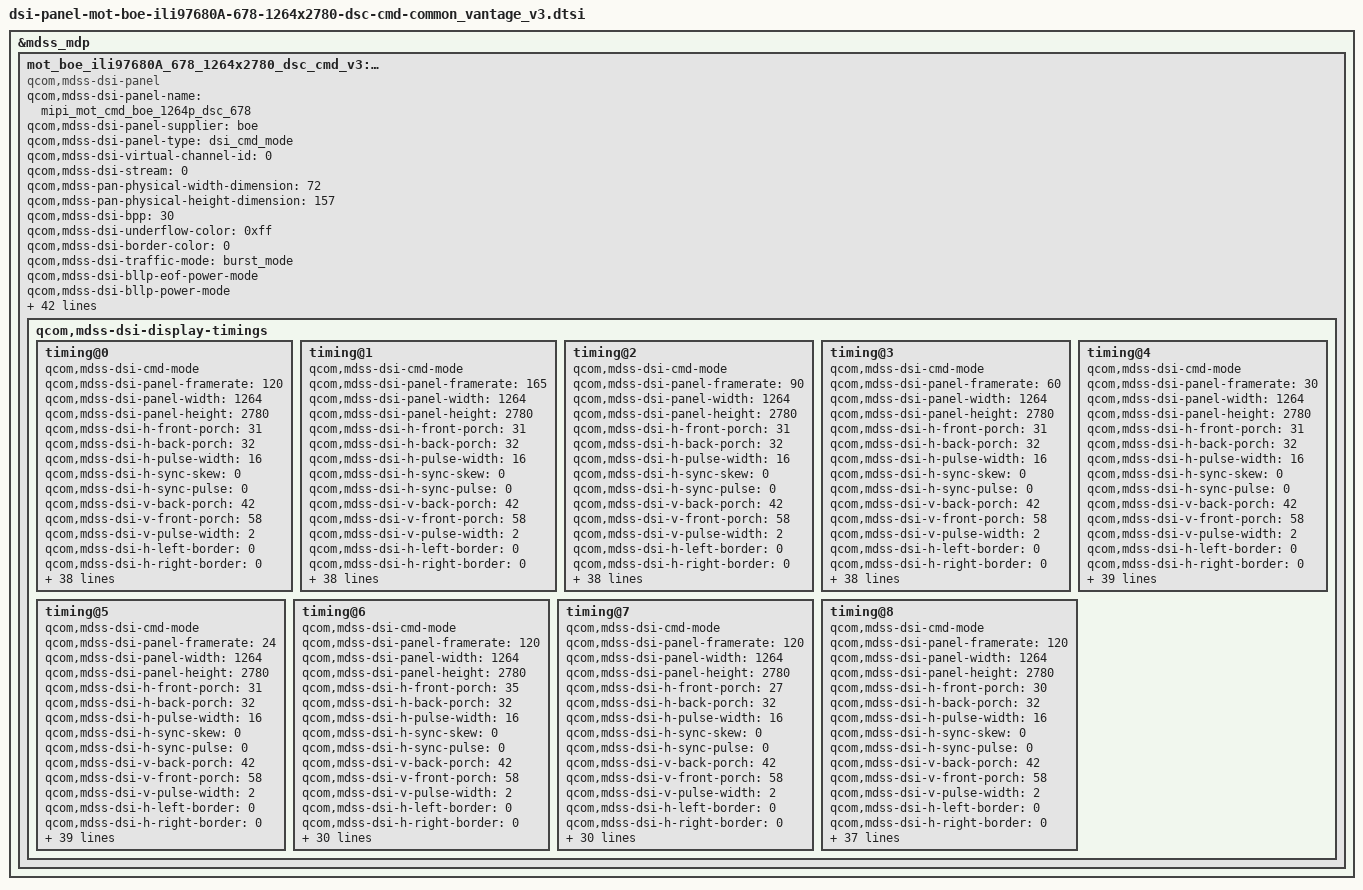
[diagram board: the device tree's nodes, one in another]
/* Copyright (c) 2025-2026, The Linux Foundation. All rights reserved.
 *
 * This program is free software; you can redistribute it and/or modify
 * it under the terms of the GNU General Public License version 2 and
 * only version 2 as published by the Free Software Foundation.
 *
 * This program is distributed in the hope that it will be useful,
 * but WITHOUT ANY WARRANTY; without even the implied warranty of
 * MERCHANTABILITY or FITNESS FOR A PARTICULAR PURPOSE.  See the
 * GNU General Public License for more details.
 */
&mdss_mdp {
mot_boe_ili97680A_678_1264x2780_dsc_cmd_v3: qcom,mdss_dsi_mot_boe_ili97680A_678_1264x2780_dsc_cmd_v3 {
compatible = "qcom,mdss-dsi-panel";
qcom,mdss-dsi-panel-name = "mipi_mot_cmd_boe_1264p_dsc_678";
qcom,mdss-dsi-panel-supplier = "boe";
qcom,mdss-dsi-panel-type = "dsi_cmd_mode";
qcom,mdss-dsi-virtual-channel-id = <0>;
qcom,mdss-dsi-stream = <0>;
qcom,mdss-pan-physical-width-dimension = <72>;
qcom,mdss-pan-physical-height-dimension = <157>;
qcom,mdss-dsi-bpp = <30>;
qcom,mdss-dsi-underflow-color = <0xff>;
qcom,mdss-dsi-border-color = <0>;

qcom,mdss-dsi-traffic-mode = "burst_mode";
qcom,mdss-dsi-bllp-eof-power-mode;
qcom,mdss-dsi-bllp-power-mode;
qcom,mdss-dsi-lane-0-state;
qcom,mdss-dsi-lane-1-state;
qcom,mdss-dsi-lane-2-state;
qcom,mdss-dsi-lane-3-state;

qcom,mdss-dsi-dma-trigger = "trigger_sw";
qcom,mdss-dsi-mdp-trigger = "none";
qcom,mdss-dsi-reset-sequence = <0 3>, <1 1>, <0 1>, <1 20>;
qcom,mdss-dsi-lp11-init;
qcom,mdss-dsi-tx-eot-append;
qcom,mdss-dsi-te-pin-select = <1>;
qcom,mdss-dsi-te-dcs-command = <1>;
qcom,mdss-dsi-te-using-te-pin;

//qcom,bklt-dcs-2bytes-enabled;
qcom,mdss-dsi-bl-min-level = <4>;
qcom,mdss-dsi-bl-max-level = <14056>;
qcom,mdss-dsi-bl-pmic-control-type = "bl_ctrl_dcs";

qcom,mdss-dsi-panel-hdr-enabled;
qcom,mdss-dsi-panel-hdr-color-primaries = <14500 15500 32000
	        17000 15500 30000 8000 3000>;
qcom,mdss-dsi-panel-peak-brightness = <4200000>;

qcom,mdss-dsi-panel-blackness-level = <3230>;

qcom,check_pcd;
qcom,pcd-reg-read-enabled;
qcom,pcd-reg-check-before-read;
qcom,mdss-dsi-panel-pcd-reg-read-length = <1>;
qcom,mdss-dsi-panel-pcd-reg-mask = <0xFF>;
qcom,mdss-dsi-panel-pcd-reg-command = [
		06 01 00 01 00 00 01 C5];
qcom,mdss-dsi-panel-pcd-reg-pass-min = <0x0>;
qcom,mdss-dsi-panel-pcd-reg-pass-max = <0x29>;
qcom,mdss-dsi-panel-pcd-reg-read-delay-ms = <0>; //150ms delay before read pcd reg per IC req
qcom,mdss-dsi-panel-pcd-reg-seq-interval = <30>; //30 seq interval per screen on times
qcom,mdss-dsi-panel-pcd-check-time-interval-in-minutes = <480>; //480 minutes check time interval for pcd reg read

qcom,mdss-dsi-dc-off-command = [
			39 00 00 40 00 00 04 FF 5A A5 4F
			39 00 00 40 00 00 02 81 0C
			39 00 00 40 00 00 02 82 7F
			39 00 00 40 00 00 04 FF 5A A5 08
			39 00 00 40 00 00 02 98 02
			39 00 00 40 00 00 04 FF 5A A5 4F
			39 00 00 40 00 00 02 88 78
			39 00 00 40 00 00 04 FF 5A A5 24
			39 00 00 40 00 00 05 91 01 27 34 56
			39 00 00 40 00 00 04 FF 5A A5 24
			39 00 00 40 00 00 02 9D 0E
			39 00 00 40 00 00 02 9E 11
			39 00 00 40 00 00 04 FF 5A A5 23
			39 00 00 40 00 00 02 80 50
			39 00 00 40 00 00 04 FF 5A A5 53
			39 00 00 40 00 00 03 85 CC E1
			39 00 00 40 00 00 02 86 3D
			39 00 00 40 00 00 03 95 60 66
			39 00 00 40 00 00 04 FF 5A A5 51
			39 00 00 40 00 00 06 A1 AC AC AC AC 22
			39 00 00 40 00 00 02 FE 22
			39 00 00 40 00 00 06 A2 AC A5 A5 A5 22
			39 00 00 40 00 00 02 FE 22
			39 00 00 40 00 00 06 A3 A5 98 98 98 22
			39 00 00 40 00 00 02 FE 22
			39 00 00 40 00 00 04 FF 5A A5 52
			39 00 00 40 00 00 06 81 E2 94 77 77 00
			39 00 00 40 00 00 02 FE 00
			39 00 00 40 00 00 06 82 77 76 76 76 00
			39 00 00 40 00 00 02 FE 00
			39 00 00 40 00 00 06 83 76 6E 6E 6E 00
			39 00 00 40 00 00 02 FE 00
			39 00 00 40 00 00 04 FF 5A A5 4F
			39 00 00 40 00 00 02 81 04
			39 00 00 40 00 00 04 FF 5A A5 08
			39 00 00 40 00 00 02 98 A6
			39 00 00 40 00 00 04 FF 5A A5 00
			39 00 00 40 00 00 02 00 00
			39 00 00 40 00 00 04 FF 5A A5 4F
			39 00 00 40 00 00 02 8B 78
			39 00 00 00 00 00 04 FF 5A A5 00
		];

qcom,mdss-dsi-dc-off-command-state = "dsi_hs_mode";
qcom,mdss-dsi-dc-on-command = [
			39 00 00 40 00 00 04 FF 5A A5 4F
			39 00 00 40 00 00 02 81 0C
			39 00 00 40 00 00 02 82 7F
			39 00 00 40 00 00 04 FF 5A A5 08
			39 00 00 40 00 00 02 98 02
			39 00 00 40 00 00 04 FF 5A A5 4F
			39 00 00 40 00 00 02 88 78
			39 00 00 40 00 00 04 FF 5A A5 24
			39 00 00 40 00 00 05 91 11 77 44 66
			39 00 00 40 00 00 04 FF 5A A5 24
			39 00 00 40 00 00 02 9D 8E
			39 00 00 40 00 00 02 9E 11
			39 00 00 40 00 00 04 FF 5A A5 23
			39 00 00 40 00 00 02 80 90
			39 00 00 40 00 00 04 FF 5A A5 53
			39 00 00 40 00 00 03 85 CC E3
			39 00 00 40 00 00 02 86 3D
			39 00 00 40 00 00 03 95 88 88
			39 00 00 40 00 00 04 FF 5A A5 51
			39 00 00 40 00 00 06 A1 B2 B2 B5 AE 22
			39 00 00 40 00 00 02 FE 22
			39 00 00 40 00 00 06 A2 AE AC AC AB 22
			39 00 00 40 00 00 02 FE 22
			39 00 00 40 00 00 06 A3 AA 98 98 98 22
			39 00 00 40 00 00 02 FE 22
			39 00 00 40 00 00 04 FF 5A A5 52
			39 00 00 40 00 00 06 81 E3 94 77 77 00
			39 00 00 40 00 00 02 FE 00
			39 00 00 40 00 00 06 82 77 77 77 77 00
			39 00 00 40 00 00 02 FE 00
			39 00 00 40 00 00 06 83 77 6E 6E 6E 00
			39 00 00 40 00 00 02 FE 00
			39 00 00 40 00 00 04 FF 5A A5 4F
			39 00 00 40 00 00 02 81 04
			39 00 00 40 00 00 04 FF 5A A5 08
			39 00 00 40 00 00 02 98 A6
			39 00 00 40 00 00 04 FF 5A A5 00
			39 00 00 40 00 00 02 00 00
			39 00 00 40 00 00 04 FF 5A A5 4F
			39 00 00 40 00 00 02 8B 78
			39 00 00 00 00 00 04 FF 5A A5 00
		];
qcom,mdss-dsi-dc-on-command-state = "dsi_hs_mode";
//qcom,mdss-dsi-nt37705-dc-detect-fps;
//qcom,check_pcd;

qcom,mdss-dsi-display-timings {
	timing@0{
		qcom,mdss-dsi-cmd-mode;
		qcom,mdss-dsi-panel-framerate = <120>;
		qcom,mdss-dsi-panel-width = <1264>;
		qcom,mdss-dsi-panel-height = <2780>;
		qcom,mdss-dsi-h-front-porch = <31>;
		qcom,mdss-dsi-h-back-porch = <32>;
		qcom,mdss-dsi-h-pulse-width = <16>;
		qcom,mdss-dsi-h-sync-skew = <0>;
		qcom,mdss-dsi-h-sync-pulse = <0>;
		qcom,mdss-dsi-v-back-porch = <42>;
		qcom,mdss-dsi-v-front-porch = <58>;
		qcom,mdss-dsi-v-pulse-width = <2>;
		qcom,mdss-dsi-h-left-border = <0>;
		qcom,mdss-dsi-h-right-border = <0>;
		qcom,mdss-dsi-v-top-border = <0>;
		qcom,mdss-dsi-v-bottom-border = <0>;
	        qcom,mdss-dsi-panel-jitter = <0x20 0xa>;
	        qcom,mdss-dsi-timing-switch-command = [
			39 00 00 40 00 00 04 FF 5A A5 00
			39 00 00 40 00 00 02 53 20
			39 00 00 40 00 00 02 60 00
			39 00 00 40 00 00 04 FF 5A A5 24
			39 00 00 40 00 00 02 86 00
			39 00 00 40 00 00 02 8A 00
			39 00 00 40 00 00 04 FF 5A A5 2D
			39 00 00 40 00 00 03 98 00 00
			39 00 00 40 00 00 02 CD 01
			39 00 00 40 00 00 03 83 00 00
			39 00 00 40 00 00 02 F2 00 // 120Hz Frame Skip mode Exit
			39 00 00 40 00 00 04 FF 5A A5 53
			39 00 00 40 00 00 02 86 3D //Exit 165 DC code
			39 00 00 00 00 00 04 FF 5A A5 00
	        ];
		qcom,mdss-dsi-on-command = [
			39 00 00 40 00 00 04 FF 5A A5 00 //ODC dbv420 and 10nit
			39 00 00 40 00 00 02 4D 01
			39 00 00 40 00 00 04 FF 5A A5 4F
			39 00 00 40 00 00 02 A1 00
			39 00 00 40 00 00 02 A2 01
			39 00 00 40 00 00 02 A3 A4
			39 00 00 40 00 00 02 A4 0A
			39 00 00 40 00 00 02 A5 48
			39 00 00 40 00 00 04 FF 5A A5 71
			39 00 00 40 00 00 07 85 00 80 0A F3 00 00
			39 00 00 40 00 00 07 86 00 66 09 8F 04 00
			39 00 00 40 00 00 07 87 00 60 09 36 14 00
			39 00 00 40 00 00 07 88 00 53 08 84 24 00
			39 00 00 40 00 00 07 89 00 46 07 D2 04 00
			39 00 00 40 00 00 07 8A 00 80 18 B3 00 00
			39 00 00 40 00 00 07 8B 00 66 17 C2 04 00
			39 00 00 40 00 00 07 8C 00 60 17 86 14 00
			39 00 00 40 00 00 07 8D 00 53 17 0E 24 00
			39 00 00 40 00 00 07 8E 00 46 16 95 04 00
			39 00 00 40 00 00 07 8F 00 80 26 00 00 00
			39 00 00 40 00 00 07 90 00 66 25 99 04 00
			39 00 00 40 00 00 07 91 00 60 25 80 14 00
			39 00 00 40 00 00 07 92 00 53 25 4C 24 00
			39 00 00 40 00 00 07 93 00 46 25 19 04 00
			39 00 00 40 00 00 07 94 00 80 04 00 00 00
			39 00 00 40 00 00 07 95 00 66 04 00 04 00
			39 00 00 40 00 00 07 96 00 60 04 00 14 00
			39 00 00 40 00 00 07 97 00 53 04 00 24 00
			39 00 00 40 00 00 07 98 00 46 04 00 04 00
			39 00 00 40 00 00 07 99 0C 19 00 80 00 00
			39 00 00 40 00 00 07 9A 0A 7B 00 66 04 00
			39 00 00 40 00 00 07 9B 0A 13 00 60 14 00
			39 00 00 40 00 00 07 9C 09 43 00 53 24 00
			39 00 00 40 00 00 07 9D 08 74 00 46 04 00
			39 00 00 40 00 00 07 9E 04 00 0A 00 00 00
			39 00 00 40 00 00 07 A3 04 00 16 80 00 00
			39 00 00 40 00 00 07 A4 04 00 16 00 04 00
			39 00 00 40 00 00 07 B2 19 EC 00 80 00 00
			39 00 00 40 00 00 07 B3 18 BD 00 66 04 00
			39 00 00 40 00 00 07 B4 18 71 00 60 14 00
			39 00 00 40 00 00 07 B5 17 DA 00 53 24 00
			39 00 00 40 00 00 07 B6 17 42 00 46 04 00
			39 00 00 40 00 00 07 CB 25 B9 00 80 00 00
			39 00 00 40 00 00 07 CC 25 61 00 66 04 00
			39 00 00 40 00 00 07 CD 25 4B 00 60 14 00
			39 00 00 40 00 00 07 CE 25 1F 00 53 24 00
			39 00 00 40 00 00 07 CF 24 F2 00 46 04 00
			39 00 00 40 00 00 07 E4 04 00 00 80 00 00
			39 00 00 40 00 00 07 E5 04 00 00 66 04 00
			39 00 00 40 00 00 07 E6 04 00 00 60 14 00
			39 00 00 40 00 00 07 E7 04 00 00 53 24 00
			39 00 00 40 00 00 07 E8 04 00 00 46 04 00
			39 00 00 40 00 00 04 FF 5A A5 49
			39 00 00 40 00 00 02 E0 01
			39 00 00 40 00 00 04 FF 5A A5 5B
			39 00 00 40 00 00 04 C8 03 06 01
			39 00 00 40 00 00 04 C9 04 07 01
			39 00 00 40 00 00 04 CA 00 00 00
			39 00 00 40 00 00 04 CB 06 07 03
			39 00 00 40 00 00 04 CC 01 00 00
			39 00 00 40 00 00 04 CD 00 00 00
			39 00 00 40 00 00 04 CE 09 09 07
			39 00 00 40 00 00 04 CF 03 02 02
			39 00 00 40 00 00 04 D0 02 01 01
			39 00 00 40 00 00 04 D1 00 00 00
			39 00 00 40 00 00 04 D2 16 12 13
			39 00 00 40 00 00 04 D3 09 07 07
			39 00 00 40 00 00 04 D4 07 06 06
			39 00 00 40 00 00 04 D5 03 03 02
			39 00 00 40 00 00 04 D6 00 00 00
			39 00 00 40 00 00 04 D7 19 15 16
			39 00 00 40 00 00 04 D8 0B 08 08
			39 00 00 40 00 00 04 D9 09 07 07
			39 00 00 40 00 00 04 DA 04 04 03
			39 00 00 40 00 00 04 DB 00 00 00
			39 00 00 40 00 00 04 DC 00 00 00
			39 00 00 40 00 00 04 DD 24 21 1F
			39 00 00 40 00 00 04 DE 13 10 0D
			39 00 00 40 00 00 04 DF 10 0E 0C
			39 00 00 40 00 00 04 E0 09 09 06
			39 00 00 40 00 00 04 E1 01 02 01
			39 00 00 40 00 00 04 E2 00 00 00
			39 00 00 40 00 00 04 E3 00 00 00
			39 00 00 40 00 00 04 E4 2E 2B 26
			39 00 00 40 00 00 04 E5 1B 17 12
			39 00 00 40 00 00 04 E6 18 15 10
			39 00 00 40 00 00 04 E7 0E 0F 09
			39 00 00 40 00 00 04 E8 04 04 01
			39 00 00 40 00 00 04 E9 00 00 00
			39 00 00 40 00 00 04 EA 00 00 00
			39 00 00 40 00 00 04 EB 00 00 00
			39 00 00 40 00 00 04 FF 5A A5 5C
			39 00 00 40 00 00 04 80 02 02 01
			39 00 00 40 00 00 04 81 02 02 01
			39 00 00 40 00 00 04 82 00 00 00
			39 00 00 40 00 00 04 83 04 04 02
			39 00 00 40 00 00 04 84 00 00 00
			39 00 00 40 00 00 04 85 00 00 00
			39 00 00 40 00 00 04 86 08 07 07
			39 00 00 40 00 00 04 87 02 02 01
			39 00 00 40 00 00 04 88 01 01 01
			39 00 00 40 00 00 04 89 00 00 00
			39 00 00 40 00 00 04 8A 13 11 10
			39 00 00 40 00 00 04 8B 07 07 05
			39 00 00 40 00 00 04 8C 06 06 04
			39 00 00 40 00 00 04 8D 01 02 01
			39 00 00 40 00 00 04 8E 00 00 00
			39 00 00 40 00 00 04 8F 16 14 12
			39 00 00 40 00 00 04 90 09 08 06
			39 00 00 40 00 00 04 91 07 07 04
			39 00 00 40 00 00 04 92 02 02 01
			39 00 00 40 00 00 04 93 00 00 00
			39 00 00 40 00 00 04 94 00 00 00
			39 00 00 40 00 00 04 95 30 2C 18
			39 00 00 40 00 00 04 96 0E 0D 08
			39 00 00 40 00 00 04 97 0B 0B 06
			39 00 00 40 00 00 04 98 05 05 01
			39 00 00 40 00 00 04 99 01 01 00
			39 00 00 40 00 00 04 9A 00 00 00
			39 00 00 40 00 00 04 9B 00 00 00
			39 00 00 40 00 00 04 9C 45 33 1D
			39 00 00 40 00 00 04 9D 12 11 09
			39 00 00 40 00 00 04 9E 0F 0F 07
			39 00 00 40 00 00 04 9F 07 08 01
			39 00 00 40 00 00 04 A0 01 01 00
			39 00 00 40 00 00 04 A1 00 00 00
			39 00 00 40 00 00 04 A2 00 00 00
			39 00 00 40 00 00 04 A3 00 00 00
			39 00 00 40 00 00 04 CE 10 18 10
			39 00 00 40 00 00 04 CF 10 18 10

			39 00 00 40 00 00 04 FF 5A A5 06 //esd check
			39 00 00 40 00 00 02 C6 01
			39 00 00 40 00 00 04 FF 5A A5 08
			39 00 00 40 00 00 02 D2 05
			39 00 00 40 00 00 09 ED FF FF FF FF FF FF 45 FF
			39 00 00 40 00 00 09 EE FF FD FF FD F9 FA BE 76
			39 00 00 40 00 00 04 FF 5A A5 00

			39 00 00 40 00 00 04 FF 5A A5 03 //Power on code
			39 00 00 40 00 00 04 90 01 80 23
			39 00 00 40 00 00 04 FF 5A A5 08
			39 00 00 40 00 00 02 E0 22
			39 00 00 40 00 00 04 FF 5A A5 09
			39 00 00 40 00 00 02 A1 03
			39 00 00 40 00 00 04 FF 5A A5 1E
			39 00 00 40 00 00 02 C1 70
			39 00 00 40 00 00 04 FF 5A A5 05
			39 00 00 40 00 00 02 83 01
			39 00 00 40 00 00 02 84 01
			39 00 00 40 00 00 04 FF 5A A5 1C
			39 00 00 40 00 00 15 E1 10 80 9A 65 59 54 69 95 56 6A 55 99 9A 55 55 25 58 55 66 A2
			39 00 00 40 00 00 04 FF 5A A5 20
			39 00 00 40 00 00 02 D5 10
			39 00 00 40 00 00 02 BC 06
			39 00 00 40 00 00 04 FF 5A A5 02
			39 00 00 40 00 00 03 AB AF 86

			39 00 00 40 00 00 04 FF 5A A5 4B //pcd check code
			39 00 00 40 00 00 02 EE 10
			39 00 00 40 00 00 04 FF 5A A5 03
			39 00 00 40 00 00 02 BD D1
			39 00 00 40 00 00 02 BB 29
			39 00 00 40 00 00 04 FF 5A A5 1C
			39 00 00 40 00 00 02 D3 43

			39 00 00 40 00 00 04 FF 5A A5 08
			39 00 00 40 00 00 02 C8 62
			39 00 00 40 00 00 04 FF 5A A5 21
			39 00 00 40 00 00 02 A4 38
			39 00 00 40 00 00 04 FF 5A A5 23
			39 00 00 40 00 00 02 85 15
			39 00 00 40 00 00 04 FF 5A A5 01
			39 00 00 40 00 00 02 FB 08
			39 00 00 40 00 00 04 FF 5A A5 00
			39 00 00 40 00 00 02 5E 01
			39 00 00 40 00 00 02 60 00
			39 00 00 40 00 00 02 61 08
			39 00 00 40 00 00 01 35
			39 00 00 40 00 00 02 53 20
			39 00 00 40 00 00 03 51 00 00

			39 00 00 40 00 00 04 FF 5A A5 24 //DBV Diming
			39 00 00 40 00 00 02 85 31
			39 00 00 40 00 00 02 89 31
			39 00 00 40 00 00 04 FF 5A A5 2D
			39 00 00 40 00 00 02 CE 55
			39 00 00 40 00 00 04 FF 5A A5 5A //OD LUT
			39 00 00 40 00 00 04 80 00 01 00
			39 00 00 40 00 00 04 81 00 02 01
			39 00 00 40 00 00 04 82 00 00 00
			39 00 00 40 00 00 04 83 03 0B 04
			39 00 00 40 00 00 04 84 02 05 00
			39 00 00 40 00 00 04 85 02 05 00
			39 00 00 40 00 00 04 86 11 24 11
			39 00 00 40 00 00 04 87 0B 0A 03
			39 00 00 40 00 00 04 88 09 08 03
			39 00 00 40 00 00 04 89 05 04 03
			39 00 00 40 00 00 04 8A 1A 1E 21
			39 00 00 40 00 00 04 8B 11 0D 0F
			39 00 00 40 00 00 04 8C 11 0B 0D
			39 00 00 40 00 00 04 8D 0B 07 0B
			39 00 00 40 00 00 04 8E 05 04 08
			39 00 00 40 00 00 04 8F 26 26 26
			39 00 00 40 00 00 04 90 15 0E 13
			39 00 00 40 00 00 04 91 14 0C 12
			39 00 00 40 00 00 04 92 0F 08 0F
			39 00 00 40 00 00 04 93 08 05 0B
			39 00 00 40 00 00 04 94 00 00 00
			39 00 00 40 00 00 04 95 3E 32 32
			39 00 00 40 00 00 04 96 24 14 26
			39 00 00 40 00 00 04 97 21 12 21
			39 00 00 40 00 00 04 98 1D 10 20
			39 00 00 40 00 00 04 99 12 0B 16
			39 00 00 40 00 00 04 9A 09 05 0B
			39 00 00 40 00 00 04 9B 06 03 08
			39 00 00 40 00 00 04 9C 32 35 2D
			39 00 00 40 00 00 04 9D 36 19 2C
			39 00 00 40 00 00 04 9E 32 18 30
			39 00 00 40 00 00 04 9F 2A 16 29
			39 00 00 40 00 00 04 A0 1D 12 21
			39 00 00 40 00 00 04 A1 12 09 15
			39 00 00 40 00 00 04 A2 0F 07 11
			39 00 00 40 00 00 04 FF 5A A5 5C
			39 00 00 40 00 00 04 C8 0C 0A 05

			39 00 00 40 00 00 04 FF 5A A5 00 //switch 120hz
			39 00 00 40 00 00 02 53 20
			39 00 00 40 00 00 02 60 00
			39 00 00 40 00 00 04 FF 5A A5 24
			39 00 00 40 00 00 02 86 00
			39 00 00 40 00 00 02 8A 00
			39 00 00 40 00 00 04 FF 5A A5 2D
			39 00 00 40 00 00 03 98 00 00
			39 00 00 40 00 00 02 CD 01
			39 00 00 40 00 00 03 83 00 00
			39 00 00 40 00 00 02 F2 00 // 120Hz Frame Skip mode Exit
			39 00 00 40 00 00 04 FF 5A A5 53
			39 00 00 40 00 00 02 86 3D //Exit 165 DC code
			39 00 00 40 00 00 04 FF 5A A5 00

			39 00 00 40 00 00 04 FF 5A A5 07 //10bit 3.75
			39 00 00 40 00 00 02 8A 01
			39 00 00 40 00 00 03 8B 21 E0
			39 00 00 40 00 00 64 81 00 00 00 00 00 12 00 00 ab 30 80 0a dc 04 f0 00 14 02 78 02 78 02 00 02 57 00 20 01 f8 00 08 00 0d 05 7a 04 4f 18 00 10 e0 07 10 20 00 06 0f 0f 33 0e 1c 2a 38 46 54 62 69 70 77 79 7b 7d 7e 02 02 22 00 2a 40 2a be 3a fc 3a fa 3a f8 3b 38 3b 78 3b b6 4b b6 4b f4 4b f4 6c 34 84 74 00 00 00 00 00 00
			39 00 00 00 00 00 04 FF 5A A5 00

			05 00 00 00 78 00 01 11 //Delay 120ms
			39 00 00 40 00 00 04 FF 5A A5 49 //OD Code
			39 00 00 40 00 00 11 81 D2 00 BC 02 C0 03 24 05 08 07 D4 0C D2 14 74 1B
			39 00 00 40 00 00 13 82 D2 00 BC 02 C0 03 24 05 08 07 D4 0C D2 14 74 1B 00 00
			39 00 00 40 00 00 02 83 0B
			39 00 00 40 00 00 04 FF 5A A5 53
			39 00 00 40 00 00 02 86 3D //Exit 165 DC code
			39 00 00 40 00 00 04 FF 5A A5 51
			39 00 00 40 00 00 07 A1 AC AC AC AC 22 22
			39 00 00 40 00 00 07 A2 AC A5 A5 A5 22 22
			39 00 00 40 00 00 07 A3 A5 98 98 98 22 22
			39 00 00 40 00 00 04 FF 5A A5 52
			39 00 00 40 00 00 07 81 E2 94 77 77 00 00
			39 00 00 40 00 00 07 82 77 76 76 76 00 00
			39 00 00 40 00 00 07 83 76 6E 6E 6E 00 00
			39 00 00 00 00 00 04 FF 5A A5 00
			05 00 00 00 14 00 01 29];	/* display on */
		qcom,mdss-dsi-off-command = [
			39 00 00 40 00 00 04 FF 5A A5 00
			05 00 00 00 14 00 01 28		/* display_off */
			05 00 00 00 BE 00 01 10];	/* enter sleep mode */

		qcom,mdss-dsi-on-command-state = "dsi_lp_mode";
		qcom,mdss-dsi-off-command-state = "dsi_lp_mode";
		qcom,mdss-dsi-timing-switch-command-state = "dsi_lp_mode";
		qcom,compression-mode = "dsc";
		/* Why QCOM doesn't use this, even it used 2 encoder
		 * as for that dsi_sw43404_amoled_cmd, for ex */
		/* qcom,mdss-dsc-encoders = <2>; */
		qcom,mdss-dsc-version = <0x12>;
		qcom,mdss-dsc-slice-height = <20>;
		qcom,mdss-dsc-slice-width = <632>;
		qcom,mdss-dsc-slice-per-pkt = <2>;
		qcom,mdss-dsc-bit-per-component = <10>;
		qcom,mdss-dsc-bit-per-pixel = <8>;
		qcom,mdss-dsc-block-prediction-enable;
		qcom,mdss-dsi-pcd-check-enable-command = [
			39 00 00 00 00 00 04 FF 5A A5 03
			];
		qcom,mdss-dsi-pcd-check-enable-command-state = "dsi_hs_mode";
		qcom,mdss-dsi-pcd-check-disable-command = [
			39 00 00 00 00 00 04 FF 5A A5 00
			];
		qcom,mdss-dsi-pcd-check-disable-command-state = "dsi_hs_mode";
		qcom,mdss-dsi-lp1-command = [
			39 00 00 40 00 00 04 FF 5A A5 00
			39 00 00 40 00 00 02 53 20
			39 00 00 40 00 00 02 60 00
			39 00 00 40 00 00 04 FF 5A A5 24
			39 00 00 40 00 00 02 86 00
			39 00 00 40 00 00 02 8A 00
			39 00 00 40 00 00 04 FF 5A A5 2D
			39 00 00 40 00 00 03 98 00 00
			39 00 00 40 00 00 02 CD 01
			39 00 00 40 00 00 03 83 00 00
			39 00 00 40 00 00 02 F2 00 // 120Hz Frame Skip mode Exit
			39 00 00 40 00 00 04 FF 5A A5 53
			39 00 00 40 00 00 02 86 3D //Exit 165 DC code
			39 00 00 00 00 00 04 FF 5A A5 00
		];
		qcom,mdss-dsi-lp1-command-state =
			"dsi_lp_mode";
		qcom,mdss-dsi-lp2-command = [
			39 00 00 40 00 00 04 FF 5A A5 4F
			39 00 00 40 00 00 02 81 04
			39 00 00 40 00 00 04 FF 5A A5 08
			39 00 00 40 00 00 02 98 02
			39 00 00 40 00 00 04 FF 5A A5 4F
			39 00 00 40 00 00 02 88 78
			39 00 00 40 00 00 04 FF 5A A5 24
			39 00 00 40 00 00 02 86 00
			39 00 00 40 00 00 02 8A 00
			39 00 00 40 00 00 04 FF 5A A5 00
			39 00 00 40 00 00 02 53 20
			39 00 00 40 00 00 02 60 00
			39 00 00 40 00 00 04 FF 5A A5 2D
			39 00 00 40 00 00 03 98 00 00
			39 00 00 40 00 00 02 CD 01
			39 00 00 40 00 00 03 83 77 00
			39 00 00 40 00 00 02 F2 00
			39 00 00 40 00 00 04 FF 5A A5 53
			39 00 00 40 00 00 02 86 3D //Exit 165 DC code
			39 00 00 40 00 00 04 FF 5A A5 08
			39 00 00 40 00 00 02 98 A6
			39 00 00 40 00 00 04 FF 5A A5 00
			39 00 00 40 00 00 02 00 00
			39 00 00 40 00 00 04 FF 5A A5 4F
			39 00 00 40 00 00 02 8B 78
			39 00 00 00 00 00 04 FF 5A A5 00
		];
		qcom,mdss-dsi-lp2-command-state =
			"dsi_lp_mode";
		qcom,mdss-dsi-nolp-command = [
			39 00 00 40 00 00 04 FF 5A A5 00
			39 00 00 40 00 00 02 53 20
			39 00 00 40 00 00 02 60 00
			39 00 00 40 00 00 04 FF 5A A5 24
			39 00 00 40 00 00 02 86 00
			39 00 00 40 00 00 02 8A 00
			39 00 00 40 00 00 04 FF 5A A5 2D
			39 00 00 40 00 00 03 98 00 00
			39 00 00 40 00 00 02 CD 01
			39 00 00 40 00 00 03 83 00 00
			39 00 00 40 00 00 02 F2 00 // 120Hz Frame Skip mode Exit
			39 00 00 40 00 00 04 FF 5A A5 53
			39 00 00 40 00 00 02 86 3D //Exit 165 DC code
			39 00 00 00 00 00 04 FF 5A A5 00
		];
		qcom,mdss-dsi-nolp-command-state =
			"dsi_lp_mode";
	};

	timing@1{
		qcom,mdss-dsi-cmd-mode;
		qcom,mdss-dsi-panel-framerate = <165>;
		qcom,mdss-dsi-panel-width = <1264>;
		qcom,mdss-dsi-panel-height = <2780>;
		qcom,mdss-dsi-h-front-porch = <31>;
		qcom,mdss-dsi-h-back-porch = <32>;
		qcom,mdss-dsi-h-pulse-width = <16>;
		qcom,mdss-dsi-h-sync-skew = <0>;
		qcom,mdss-dsi-h-sync-pulse = <0>;
		qcom,mdss-dsi-v-back-porch = <42>;
		qcom,mdss-dsi-v-front-porch = <58>;
		qcom,mdss-dsi-v-pulse-width = <2>;
		qcom,mdss-dsi-h-left-border = <0>;
		qcom,mdss-dsi-h-right-border = <0>;
		qcom,mdss-dsi-v-top-border = <0>;
		qcom,mdss-dsi-v-bottom-border = <0>;
	        qcom,mdss-dsi-panel-jitter = <0x20 0xa>;
	        qcom,mdss-dsi-timing-switch-command = [
			39 00 00 40 00 00 04 FF 5A A5 2D
			39 00 00 40 00 00 03 98 00 00
			39 00 00 40 00 00 02 CD 01
			39 00 00 40 00 00 03 83 00 00
			39 00 00 40 00 00 02 F2 00 // 120Hz Frame Skip mode Exit
			39 00 00 40 00 00 04 FF 5A A5 24
			39 00 00 40 00 00 02 86 00
			39 00 00 40 00 00 02 8A 00
			39 00 00 40 00 00 04 FF 5A A5 00
			39 00 00 40 00 00 02 53 20
			39 00 00 40 00 00 02 60 06
			39 00 00 40 00 00 04 FF 5A A5 53
			39 00 00 40 00 00 02 86 3D //Exit 165 DC code
			39 00 00 00 07 00 04 FF 5A A5 00
	        ];
		qcom,mdss-dsi-on-command = [
			39 00 00 40 00 00 04 FF 5A A5 00 //ODC dbv420 and 10nit
			39 00 00 40 00 00 02 4D 01
			39 00 00 40 00 00 04 FF 5A A5 4F
			39 00 00 40 00 00 02 A1 00
			39 00 00 40 00 00 02 A2 01
			39 00 00 40 00 00 02 A3 A4
			39 00 00 40 00 00 02 A4 0A
			39 00 00 40 00 00 02 A5 48
			39 00 00 40 00 00 04 FF 5A A5 71
			39 00 00 40 00 00 07 85 00 80 0A F3 00 00
			39 00 00 40 00 00 07 86 00 66 09 8F 04 00
			39 00 00 40 00 00 07 87 00 60 09 36 14 00
			39 00 00 40 00 00 07 88 00 53 08 84 24 00
			39 00 00 40 00 00 07 89 00 46 07 D2 04 00
			39 00 00 40 00 00 07 8A 00 80 18 B3 00 00
			39 00 00 40 00 00 07 8B 00 66 17 C2 04 00
			39 00 00 40 00 00 07 8C 00 60 17 86 14 00
			39 00 00 40 00 00 07 8D 00 53 17 0E 24 00
			39 00 00 40 00 00 07 8E 00 46 16 95 04 00
			39 00 00 40 00 00 07 8F 00 80 26 00 00 00
			39 00 00 40 00 00 07 90 00 66 25 99 04 00
			39 00 00 40 00 00 07 91 00 60 25 80 14 00
			39 00 00 40 00 00 07 92 00 53 25 4C 24 00
			39 00 00 40 00 00 07 93 00 46 25 19 04 00
			39 00 00 40 00 00 07 94 00 80 04 00 00 00
			39 00 00 40 00 00 07 95 00 66 04 00 04 00
			39 00 00 40 00 00 07 96 00 60 04 00 14 00
			39 00 00 40 00 00 07 97 00 53 04 00 24 00
			39 00 00 40 00 00 07 98 00 46 04 00 04 00
			39 00 00 40 00 00 07 99 0C 19 00 80 00 00
			39 00 00 40 00 00 07 9A 0A 7B 00 66 04 00
			39 00 00 40 00 00 07 9B 0A 13 00 60 14 00
			39 00 00 40 00 00 07 9C 09 43 00 53 24 00
			39 00 00 40 00 00 07 9D 08 74 00 46 04 00
			39 00 00 40 00 00 07 9E 04 00 0A 00 00 00
			39 00 00 40 00 00 07 A3 04 00 16 80 00 00
			39 00 00 40 00 00 07 A4 04 00 16 00 04 00
			39 00 00 40 00 00 07 B2 19 EC 00 80 00 00
			39 00 00 40 00 00 07 B3 18 BD 00 66 04 00
			39 00 00 40 00 00 07 B4 18 71 00 60 14 00
			39 00 00 40 00 00 07 B5 17 DA 00 53 24 00
			39 00 00 40 00 00 07 B6 17 42 00 46 04 00
			39 00 00 40 00 00 07 CB 25 B9 00 80 00 00
			39 00 00 40 00 00 07 CC 25 61 00 66 04 00
			39 00 00 40 00 00 07 CD 25 4B 00 60 14 00
			39 00 00 40 00 00 07 CE 25 1F 00 53 24 00
			39 00 00 40 00 00 07 CF 24 F2 00 46 04 00
			39 00 00 40 00 00 07 E4 04 00 00 80 00 00
			39 00 00 40 00 00 07 E5 04 00 00 66 04 00
			39 00 00 40 00 00 07 E6 04 00 00 60 14 00
			39 00 00 40 00 00 07 E7 04 00 00 53 24 00
			39 00 00 40 00 00 07 E8 04 00 00 46 04 00
			39 00 00 40 00 00 04 FF 5A A5 49
			39 00 00 40 00 00 02 E0 01
			39 00 00 40 00 00 04 FF 5A A5 5B
			39 00 00 40 00 00 04 C8 03 06 01
			39 00 00 40 00 00 04 C9 04 07 01
			39 00 00 40 00 00 04 CA 00 00 00
			39 00 00 40 00 00 04 CB 06 07 03
			39 00 00 40 00 00 04 CC 01 00 00
			39 00 00 40 00 00 04 CD 00 00 00
			39 00 00 40 00 00 04 CE 09 09 07
			39 00 00 40 00 00 04 CF 03 02 02
			39 00 00 40 00 00 04 D0 02 01 01
			39 00 00 40 00 00 04 D1 00 00 00
			39 00 00 40 00 00 04 D2 16 12 13
			39 00 00 40 00 00 04 D3 09 07 07
			39 00 00 40 00 00 04 D4 07 06 06
			39 00 00 40 00 00 04 D5 03 03 02
			39 00 00 40 00 00 04 D6 00 00 00
			39 00 00 40 00 00 04 D7 19 15 16
			39 00 00 40 00 00 04 D8 0B 08 08
			39 00 00 40 00 00 04 D9 09 07 07
			39 00 00 40 00 00 04 DA 04 04 03
			39 00 00 40 00 00 04 DB 00 00 00
			39 00 00 40 00 00 04 DC 00 00 00
			39 00 00 40 00 00 04 DD 24 21 1F
			39 00 00 40 00 00 04 DE 13 10 0D
			39 00 00 40 00 00 04 DF 10 0E 0C
			39 00 00 40 00 00 04 E0 09 09 06
			39 00 00 40 00 00 04 E1 01 02 01
			39 00 00 40 00 00 04 E2 00 00 00
			39 00 00 40 00 00 04 E3 00 00 00
			39 00 00 40 00 00 04 E4 2E 2B 26
			39 00 00 40 00 00 04 E5 1B 17 12
			39 00 00 40 00 00 04 E6 18 15 10
			39 00 00 40 00 00 04 E7 0E 0F 09
			39 00 00 40 00 00 04 E8 04 04 01
			39 00 00 40 00 00 04 E9 00 00 00
			39 00 00 40 00 00 04 EA 00 00 00
			39 00 00 40 00 00 04 EB 00 00 00
			39 00 00 40 00 00 04 FF 5A A5 5C
			39 00 00 40 00 00 04 80 02 02 01
			39 00 00 40 00 00 04 81 02 02 01
			39 00 00 40 00 00 04 82 00 00 00
			39 00 00 40 00 00 04 83 04 04 02
			39 00 00 40 00 00 04 84 00 00 00
			39 00 00 40 00 00 04 85 00 00 00
			39 00 00 40 00 00 04 86 08 07 07
			39 00 00 40 00 00 04 87 02 02 01
			39 00 00 40 00 00 04 88 01 01 01
			39 00 00 40 00 00 04 89 00 00 00
			39 00 00 40 00 00 04 8A 13 11 10
			39 00 00 40 00 00 04 8B 07 07 05
			39 00 00 40 00 00 04 8C 06 06 04
			39 00 00 40 00 00 04 8D 01 02 01
			39 00 00 40 00 00 04 8E 00 00 00
			39 00 00 40 00 00 04 8F 16 14 12
			39 00 00 40 00 00 04 90 09 08 06
			39 00 00 40 00 00 04 91 07 07 04
			39 00 00 40 00 00 04 92 02 02 01
			39 00 00 40 00 00 04 93 00 00 00
			39 00 00 40 00 00 04 94 00 00 00
			39 00 00 40 00 00 04 95 30 2C 18
			39 00 00 40 00 00 04 96 0E 0D 08
			39 00 00 40 00 00 04 97 0B 0B 06
			39 00 00 40 00 00 04 98 05 05 01
			39 00 00 40 00 00 04 99 01 01 00
			39 00 00 40 00 00 04 9A 00 00 00
			39 00 00 40 00 00 04 9B 00 00 00
			39 00 00 40 00 00 04 9C 45 33 1D
			39 00 00 40 00 00 04 9D 12 11 09
			39 00 00 40 00 00 04 9E 0F 0F 07
			39 00 00 40 00 00 04 9F 07 08 01
			39 00 00 40 00 00 04 A0 01 01 00
			39 00 00 40 00 00 04 A1 00 00 00
			39 00 00 40 00 00 04 A2 00 00 00
			39 00 00 40 00 00 04 A3 00 00 00
			39 00 00 40 00 00 04 CE 10 18 10
			39 00 00 40 00 00 04 CF 10 18 10

			39 00 00 40 00 00 04 FF 5A A5 06 //esd check
			39 00 00 40 00 00 02 C6 01
			39 00 00 40 00 00 04 FF 5A A5 08
			39 00 00 40 00 00 02 D2 05
			39 00 00 40 00 00 09 ED FF FF FF FF FF FF 45 FF
			39 00 00 40 00 00 09 EE FF FD FF FD F9 FA BE 76
			39 00 00 40 00 00 04 FF 5A A5 00

			39 00 00 40 00 00 04 FF 5A A5 03 //Power on code
			39 00 00 40 00 00 04 90 01 80 23
			39 00 00 40 00 00 04 FF 5A A5 08
			39 00 00 40 00 00 02 E0 22
			39 00 00 40 00 00 04 FF 5A A5 09
			39 00 00 40 00 00 02 A1 03
			39 00 00 40 00 00 04 FF 5A A5 1E
			39 00 00 40 00 00 02 C1 70
			39 00 00 40 00 00 04 FF 5A A5 05
			39 00 00 40 00 00 02 83 01
			39 00 00 40 00 00 02 84 01
			39 00 00 40 00 00 04 FF 5A A5 1C
			39 00 00 40 00 00 15 E1 10 80 9A 65 59 54 69 95 56 6A 55 99 9A 55 55 25 58 55 66 A2
			39 00 00 40 00 00 04 FF 5A A5 20
			39 00 00 40 00 00 02 D5 10
			39 00 00 40 00 00 02 BC 06
			39 00 00 40 00 00 04 FF 5A A5 02
			39 00 00 40 00 00 03 AB AF 86

			39 00 00 40 00 00 04 FF 5A A5 4B //pcd check code
			39 00 00 40 00 00 02 EE 10
			39 00 00 40 00 00 04 FF 5A A5 03
			39 00 00 40 00 00 02 BD D1
			39 00 00 40 00 00 02 BB 29
			39 00 00 40 00 00 04 FF 5A A5 1C
			39 00 00 40 00 00 02 D3 43

			39 00 00 40 00 00 04 FF 5A A5 08
			39 00 00 40 00 00 02 C8 62
			39 00 00 40 00 00 04 FF 5A A5 21
			39 00 00 40 00 00 02 A4 38
			39 00 00 40 00 00 04 FF 5A A5 23
			39 00 00 40 00 00 02 85 15
			39 00 00 40 00 00 04 FF 5A A5 01
			39 00 00 40 00 00 02 FB 08
			39 00 00 40 00 00 04 FF 5A A5 00
			39 00 00 40 00 00 02 5E 01
			39 00 00 40 00 00 02 60 00
			39 00 00 40 00 00 02 61 08
			39 00 00 40 00 00 01 35
			39 00 00 40 00 00 02 53 20
			39 00 00 40 00 00 03 51 00 00

			39 00 00 40 00 00 04 FF 5A A5 24 //DBV Diming
			39 00 00 40 00 00 02 85 31
			39 00 00 40 00 00 02 89 31
			39 00 00 40 00 00 04 FF 5A A5 2D
			39 00 00 40 00 00 02 CE 55
			39 00 00 40 00 00 04 FF 5A A5 5A //OD LUT
			39 00 00 40 00 00 04 80 00 01 00
			39 00 00 40 00 00 04 81 00 02 01
			39 00 00 40 00 00 04 82 00 00 00
			39 00 00 40 00 00 04 83 03 0B 04
			39 00 00 40 00 00 04 84 02 05 00
			39 00 00 40 00 00 04 85 02 05 00
			39 00 00 40 00 00 04 86 11 24 11
			39 00 00 40 00 00 04 87 0B 0A 03
			39 00 00 40 00 00 04 88 09 08 03
			39 00 00 40 00 00 04 89 05 04 03
			39 00 00 40 00 00 04 8A 1A 1E 21
			39 00 00 40 00 00 04 8B 11 0D 0F
			39 00 00 40 00 00 04 8C 11 0B 0D
			39 00 00 40 00 00 04 8D 0B 07 0B
			39 00 00 40 00 00 04 8E 05 04 08
			39 00 00 40 00 00 04 8F 26 26 26
			39 00 00 40 00 00 04 90 15 0E 13
			39 00 00 40 00 00 04 91 14 0C 12
			39 00 00 40 00 00 04 92 0F 08 0F
			39 00 00 40 00 00 04 93 08 05 0B
			39 00 00 40 00 00 04 94 00 00 00
			39 00 00 40 00 00 04 95 3E 32 32
			39 00 00 40 00 00 04 96 24 14 26
			39 00 00 40 00 00 04 97 21 12 21
			39 00 00 40 00 00 04 98 1D 10 20
			39 00 00 40 00 00 04 99 12 0B 16
			39 00 00 40 00 00 04 9A 09 05 0B
			39 00 00 40 00 00 04 9B 06 03 08
			39 00 00 40 00 00 04 9C 32 35 2D
			39 00 00 40 00 00 04 9D 36 19 2C
			39 00 00 40 00 00 04 9E 32 18 30
			39 00 00 40 00 00 04 9F 2A 16 29
			39 00 00 40 00 00 04 A0 1D 12 21
			39 00 00 40 00 00 04 A1 12 09 15
			39 00 00 40 00 00 04 A2 0F 07 11
			39 00 00 40 00 00 04 FF 5A A5 5C
			39 00 00 40 00 00 04 C8 0C 0A 05

			39 00 00 40 00 00 04 FF 5A A5 2D //switch normal 165hz
			39 00 00 40 00 00 03 98 00 00
			39 00 00 40 00 00 02 CD 01
			39 00 00 40 00 00 03 83 00 00
			39 00 00 40 00 00 02 F2 00 // 120Hz Frame Skip mode Exit
			39 00 00 40 00 00 04 FF 5A A5 24
			39 00 00 40 00 00 02 86 00
			39 00 00 40 00 00 02 8A 00
			39 00 00 40 00 00 04 FF 5A A5 00
			39 00 00 40 00 00 02 53 20
			39 00 00 40 00 00 02 60 06
			39 00 00 40 00 00 04 FF 5A A5 53
			39 00 00 40 00 00 02 86 3D //Exit 165 DC code
			39 00 00 00 00 00 04 FF 5A A5 00

			39 00 00 40 00 00 04 FF 5A A5 07 //10bit 3.75
			39 00 00 40 00 00 02 8A 01
			39 00 00 40 00 00 03 8B 21 E0
			39 00 00 40 00 00 64 81 00 00 00 00 00 12 00 00 ab 30 80 0a dc 04 f0 00 14 02 78 02 78 02 00 02 57 00 20 01 f8 00 08 00 0d 05 7a 04 4f 18 00 10 e0 07 10 20 00 06 0f 0f 33 0e 1c 2a 38 46 54 62 69 70 77 79 7b 7d 7e 02 02 22 00 2a 40 2a be 3a fc 3a fa 3a f8 3b 38 3b 78 3b b6 4b b6 4b f4 4b f4 6c 34 84 74 00 00 00 00 00 00 //Delay 10ms
			39 00 00 00 00 00 04 FF 5A A5 00

			05 00 00 00 78 00 01 11 //Delay 120ms
			39 00 00 40 00 00 04 FF 5A A5 49 //OD Code
			39 00 00 40 00 00 11 81 D2 00 BC 02 C0 03 24 05 08 07 D4 0C D2 14 74 1B
			39 00 00 40 00 00 13 82 D2 00 BC 02 C0 03 24 05 08 07 D4 0C D2 14 74 1B 00 00
			39 00 00 40 00 00 02 83 0B
			39 00 00 40 00 00 04 FF 5A A5 53
			39 00 00 40 00 00 02 86 3D //Exit 165 DC code
			39 00 00 40 00 00 04 FF 5A A5 51
			39 00 00 40 00 00 07 A1 AC AC AC AC 22 22
			39 00 00 40 00 00 07 A2 AC A5 A5 A5 22 22
			39 00 00 40 00 00 07 A3 A5 98 98 98 22 22
			39 00 00 40 00 00 04 FF 5A A5 52
			39 00 00 40 00 00 07 81 E2 94 77 77 00 00
			39 00 00 40 00 00 07 82 77 76 76 76 00 00
			39 00 00 40 00 00 07 83 76 6E 6E 6E 00 00
			39 00 00 00 00 00 04 FF 5A A5 00
			05 00 00 00 14 00 01 29];	/* display on */
		qcom,mdss-dsi-off-command = [
			39 00 00 40 00 00 04 FF 5A A5 00
			05 00 00 00 14 00 01 28		/* display_off */
			05 00 00 00 BE 00 01 10];	/* enter sleep mode */

		qcom,mdss-dsi-on-command-state = "dsi_lp_mode";
		qcom,mdss-dsi-off-command-state = "dsi_lp_mode";
		qcom,mdss-dsi-timing-switch-command-state = "dsi_lp_mode";
		qcom,compression-mode = "dsc";
		/* Why QCOM doesn't use this, even it used 2 encoder
		 * as for that dsi_sw43404_amoled_cmd, for ex */
		/* qcom,mdss-dsc-encoders = <2>; */
		qcom,mdss-dsc-version = <0x12>;
		qcom,mdss-dsc-slice-height = <20>;
		qcom,mdss-dsc-slice-width = <632>;
		qcom,mdss-dsc-slice-per-pkt = <2>;
		qcom,mdss-dsc-bit-per-component = <10>;
		qcom,mdss-dsc-bit-per-pixel = <8>;
		qcom,mdss-dsc-block-prediction-enable;
		qcom,mdss-dsi-pcd-check-enable-command = [
			39 00 00 00 00 00 04 FF 5A A5 03
			];
		qcom,mdss-dsi-pcd-check-enable-command-state = "dsi_hs_mode";
		qcom,mdss-dsi-pcd-check-disable-command = [
			39 00 00 00 00 00 04 FF 5A A5 00
			];
		qcom,mdss-dsi-pcd-check-disable-command-state = "dsi_hs_mode";
		qcom,mdss-dsi-lp1-command = [
			39 00 00 40 00 00 04 FF 5A A5 2D
			39 00 00 40 00 00 03 98 00 00
			39 00 00 40 00 00 02 CD 01
			39 00 00 40 00 00 03 83 00 00
			39 00 00 40 00 00 02 F2 00 // 120Hz Frame Skip mode Exit
			39 00 00 40 00 00 04 FF 5A A5 24
			39 00 00 40 00 00 02 86 00
			39 00 00 40 00 00 02 8A 00
			39 00 00 40 00 00 04 FF 5A A5 00
			39 00 00 40 00 00 02 53 20
			39 00 00 40 00 00 02 60 06
			39 00 00 40 00 00 04 FF 5A A5 53
			39 00 00 40 00 00 02 86 3D //Exit 165 DC code
			39 00 00 00 00 00 04 FF 5A A5 00
		];
		qcom,mdss-dsi-lp1-command-state =
			"dsi_lp_mode";
		qcom,mdss-dsi-lp2-command = [
			39 00 00 40 00 00 04 FF 5A A5 4F
			39 00 00 40 00 00 02 81 04
			39 00 00 40 00 00 04 FF 5A A5 08
			39 00 00 40 00 00 02 98 02
			39 00 00 40 00 00 04 FF 5A A5 4F
			39 00 00 40 00 00 02 88 78
			39 00 00 40 00 00 04 FF 5A A5 24
			39 00 00 40 00 00 02 86 00
			39 00 00 40 00 00 02 8A 00
			39 00 00 40 00 00 04 FF 5A A5 00
			39 00 00 40 00 00 02 53 20
			39 00 00 40 00 00 02 60 00
			39 00 00 40 00 00 04 FF 5A A5 2D
			39 00 00 40 00 00 03 98 00 00
			39 00 00 40 00 00 02 CD 01
			39 00 00 40 00 00 03 83 77 00
			39 00 00 40 00 00 02 F2 00
			39 00 00 40 00 00 04 FF 5A A5 53
			39 00 00 40 00 00 02 86 3D //Exit 165 DC code
			39 00 00 40 00 00 04 FF 5A A5 08
			39 00 00 40 00 00 02 98 A6
			39 00 00 40 00 00 04 FF 5A A5 00
			39 00 00 40 00 00 02 00 00
			39 00 00 40 00 00 04 FF 5A A5 4F
			39 00 00 40 00 00 02 8B 78
			39 00 00 00 00 00 04 FF 5A A5 00
		];
		qcom,mdss-dsi-lp2-command-state =
			"dsi_lp_mode";
		qcom,mdss-dsi-nolp-command = [
			39 00 00 40 00 00 04 FF 5A A5 2D
			39 00 00 40 00 00 03 98 00 00
			39 00 00 40 00 00 02 CD 01
			39 00 00 40 00 00 03 83 00 00
			39 00 00 40 00 00 02 F2 00 // 120Hz Frame Skip mode Exit
			39 00 00 40 00 00 04 FF 5A A5 24
			39 00 00 40 00 00 02 86 00
			39 00 00 40 00 00 02 8A 00
			39 00 00 40 00 00 04 FF 5A A5 00
			39 00 00 40 00 00 02 53 20
			39 00 00 40 00 00 02 60 06
			39 00 00 40 00 00 04 FF 5A A5 53
			39 00 00 40 00 00 02 86 3D //Exit 165 DC code
			39 00 00 00 00 00 04 FF 5A A5 00
		];
		qcom,mdss-dsi-nolp-command-state =
			"dsi_lp_mode";
	};

	timing@2{
		qcom,mdss-dsi-cmd-mode;
		qcom,mdss-dsi-panel-framerate = <90>;
		qcom,mdss-dsi-panel-width = <1264>;
		qcom,mdss-dsi-panel-height = <2780>;
		qcom,mdss-dsi-h-front-porch = <31>;
		qcom,mdss-dsi-h-back-porch = <32>;
		qcom,mdss-dsi-h-pulse-width = <16>;
		qcom,mdss-dsi-h-sync-skew = <0>;
		qcom,mdss-dsi-h-sync-pulse = <0>;
		qcom,mdss-dsi-v-back-porch = <42>;
		qcom,mdss-dsi-v-front-porch = <58>;
		qcom,mdss-dsi-v-pulse-width = <2>;
		qcom,mdss-dsi-h-left-border = <0>;
		qcom,mdss-dsi-h-right-border = <0>;
		qcom,mdss-dsi-v-top-border = <0>;
		qcom,mdss-dsi-v-bottom-border = <0>;
	        qcom,mdss-dsi-panel-jitter = <0x20 0xa>;
	        qcom,mdss-dsi-timing-switch-command = [
			39 00 00 40 00 00 04 FF 5A A5 00
			39 00 00 40 00 00 02 53 20
			39 00 00 40 00 00 02 60 00
			39 00 00 40 00 00 04 FF 5A A5 24
			39 00 00 40 00 00 02 86 00
			39 00 00 40 00 00 02 8A 00
			39 00 00 40 00 00 04 FF 5A A5 2D
			39 00 00 40 00 00 03 98 00 00
			39 00 00 40 00 00 02 CD 01
			39 00 00 40 00 00 03 83 00 00
			39 00 00 40 00 00 02 F2 00 // 120Hz Frame Skip mode Exit
			39 00 00 40 00 00 04 FF 5A A5 53
			39 00 00 40 00 00 02 86 3D //Exit 165 DC code
			39 00 00 00 1C 00 04 FF 5A A5 00

			39 00 00 40 00 00 04 FF 5A A5 2D
			39 00 00 40 00 00 03 98 00 00
			39 00 00 40 00 00 02 CD 01
			39 00 00 40 00 00 03 83 00 00
			39 00 00 40 00 00 02 F2 00 // 120Hz Frame Skip mode Exit
			39 00 00 40 00 00 04 FF 5A A5 24
			39 00 00 40 00 00 02 86 00
			39 00 00 40 00 00 02 8A 00
			39 00 00 40 00 00 04 FF 5A A5 00
			39 00 00 40 00 00 02 53 20
			39 00 00 40 00 00 02 60 02
			39 00 00 40 00 00 04 FF 5A A5 53
			39 00 00 40 00 00 02 86 3D //Exit 165 DC code
			39 00 00 00 00 00 04 FF 5A A5 00
	        ];
		qcom,mdss-dsi-on-command = [
			39 00 00 40 00 00 04 FF 5A A5 00 //ODC dbv420 and 10nit
			39 00 00 40 00 00 02 4D 01
			39 00 00 40 00 00 04 FF 5A A5 4F
			39 00 00 40 00 00 02 A1 00
			39 00 00 40 00 00 02 A2 01
			39 00 00 40 00 00 02 A3 A4
			39 00 00 40 00 00 02 A4 0A
			39 00 00 40 00 00 02 A5 48
			39 00 00 40 00 00 04 FF 5A A5 71
			39 00 00 40 00 00 07 85 00 80 0A F3 00 00
			39 00 00 40 00 00 07 86 00 66 09 8F 04 00
			39 00 00 40 00 00 07 87 00 60 09 36 14 00
			39 00 00 40 00 00 07 88 00 53 08 84 24 00
			39 00 00 40 00 00 07 89 00 46 07 D2 04 00
			39 00 00 40 00 00 07 8A 00 80 18 B3 00 00
			39 00 00 40 00 00 07 8B 00 66 17 C2 04 00
			39 00 00 40 00 00 07 8C 00 60 17 86 14 00
			39 00 00 40 00 00 07 8D 00 53 17 0E 24 00
			39 00 00 40 00 00 07 8E 00 46 16 95 04 00
			39 00 00 40 00 00 07 8F 00 80 26 00 00 00
			39 00 00 40 00 00 07 90 00 66 25 99 04 00
			39 00 00 40 00 00 07 91 00 60 25 80 14 00
			39 00 00 40 00 00 07 92 00 53 25 4C 24 00
			39 00 00 40 00 00 07 93 00 46 25 19 04 00
			39 00 00 40 00 00 07 94 00 80 04 00 00 00
			39 00 00 40 00 00 07 95 00 66 04 00 04 00
			39 00 00 40 00 00 07 96 00 60 04 00 14 00
			39 00 00 40 00 00 07 97 00 53 04 00 24 00
			39 00 00 40 00 00 07 98 00 46 04 00 04 00
			39 00 00 40 00 00 07 99 0C 19 00 80 00 00
			39 00 00 40 00 00 07 9A 0A 7B 00 66 04 00
			39 00 00 40 00 00 07 9B 0A 13 00 60 14 00
			39 00 00 40 00 00 07 9C 09 43 00 53 24 00
			39 00 00 40 00 00 07 9D 08 74 00 46 04 00
			39 00 00 40 00 00 07 9E 04 00 0A 00 00 00
			39 00 00 40 00 00 07 A3 04 00 16 80 00 00
			39 00 00 40 00 00 07 A4 04 00 16 00 04 00
			39 00 00 40 00 00 07 B2 19 EC 00 80 00 00
			39 00 00 40 00 00 07 B3 18 BD 00 66 04 00
			39 00 00 40 00 00 07 B4 18 71 00 60 14 00
			39 00 00 40 00 00 07 B5 17 DA 00 53 24 00
			39 00 00 40 00 00 07 B6 17 42 00 46 04 00
			39 00 00 40 00 00 07 CB 25 B9 00 80 00 00
			39 00 00 40 00 00 07 CC 25 61 00 66 04 00
			39 00 00 40 00 00 07 CD 25 4B 00 60 14 00
			39 00 00 40 00 00 07 CE 25 1F 00 53 24 00
			39 00 00 40 00 00 07 CF 24 F2 00 46 04 00
			39 00 00 40 00 00 07 E4 04 00 00 80 00 00
			39 00 00 40 00 00 07 E5 04 00 00 66 04 00
			39 00 00 40 00 00 07 E6 04 00 00 60 14 00
			39 00 00 40 00 00 07 E7 04 00 00 53 24 00
			39 00 00 40 00 00 07 E8 04 00 00 46 04 00
			39 00 00 40 00 00 04 FF 5A A5 49
			39 00 00 40 00 00 02 E0 01
			39 00 00 40 00 00 04 FF 5A A5 5B
			39 00 00 40 00 00 04 C8 03 06 01
			39 00 00 40 00 00 04 C9 04 07 01
			39 00 00 40 00 00 04 CA 00 00 00
			39 00 00 40 00 00 04 CB 06 07 03
			39 00 00 40 00 00 04 CC 01 00 00
			39 00 00 40 00 00 04 CD 00 00 00
			39 00 00 40 00 00 04 CE 09 09 07
			39 00 00 40 00 00 04 CF 03 02 02
			39 00 00 40 00 00 04 D0 02 01 01
			39 00 00 40 00 00 04 D1 00 00 00
			39 00 00 40 00 00 04 D2 16 12 13
			39 00 00 40 00 00 04 D3 09 07 07
			39 00 00 40 00 00 04 D4 07 06 06
			39 00 00 40 00 00 04 D5 03 03 02
			39 00 00 40 00 00 04 D6 00 00 00
			39 00 00 40 00 00 04 D7 19 15 16
			39 00 00 40 00 00 04 D8 0B 08 08
			39 00 00 40 00 00 04 D9 09 07 07
			39 00 00 40 00 00 04 DA 04 04 03
			39 00 00 40 00 00 04 DB 00 00 00
			39 00 00 40 00 00 04 DC 00 00 00
			39 00 00 40 00 00 04 DD 24 21 1F
			39 00 00 40 00 00 04 DE 13 10 0D
			39 00 00 40 00 00 04 DF 10 0E 0C
			39 00 00 40 00 00 04 E0 09 09 06
			39 00 00 40 00 00 04 E1 01 02 01
			39 00 00 40 00 00 04 E2 00 00 00
			39 00 00 40 00 00 04 E3 00 00 00
			39 00 00 40 00 00 04 E4 2E 2B 26
			39 00 00 40 00 00 04 E5 1B 17 12
			39 00 00 40 00 00 04 E6 18 15 10
			39 00 00 40 00 00 04 E7 0E 0F 09
			39 00 00 40 00 00 04 E8 04 04 01
			39 00 00 40 00 00 04 E9 00 00 00
			39 00 00 40 00 00 04 EA 00 00 00
			39 00 00 40 00 00 04 EB 00 00 00
			39 00 00 40 00 00 04 FF 5A A5 5C
			39 00 00 40 00 00 04 80 02 02 01
			39 00 00 40 00 00 04 81 02 02 01
			39 00 00 40 00 00 04 82 00 00 00
			39 00 00 40 00 00 04 83 04 04 02
			39 00 00 40 00 00 04 84 00 00 00
			39 00 00 40 00 00 04 85 00 00 00
			39 00 00 40 00 00 04 86 08 07 07
			39 00 00 40 00 00 04 87 02 02 01
			39 00 00 40 00 00 04 88 01 01 01
			39 00 00 40 00 00 04 89 00 00 00
			39 00 00 40 00 00 04 8A 13 11 10
			39 00 00 40 00 00 04 8B 07 07 05
			39 00 00 40 00 00 04 8C 06 06 04
			39 00 00 40 00 00 04 8D 01 02 01
			39 00 00 40 00 00 04 8E 00 00 00
			39 00 00 40 00 00 04 8F 16 14 12
			39 00 00 40 00 00 04 90 09 08 06
			39 00 00 40 00 00 04 91 07 07 04
			39 00 00 40 00 00 04 92 02 02 01
			39 00 00 40 00 00 04 93 00 00 00
			39 00 00 40 00 00 04 94 00 00 00
			39 00 00 40 00 00 04 95 30 2C 18
			39 00 00 40 00 00 04 96 0E 0D 08
			39 00 00 40 00 00 04 97 0B 0B 06
			39 00 00 40 00 00 04 98 05 05 01
			39 00 00 40 00 00 04 99 01 01 00
			39 00 00 40 00 00 04 9A 00 00 00
			39 00 00 40 00 00 04 9B 00 00 00
			39 00 00 40 00 00 04 9C 45 33 1D
			39 00 00 40 00 00 04 9D 12 11 09
			39 00 00 40 00 00 04 9E 0F 0F 07
			39 00 00 40 00 00 04 9F 07 08 01
			39 00 00 40 00 00 04 A0 01 01 00
			39 00 00 40 00 00 04 A1 00 00 00
			39 00 00 40 00 00 04 A2 00 00 00
			39 00 00 40 00 00 04 A3 00 00 00
			39 00 00 40 00 00 04 CE 10 18 10
			39 00 00 40 00 00 04 CF 10 18 10

			39 00 00 40 00 00 04 FF 5A A5 06 //esd check
			39 00 00 40 00 00 02 C6 01
			39 00 00 40 00 00 04 FF 5A A5 08
			39 00 00 40 00 00 02 D2 05
			39 00 00 40 00 00 09 ED FF FF FF FF FF FF 45 FF
			39 00 00 40 00 00 09 EE FF FD FF FD F9 FA BE 76
			39 00 00 40 00 00 04 FF 5A A5 00

			39 00 00 40 00 00 04 FF 5A A5 03 //Power on code
			39 00 00 40 00 00 04 90 01 80 23
			39 00 00 40 00 00 04 FF 5A A5 08
			39 00 00 40 00 00 02 E0 22
			39 00 00 40 00 00 04 FF 5A A5 09
			39 00 00 40 00 00 02 A1 03
			39 00 00 40 00 00 04 FF 5A A5 1E
			39 00 00 40 00 00 02 C1 70
			39 00 00 40 00 00 04 FF 5A A5 05
			39 00 00 40 00 00 02 83 01
			39 00 00 40 00 00 02 84 01
			39 00 00 40 00 00 04 FF 5A A5 1C
			39 00 00 40 00 00 15 E1 10 80 9A 65 59 54 69 95 56 6A 55 99 9A 55 55 25 58 55 66 A2
			39 00 00 40 00 00 04 FF 5A A5 20
			39 00 00 40 00 00 02 D5 10
			39 00 00 40 00 00 02 BC 06
			39 00 00 40 00 00 04 FF 5A A5 02
			39 00 00 40 00 00 03 AB AF 86

			39 00 00 40 00 00 04 FF 5A A5 4B //pcd check code
			39 00 00 40 00 00 02 EE 10
			39 00 00 40 00 00 04 FF 5A A5 03
			39 00 00 40 00 00 02 BD D1
			39 00 00 40 00 00 02 BB 29
			39 00 00 40 00 00 04 FF 5A A5 1C
			39 00 00 40 00 00 02 D3 43

			39 00 00 40 00 00 04 FF 5A A5 08
			39 00 00 40 00 00 02 C8 62
			39 00 00 40 00 00 04 FF 5A A5 21
			39 00 00 40 00 00 02 A4 38
			39 00 00 40 00 00 04 FF 5A A5 23
			39 00 00 40 00 00 02 85 15
			39 00 00 40 00 00 04 FF 5A A5 01
			39 00 00 40 00 00 02 FB 08
			39 00 00 40 00 00 04 FF 5A A5 00
			39 00 00 40 00 00 02 5E 01
			39 00 00 40 00 00 02 60 00
			39 00 00 40 00 00 02 61 08
			39 00 00 40 00 00 01 35
			39 00 00 40 00 00 02 53 20
			39 00 00 40 00 00 03 51 00 00

			39 00 00 40 00 00 04 FF 5A A5 24 //DBV Diming
			39 00 00 40 00 00 02 85 31
			39 00 00 40 00 00 02 89 31
			39 00 00 40 00 00 04 FF 5A A5 2D
			39 00 00 40 00 00 02 CE 55
			39 00 00 40 00 00 04 FF 5A A5 5A //OD LUT
			39 00 00 40 00 00 04 80 00 01 00
			39 00 00 40 00 00 04 81 00 02 01
			39 00 00 40 00 00 04 82 00 00 00
			39 00 00 40 00 00 04 83 03 0B 04
			39 00 00 40 00 00 04 84 02 05 00
			39 00 00 40 00 00 04 85 02 05 00
			39 00 00 40 00 00 04 86 11 24 11
			39 00 00 40 00 00 04 87 0B 0A 03
			39 00 00 40 00 00 04 88 09 08 03
			39 00 00 40 00 00 04 89 05 04 03
			39 00 00 40 00 00 04 8A 1A 1E 21
			39 00 00 40 00 00 04 8B 11 0D 0F
			39 00 00 40 00 00 04 8C 11 0B 0D
			39 00 00 40 00 00 04 8D 0B 07 0B
			39 00 00 40 00 00 04 8E 05 04 08
			39 00 00 40 00 00 04 8F 26 26 26
			39 00 00 40 00 00 04 90 15 0E 13
			39 00 00 40 00 00 04 91 14 0C 12
			39 00 00 40 00 00 04 92 0F 08 0F
			39 00 00 40 00 00 04 93 08 05 0B
			39 00 00 40 00 00 04 94 00 00 00
			39 00 00 40 00 00 04 95 3E 32 32
			39 00 00 40 00 00 04 96 24 14 26
			39 00 00 40 00 00 04 97 21 12 21
			39 00 00 40 00 00 04 98 1D 10 20
			39 00 00 40 00 00 04 99 12 0B 16
			39 00 00 40 00 00 04 9A 09 05 0B
			39 00 00 40 00 00 04 9B 06 03 08
			39 00 00 40 00 00 04 9C 32 35 2D
			39 00 00 40 00 00 04 9D 36 19 2C
			39 00 00 40 00 00 04 9E 32 18 30
			39 00 00 40 00 00 04 9F 2A 16 29
			39 00 00 40 00 00 04 A0 1D 12 21
			39 00 00 40 00 00 04 A1 12 09 15
			39 00 00 40 00 00 04 A2 0F 07 11
			39 00 00 40 00 00 04 FF 5A A5 5C
			39 00 00 40 00 00 04 C8 0C 0A 05

			39 00 00 40 00 00 04 FF 5A A5 2D //switch 90hz
			39 00 00 40 00 00 03 98 00 00
			39 00 00 40 00 00 02 CD 01
			39 00 00 40 00 00 03 83 00 00
			39 00 00 40 00 00 02 F2 00 // 120Hz Frame Skip mode Exit
			39 00 00 40 00 00 04 FF 5A A5 24
			39 00 00 40 00 00 02 86 00
			39 00 00 40 00 00 02 8A 00
			39 00 00 40 00 00 04 FF 5A A5 00
			39 00 00 40 00 00 02 53 20
			39 00 00 40 00 00 02 60 02
			39 00 00 40 00 00 04 FF 5A A5 53
			39 00 00 40 00 00 02 86 3D //Exit 165 DC code
			39 00 00 00 00 00 04 FF 5A A5 00

			39 00 00 40 00 00 04 FF 5A A5 07 //10bit 3.75
			39 00 00 40 00 00 02 8A 01
			39 00 00 40 00 00 03 8B 21 E0
			39 00 00 40 00 00 64 81 00 00 00 00 00 12 00 00 ab 30 80 0a dc 04 f0 00 14 02 78 02 78 02 00 02 57 00 20 01 f8 00 08 00 0d 05 7a 04 4f 18 00 10 e0 07 10 20 00 06 0f 0f 33 0e 1c 2a 38 46 54 62 69 70 77 79 7b 7d 7e 02 02 22 00 2a 40 2a be 3a fc 3a fa 3a f8 3b 38 3b 78 3b b6 4b b6 4b f4 4b f4 6c 34 84 74 00 00 00 00 00 00
			39 00 00 00 00 00 04 FF 5A A5 00

			05 00 00 00 78 00 01 11 //Delay 120ms
			39 00 00 40 00 00 04 FF 5A A5 49 //OD Code
			39 00 00 40 00 00 11 81 D2 00 BC 02 C0 03 24 05 08 07 D4 0C D2 14 74 1B
			39 00 00 40 00 00 13 82 D2 00 BC 02 C0 03 24 05 08 07 D4 0C D2 14 74 1B 00 00
			39 00 00 40 00 00 02 83 0B
			39 00 00 40 00 00 04 FF 5A A5 53
			39 00 00 40 00 00 02 86 3D //Exit 165 DC code
			39 00 00 40 00 00 04 FF 5A A5 51
			39 00 00 40 00 00 07 A1 AC AC AC AC 22 22
			39 00 00 40 00 00 07 A2 AC A5 A5 A5 22 22
			39 00 00 40 00 00 07 A3 A5 98 98 98 22 22
			39 00 00 40 00 00 04 FF 5A A5 52
			39 00 00 40 00 00 07 81 E2 94 77 77 00 00
			39 00 00 40 00 00 07 82 77 76 76 76 00 00
			39 00 00 40 00 00 07 83 76 6E 6E 6E 00 00
			39 00 00 00 00 00 04 FF 5A A5 00
			05 00 00 00 14 00 01 29];	/* display on */
		qcom,mdss-dsi-off-command = [
			39 00 00 40 00 00 04 FF 5A A5 00
			05 00 00 00 14 00 01 28		/* display_off */
			05 00 00 00 BE 00 01 10];	/* enter sleep mode */

		qcom,mdss-dsi-on-command-state = "dsi_lp_mode";
		qcom,mdss-dsi-off-command-state = "dsi_lp_mode";
		qcom,mdss-dsi-timing-switch-command-state = "dsi_lp_mode";
		qcom,compression-mode = "dsc";
		/* Why QCOM doesn't use this, even it used 2 encoder
		 * as for that dsi_sw43404_amoled_cmd, for ex */
		/* qcom,mdss-dsc-encoders = <2>; */
		qcom,mdss-dsc-version = <0x12>;
		qcom,mdss-dsc-slice-height = <20>;
		qcom,mdss-dsc-slice-width = <632>;
		qcom,mdss-dsc-slice-per-pkt = <2>;
		qcom,mdss-dsc-bit-per-component = <10>;
		qcom,mdss-dsc-bit-per-pixel = <8>;
		qcom,mdss-dsc-block-prediction-enable;
		qcom,mdss-dsi-pcd-check-enable-command = [
			39 00 00 00 00 00 04 FF 5A A5 03
			];
		qcom,mdss-dsi-pcd-check-enable-command-state = "dsi_hs_mode";
		qcom,mdss-dsi-pcd-check-disable-command = [
			39 00 00 00 00 00 04 FF 5A A5 00
			];
		qcom,mdss-dsi-pcd-check-disable-command-state = "dsi_hs_mode";
		qcom,mdss-dsi-lp1-command = [
			39 00 00 40 00 00 04 FF 5A A5 2D
			39 00 00 40 00 00 03 98 00 00
			39 00 00 40 00 00 02 CD 01
			39 00 00 40 00 00 03 83 00 00
			39 00 00 40 00 00 02 F2 00 // 120Hz Frame Skip mode Exit
			39 00 00 40 00 00 04 FF 5A A5 24
			39 00 00 40 00 00 02 86 00
			39 00 00 40 00 00 02 8A 00
			39 00 00 40 00 00 04 FF 5A A5 00
			39 00 00 40 00 00 02 53 20
			39 00 00 40 00 00 02 60 02
			39 00 00 40 00 00 04 FF 5A A5 53
			39 00 00 40 00 00 02 86 3D //Exit 165 DC code
			39 00 00 00 00 00 04 FF 5A A5 00
		];
		qcom,mdss-dsi-lp1-command-state =
			"dsi_lp_mode";
		qcom,mdss-dsi-lp2-command = [
			39 00 00 40 00 00 04 FF 5A A5 4F
			39 00 00 40 00 00 02 81 04
			39 00 00 40 00 00 04 FF 5A A5 08
			39 00 00 40 00 00 02 98 02
			39 00 00 40 00 00 04 FF 5A A5 4F
			39 00 00 40 00 00 02 88 78
			39 00 00 40 00 00 04 FF 5A A5 24
			39 00 00 40 00 00 02 86 00
			39 00 00 40 00 00 02 8A 00
			39 00 00 40 00 00 04 FF 5A A5 00
			39 00 00 40 00 00 02 53 20
			39 00 00 40 00 00 02 60 00
			39 00 00 40 00 00 04 FF 5A A5 2D
			39 00 00 40 00 00 03 98 00 00
			39 00 00 40 00 00 02 CD 01
			39 00 00 40 00 00 03 83 77 00
			39 00 00 40 00 00 02 F2 00
			39 00 00 40 00 00 04 FF 5A A5 53
			39 00 00 40 00 00 02 86 3D //Exit 165 DC code
			39 00 00 40 00 00 04 FF 5A A5 08
			39 00 00 40 00 00 02 98 A6
			39 00 00 40 00 00 04 FF 5A A5 00
			39 00 00 40 00 00 02 00 00
			39 00 00 40 00 00 04 FF 5A A5 4F
			39 00 00 40 00 00 02 8B 78
			39 00 00 00 00 00 04 FF 5A A5 00
		];
		qcom,mdss-dsi-lp2-command-state =
			"dsi_lp_mode";
		qcom,mdss-dsi-nolp-command = [
			39 00 00 40 00 00 04 FF 5A A5 2D
			39 00 00 40 00 00 03 98 00 00
			39 00 00 40 00 00 02 CD 01
			39 00 00 40 00 00 03 83 00 00
			39 00 00 40 00 00 02 F2 00 // 120Hz Frame Skip mode Exit
			39 00 00 40 00 00 04 FF 5A A5 24
			39 00 00 40 00 00 02 86 00
			39 00 00 40 00 00 02 8A 00
			39 00 00 40 00 00 04 FF 5A A5 00
			39 00 00 40 00 00 02 53 20
			39 00 00 40 00 00 02 60 02
			39 00 00 40 00 00 04 FF 5A A5 53
			39 00 00 40 00 00 02 86 3D //Exit 165 DC code
			39 00 00 00 00 00 04 FF 5A A5 00
		];
		qcom,mdss-dsi-nolp-command-state =
			"dsi_lp_mode";
	};

	timing@3{
		qcom,mdss-dsi-cmd-mode;
		qcom,mdss-dsi-panel-framerate = <60>;
		qcom,mdss-dsi-panel-width = <1264>;
		qcom,mdss-dsi-panel-height = <2780>;
		qcom,mdss-dsi-h-front-porch = <31>;
		qcom,mdss-dsi-h-back-porch = <32>;
		qcom,mdss-dsi-h-pulse-width = <16>;
		qcom,mdss-dsi-h-sync-skew = <0>;
		qcom,mdss-dsi-h-sync-pulse = <0>;
		qcom,mdss-dsi-v-back-porch = <42>;
		qcom,mdss-dsi-v-front-porch = <58>;
		qcom,mdss-dsi-v-pulse-width = <2>;
		qcom,mdss-dsi-h-left-border = <0>;
		qcom,mdss-dsi-h-right-border = <0>;
		qcom,mdss-dsi-v-top-border = <0>;
		qcom,mdss-dsi-v-bottom-border = <0>;
	        qcom,mdss-dsi-panel-jitter = <0x20 0xa>;
	        qcom,mdss-dsi-timing-switch-command = [
	        	39 00 00 40 00 00 04 FF 5A A5 4F
			39 00 00 40 00 00 02 81 04
			39 00 00 40 00 00 04 FF 5A A5 08
			39 00 00 40 00 00 02 98 02
			39 00 00 40 00 00 04 FF 5A A5 4F
			39 00 00 40 00 00 02 88 78
			39 00 00 40 00 00 04 FF 5A A5 24
			39 00 00 40 00 00 02 86 00
			39 00 00 40 00 00 02 8A 00
			39 00 00 40 00 00 04 FF 5A A5 00
			39 00 00 40 00 00 02 53 20
			39 00 00 40 00 00 02 60 00
			39 00 00 40 00 00 04 FF 5A A5 2D
			39 00 00 40 00 00 03 98 01 00
			39 00 00 40 00 00 02 CD 01
			39 00 00 40 00 00 03 83 01 00
			39 00 00 40 00 00 02 F2 01
			39 00 00 40 00 00 04 FF 5A A5 53
			39 00 00 40 00 00 02 86 3D //Exit 165 DC code
			39 00 00 40 00 00 04 FF 5A A5 08
			39 00 00 40 00 00 02 98 A6
			39 00 00 40 00 00 04 FF 5A A5 00
			39 00 00 40 00 00 02 00 00
			39 00 00 40 00 00 04 FF 5A A5 4F
			39 00 00 40 00 00 02 8B 78
			39 00 00 00 11 00 04 FF 5A A5 00
	        ];
		qcom,mdss-dsi-on-command = [
			39 00 00 40 00 00 04 FF 5A A5 00 //ODC dbv420 and 10nit
			39 00 00 40 00 00 02 4D 01
			39 00 00 40 00 00 04 FF 5A A5 4F
			39 00 00 40 00 00 02 A1 00
			39 00 00 40 00 00 02 A2 01
			39 00 00 40 00 00 02 A3 A4
			39 00 00 40 00 00 02 A4 0A
			39 00 00 40 00 00 02 A5 48
			39 00 00 40 00 00 04 FF 5A A5 71
			39 00 00 40 00 00 07 85 00 80 0A F3 00 00
			39 00 00 40 00 00 07 86 00 66 09 8F 04 00
			39 00 00 40 00 00 07 87 00 60 09 36 14 00
			39 00 00 40 00 00 07 88 00 53 08 84 24 00
			39 00 00 40 00 00 07 89 00 46 07 D2 04 00
			39 00 00 40 00 00 07 8A 00 80 18 B3 00 00
			39 00 00 40 00 00 07 8B 00 66 17 C2 04 00
			39 00 00 40 00 00 07 8C 00 60 17 86 14 00
			39 00 00 40 00 00 07 8D 00 53 17 0E 24 00
			39 00 00 40 00 00 07 8E 00 46 16 95 04 00
			39 00 00 40 00 00 07 8F 00 80 26 00 00 00
			39 00 00 40 00 00 07 90 00 66 25 99 04 00
			39 00 00 40 00 00 07 91 00 60 25 80 14 00
			39 00 00 40 00 00 07 92 00 53 25 4C 24 00
			39 00 00 40 00 00 07 93 00 46 25 19 04 00
			39 00 00 40 00 00 07 94 00 80 04 00 00 00
			39 00 00 40 00 00 07 95 00 66 04 00 04 00
			39 00 00 40 00 00 07 96 00 60 04 00 14 00
			39 00 00 40 00 00 07 97 00 53 04 00 24 00
			39 00 00 40 00 00 07 98 00 46 04 00 04 00
			39 00 00 40 00 00 07 99 0C 19 00 80 00 00
			39 00 00 40 00 00 07 9A 0A 7B 00 66 04 00
			39 00 00 40 00 00 07 9B 0A 13 00 60 14 00
			39 00 00 40 00 00 07 9C 09 43 00 53 24 00
			39 00 00 40 00 00 07 9D 08 74 00 46 04 00
			39 00 00 40 00 00 07 9E 04 00 0A 00 00 00
			39 00 00 40 00 00 07 A3 04 00 16 80 00 00
			39 00 00 40 00 00 07 A4 04 00 16 00 04 00
			39 00 00 40 00 00 07 B2 19 EC 00 80 00 00
			39 00 00 40 00 00 07 B3 18 BD 00 66 04 00
			39 00 00 40 00 00 07 B4 18 71 00 60 14 00
			39 00 00 40 00 00 07 B5 17 DA 00 53 24 00
			39 00 00 40 00 00 07 B6 17 42 00 46 04 00
			39 00 00 40 00 00 07 CB 25 B9 00 80 00 00
			39 00 00 40 00 00 07 CC 25 61 00 66 04 00
			39 00 00 40 00 00 07 CD 25 4B 00 60 14 00
			39 00 00 40 00 00 07 CE 25 1F 00 53 24 00
			39 00 00 40 00 00 07 CF 24 F2 00 46 04 00
			39 00 00 40 00 00 07 E4 04 00 00 80 00 00
			39 00 00 40 00 00 07 E5 04 00 00 66 04 00
			39 00 00 40 00 00 07 E6 04 00 00 60 14 00
			39 00 00 40 00 00 07 E7 04 00 00 53 24 00
			39 00 00 40 00 00 07 E8 04 00 00 46 04 00
			39 00 00 40 00 00 04 FF 5A A5 49
			39 00 00 40 00 00 02 E0 01
			39 00 00 40 00 00 04 FF 5A A5 5B
			39 00 00 40 00 00 04 C8 03 06 01
			39 00 00 40 00 00 04 C9 04 07 01
			39 00 00 40 00 00 04 CA 00 00 00
			39 00 00 40 00 00 04 CB 06 07 03
			39 00 00 40 00 00 04 CC 01 00 00
			39 00 00 40 00 00 04 CD 00 00 00
			39 00 00 40 00 00 04 CE 09 09 07
			39 00 00 40 00 00 04 CF 03 02 02
			39 00 00 40 00 00 04 D0 02 01 01
			39 00 00 40 00 00 04 D1 00 00 00
			39 00 00 40 00 00 04 D2 16 12 13
			39 00 00 40 00 00 04 D3 09 07 07
			39 00 00 40 00 00 04 D4 07 06 06
			39 00 00 40 00 00 04 D5 03 03 02
			39 00 00 40 00 00 04 D6 00 00 00
			39 00 00 40 00 00 04 D7 19 15 16
			39 00 00 40 00 00 04 D8 0B 08 08
			39 00 00 40 00 00 04 D9 09 07 07
			39 00 00 40 00 00 04 DA 04 04 03
			39 00 00 40 00 00 04 DB 00 00 00
			39 00 00 40 00 00 04 DC 00 00 00
			39 00 00 40 00 00 04 DD 24 21 1F
			39 00 00 40 00 00 04 DE 13 10 0D
			39 00 00 40 00 00 04 DF 10 0E 0C
			39 00 00 40 00 00 04 E0 09 09 06
			39 00 00 40 00 00 04 E1 01 02 01
			39 00 00 40 00 00 04 E2 00 00 00
			39 00 00 40 00 00 04 E3 00 00 00
			39 00 00 40 00 00 04 E4 2E 2B 26
			39 00 00 40 00 00 04 E5 1B 17 12
			39 00 00 40 00 00 04 E6 18 15 10
			39 00 00 40 00 00 04 E7 0E 0F 09
			39 00 00 40 00 00 04 E8 04 04 01
			39 00 00 40 00 00 04 E9 00 00 00
			39 00 00 40 00 00 04 EA 00 00 00
			39 00 00 40 00 00 04 EB 00 00 00
			39 00 00 40 00 00 04 FF 5A A5 5C
			39 00 00 40 00 00 04 80 02 02 01
			39 00 00 40 00 00 04 81 02 02 01
			39 00 00 40 00 00 04 82 00 00 00
			39 00 00 40 00 00 04 83 04 04 02
			39 00 00 40 00 00 04 84 00 00 00
			39 00 00 40 00 00 04 85 00 00 00
			39 00 00 40 00 00 04 86 08 07 07
			39 00 00 40 00 00 04 87 02 02 01
			39 00 00 40 00 00 04 88 01 01 01
			39 00 00 40 00 00 04 89 00 00 00
			39 00 00 40 00 00 04 8A 13 11 10
			39 00 00 40 00 00 04 8B 07 07 05
			39 00 00 40 00 00 04 8C 06 06 04
			39 00 00 40 00 00 04 8D 01 02 01
			39 00 00 40 00 00 04 8E 00 00 00
			39 00 00 40 00 00 04 8F 16 14 12
			39 00 00 40 00 00 04 90 09 08 06
			39 00 00 40 00 00 04 91 07 07 04
			39 00 00 40 00 00 04 92 02 02 01
			39 00 00 40 00 00 04 93 00 00 00
			39 00 00 40 00 00 04 94 00 00 00
			39 00 00 40 00 00 04 95 30 2C 18
			39 00 00 40 00 00 04 96 0E 0D 08
			39 00 00 40 00 00 04 97 0B 0B 06
			39 00 00 40 00 00 04 98 05 05 01
			39 00 00 40 00 00 04 99 01 01 00
			39 00 00 40 00 00 04 9A 00 00 00
			39 00 00 40 00 00 04 9B 00 00 00
			39 00 00 40 00 00 04 9C 45 33 1D
			39 00 00 40 00 00 04 9D 12 11 09
			39 00 00 40 00 00 04 9E 0F 0F 07
			39 00 00 40 00 00 04 9F 07 08 01
			39 00 00 40 00 00 04 A0 01 01 00
			39 00 00 40 00 00 04 A1 00 00 00
			39 00 00 40 00 00 04 A2 00 00 00
			39 00 00 40 00 00 04 A3 00 00 00
			39 00 00 40 00 00 04 CE 10 18 10
			39 00 00 40 00 00 04 CF 10 18 10

			39 00 00 40 00 00 04 FF 5A A5 06 //esd check
			39 00 00 40 00 00 02 C6 01
			39 00 00 40 00 00 04 FF 5A A5 08
			39 00 00 40 00 00 02 D2 05
			39 00 00 40 00 00 09 ED FF FF FF FF FF FF 45 FF
			39 00 00 40 00 00 09 EE FF FD FF FD F9 FA BE 76
			39 00 00 40 00 00 04 FF 5A A5 00

			39 00 00 40 00 00 04 FF 5A A5 03 //Power on code
			39 00 00 40 00 00 04 90 01 80 23
			39 00 00 40 00 00 04 FF 5A A5 08
			39 00 00 40 00 00 02 E0 22
			39 00 00 40 00 00 04 FF 5A A5 09
			39 00 00 40 00 00 02 A1 03
			39 00 00 40 00 00 04 FF 5A A5 1E
			39 00 00 40 00 00 02 C1 70
			39 00 00 40 00 00 04 FF 5A A5 05
			39 00 00 40 00 00 02 83 01
			39 00 00 40 00 00 02 84 01
			39 00 00 40 00 00 04 FF 5A A5 1C
			39 00 00 40 00 00 15 E1 10 80 9A 65 59 54 69 95 56 6A 55 99 9A 55 55 25 58 55 66 A2
			39 00 00 40 00 00 04 FF 5A A5 20
			39 00 00 40 00 00 02 D5 10
			39 00 00 40 00 00 02 BC 06
			39 00 00 40 00 00 04 FF 5A A5 02
			39 00 00 40 00 00 03 AB AF 86

			39 00 00 40 00 00 04 FF 5A A5 4B //pcd check code
			39 00 00 40 00 00 02 EE 10
			39 00 00 40 00 00 04 FF 5A A5 03
			39 00 00 40 00 00 02 BD D1
			39 00 00 40 00 00 02 BB 29
			39 00 00 40 00 00 04 FF 5A A5 1C
			39 00 00 40 00 00 02 D3 43

			39 00 00 40 00 00 04 FF 5A A5 08
			39 00 00 40 00 00 02 C8 62
			39 00 00 40 00 00 04 FF 5A A5 21
			39 00 00 40 00 00 02 A4 38
			39 00 00 40 00 00 04 FF 5A A5 23
			39 00 00 40 00 00 02 85 15
			39 00 00 40 00 00 04 FF 5A A5 01
			39 00 00 40 00 00 02 FB 08
			39 00 00 40 00 00 04 FF 5A A5 00
			39 00 00 40 00 00 02 5E 01
			39 00 00 40 00 00 02 60 00
			39 00 00 40 00 00 02 61 08
			39 00 00 40 00 00 01 35
			39 00 00 40 00 00 02 53 20
			39 00 00 40 00 00 03 51 00 00

			39 00 00 40 00 00 04 FF 5A A5 24 //DBV Diming
			39 00 00 40 00 00 02 85 31
			39 00 00 40 00 00 02 89 31
			39 00 00 40 00 00 04 FF 5A A5 2D
			39 00 00 40 00 00 02 CE 55
			39 00 00 40 00 00 04 FF 5A A5 5A //OD LUT
			39 00 00 40 00 00 04 80 00 01 00
			39 00 00 40 00 00 04 81 00 02 01
			39 00 00 40 00 00 04 82 00 00 00
			39 00 00 40 00 00 04 83 03 0B 04
			39 00 00 40 00 00 04 84 02 05 00
			39 00 00 40 00 00 04 85 02 05 00
			39 00 00 40 00 00 04 86 11 24 11
			39 00 00 40 00 00 04 87 0B 0A 03
			39 00 00 40 00 00 04 88 09 08 03
			39 00 00 40 00 00 04 89 05 04 03
			39 00 00 40 00 00 04 8A 1A 1E 21
			39 00 00 40 00 00 04 8B 11 0D 0F
			39 00 00 40 00 00 04 8C 11 0B 0D
			39 00 00 40 00 00 04 8D 0B 07 0B
			39 00 00 40 00 00 04 8E 05 04 08
			39 00 00 40 00 00 04 8F 26 26 26
			39 00 00 40 00 00 04 90 15 0E 13
			39 00 00 40 00 00 04 91 14 0C 12
			39 00 00 40 00 00 04 92 0F 08 0F
			39 00 00 40 00 00 04 93 08 05 0B
			39 00 00 40 00 00 04 94 00 00 00
			39 00 00 40 00 00 04 95 3E 32 32
			39 00 00 40 00 00 04 96 24 14 26
			39 00 00 40 00 00 04 97 21 12 21
			39 00 00 40 00 00 04 98 1D 10 20
			39 00 00 40 00 00 04 99 12 0B 16
			39 00 00 40 00 00 04 9A 09 05 0B
			39 00 00 40 00 00 04 9B 06 03 08
			39 00 00 40 00 00 04 9C 32 35 2D
			39 00 00 40 00 00 04 9D 36 19 2C
			39 00 00 40 00 00 04 9E 32 18 30
			39 00 00 40 00 00 04 9F 2A 16 29
			39 00 00 40 00 00 04 A0 1D 12 21
			39 00 00 40 00 00 04 A1 12 09 15
			39 00 00 40 00 00 04 A2 0F 07 11
			39 00 00 40 00 00 04 FF 5A A5 5C
			39 00 00 40 00 00 04 C8 0C 0A 05

			39 00 00 40 00 00 04 FF 5A A5 24 //switch 60hz
			39 00 00 40 00 00 02 86 00
			39 00 00 40 00 00 02 8A 00
			39 00 00 40 00 00 04 FF 5A A5 00
			39 00 00 40 00 00 02 53 20
			39 00 00 40 00 00 02 60 00
			39 00 00 40 00 00 04 FF 5A A5 2D
			39 00 00 40 00 00 03 98 01 00
			39 00 00 40 00 00 02 CD 01
			39 00 00 40 00 00 03 83 01 00
			39 00 00 40 00 00 02 F2 01

			39 00 00 40 00 00 04 FF 5A A5 07 //10bit 3.75
			39 00 00 40 00 00 02 8A 01
			39 00 00 40 00 00 03 8B 21 E0
			39 00 00 40 00 00 64 81 00 00 00 00 00 12 00 00 ab 30 80 0a dc 04 f0 00 14 02 78 02 78 02 00 02 57 00 20 01 f8 00 08 00 0d 05 7a 04 4f 18 00 10 e0 07 10 20 00 06 0f 0f 33 0e 1c 2a 38 46 54 62 69 70 77 79 7b 7d 7e 02 02 22 00 2a 40 2a be 3a fc 3a fa 3a f8 3b 38 3b 78 3b b6 4b b6 4b f4 4b f4 6c 34 84 74 00 00 00 00 00 00
			39 00 00 00 00 00 04 FF 5A A5 00

			05 00 00 00 78 00 01 11 //Delay 120ms
			39 00 00 40 00 00 04 FF 5A A5 49 //OD Code
			39 00 00 40 00 00 11 81 D2 00 BC 02 C0 03 24 05 08 07 D4 0C D2 14 74 1B
			39 00 00 40 00 00 13 82 D2 00 BC 02 C0 03 24 05 08 07 D4 0C D2 14 74 1B 00 00
			39 00 00 40 00 00 02 83 0B
			39 00 00 40 00 00 04 FF 5A A5 53
			39 00 00 40 00 00 02 86 3D //Exit 165 DC code
			39 00 00 40 00 00 04 FF 5A A5 51
			39 00 00 40 00 00 07 A1 AC AC AC AC 22 22
			39 00 00 40 00 00 07 A2 AC A5 A5 A5 22 22
			39 00 00 40 00 00 07 A3 A5 98 98 98 22 22
			39 00 00 40 00 00 04 FF 5A A5 52
			39 00 00 40 00 00 07 81 E2 94 77 77 00 00
			39 00 00 40 00 00 07 82 77 76 76 76 00 00
			39 00 00 40 00 00 07 83 76 6E 6E 6E 00 00
			39 00 00 00 00 00 04 FF 5A A5 00
			05 00 00 00 14 00 01 29];	/* display on */
		qcom,mdss-dsi-off-command = [
			39 00 00 40 00 00 04 FF 5A A5 00
			05 00 00 00 14 00 01 28		/* display_off */
			05 00 00 00 BE 00 01 10];	/* enter sleep mode */

		qcom,mdss-dsi-on-command-state = "dsi_lp_mode";
		qcom,mdss-dsi-off-command-state = "dsi_lp_mode";
		qcom,mdss-dsi-timing-switch-command-state = "dsi_lp_mode";
		qcom,compression-mode = "dsc";
		/* Why QCOM doesn't use this, even it used 2 encoder
		 * as for that dsi_sw43404_amoled_cmd, for ex */
		/* qcom,mdss-dsc-encoders = <2>; */
		qcom,mdss-dsc-version = <0x12>;
		qcom,mdss-dsc-slice-height = <20>;
		qcom,mdss-dsc-slice-width = <632>;
		qcom,mdss-dsc-slice-per-pkt = <2>;
		qcom,mdss-dsc-bit-per-component = <10>;
		qcom,mdss-dsc-bit-per-pixel = <8>;
		qcom,mdss-dsc-block-prediction-enable;
		qcom,mdss-dsi-pcd-check-enable-command = [
			39 00 00 00 00 00 04 FF 5A A5 03
			];
		qcom,mdss-dsi-pcd-check-enable-command-state = "dsi_hs_mode";
		qcom,mdss-dsi-pcd-check-disable-command = [
			39 00 00 00 00 00 04 FF 5A A5 00
			];
		qcom,mdss-dsi-pcd-check-disable-command-state = "dsi_hs_mode";
		qcom,mdss-dsi-lp1-command = [
			39 00 00 40 00 00 04 FF 5A A5 4F
			39 00 00 40 00 00 02 81 04
			39 00 00 40 00 00 04 FF 5A A5 08
			39 00 00 40 00 00 02 98 02
			39 00 00 40 00 00 04 FF 5A A5 4F
			39 00 00 40 00 00 02 88 78
			39 00 00 40 00 00 04 FF 5A A5 24
			39 00 00 40 00 00 02 86 00
			39 00 00 40 00 00 02 8A 00
			39 00 00 40 00 00 04 FF 5A A5 00
			39 00 00 40 00 00 02 53 20
			39 00 00 40 00 00 02 60 00
			39 00 00 40 00 00 04 FF 5A A5 2D
			39 00 00 40 00 00 03 98 01 00
			39 00 00 40 00 00 02 CD 01
			39 00 00 40 00 00 03 83 01 00
			39 00 00 40 00 00 02 F2 01
			39 00 00 40 00 00 04 FF 5A A5 53
			39 00 00 40 00 00 02 86 3D //Exit 165 DC code
			39 00 00 40 00 00 04 FF 5A A5 08
			39 00 00 40 00 00 02 98 A6
			39 00 00 40 00 00 04 FF 5A A5 00
			39 00 00 40 00 00 02 00 00
			39 00 00 40 00 00 04 FF 5A A5 4F
			39 00 00 40 00 00 02 8B 78
			39 00 00 00 00 00 04 FF 5A A5 00
		];
		qcom,mdss-dsi-lp1-command-state =
			"dsi_lp_mode";
		qcom,mdss-dsi-lp2-command = [
			39 00 00 40 00 00 04 FF 5A A5 4F
			39 00 00 40 00 00 02 81 04
			39 00 00 40 00 00 04 FF 5A A5 08
			39 00 00 40 00 00 02 98 02
			39 00 00 40 00 00 04 FF 5A A5 4F
			39 00 00 40 00 00 02 88 78
			39 00 00 40 00 00 04 FF 5A A5 24
			39 00 00 40 00 00 02 86 00
			39 00 00 40 00 00 02 8A 00
			39 00 00 40 00 00 04 FF 5A A5 00
			39 00 00 40 00 00 02 53 20
			39 00 00 40 00 00 02 60 00
			39 00 00 40 00 00 04 FF 5A A5 2D
			39 00 00 40 00 00 03 98 00 00
			39 00 00 40 00 00 02 CD 01
			39 00 00 40 00 00 03 83 77 00
			39 00 00 40 00 00 02 F2 00
			39 00 00 40 00 00 04 FF 5A A5 53
			39 00 00 40 00 00 02 86 3D //Exit 165 DC code
			39 00 00 40 00 00 04 FF 5A A5 08
			39 00 00 40 00 00 02 98 A6
			39 00 00 40 00 00 04 FF 5A A5 00
			39 00 00 40 00 00 02 00 00
			39 00 00 40 00 00 04 FF 5A A5 4F
			39 00 00 40 00 00 02 8B 78
			39 00 00 00 00 00 04 FF 5A A5 00
		];
		qcom,mdss-dsi-lp2-command-state =
			"dsi_lp_mode";
		qcom,mdss-dsi-nolp-command = [
			39 00 00 40 00 00 04 FF 5A A5 4F
			39 00 00 40 00 00 02 81 04
			39 00 00 40 00 00 04 FF 5A A5 08
			39 00 00 40 00 00 02 98 02
			39 00 00 40 00 00 04 FF 5A A5 4F
			39 00 00 40 00 00 02 88 78
			39 00 00 40 00 00 04 FF 5A A5 24
			39 00 00 40 00 00 02 86 00
			39 00 00 40 00 00 02 8A 00
			39 00 00 40 00 00 04 FF 5A A5 00
			39 00 00 40 00 00 02 53 20
			39 00 00 40 00 00 02 60 00
			39 00 00 40 00 00 04 FF 5A A5 2D
			39 00 00 40 00 00 03 98 01 00
			39 00 00 40 00 00 02 CD 01
			39 00 00 40 00 00 03 83 01 00
			39 00 00 40 00 00 02 F2 01
			39 00 00 40 00 00 04 FF 5A A5 53
			39 00 00 40 00 00 02 86 3D //Exit 165 DC code
			39 00 00 40 00 00 04 FF 5A A5 08
			39 00 00 40 00 00 02 98 A6
			39 00 00 40 00 00 04 FF 5A A5 00
			39 00 00 40 00 00 02 00 00
			39 00 00 40 00 00 04 FF 5A A5 4F
			39 00 00 40 00 00 02 8B 78
			39 00 00 00 00 00 04 FF 5A A5 00
		];
		qcom,mdss-dsi-nolp-command-state =
			"dsi_lp_mode";
	};

	timing@4{
		qcom,mdss-dsi-cmd-mode;
		qcom,mdss-dsi-panel-framerate = <30>;
		qcom,mdss-dsi-panel-width = <1264>;
		qcom,mdss-dsi-panel-height = <2780>;
		qcom,mdss-dsi-h-front-porch = <31>;
		qcom,mdss-dsi-h-back-porch = <32>;
		qcom,mdss-dsi-h-pulse-width = <16>;
		qcom,mdss-dsi-h-sync-skew = <0>;
		qcom,mdss-dsi-h-sync-pulse = <0>;
		qcom,mdss-dsi-v-back-porch = <42>;
		qcom,mdss-dsi-v-front-porch = <58>;
		qcom,mdss-dsi-v-pulse-width = <2>;
		qcom,mdss-dsi-h-left-border = <0>;
		qcom,mdss-dsi-h-right-border = <0>;
		qcom,mdss-dsi-v-top-border = <0>;
		qcom,mdss-dsi-v-bottom-border = <0>;
	        qcom,mdss-dsi-panel-jitter = <0x20 0xa>;
	        qcom,mdss-mdp-transfer-time-us = <7933>;
	        qcom,mdss-dsi-timing-switch-command = [
			39 00 00 40 00 00 04 FF 5A A5 4F
			39 00 00 40 00 00 02 81 04
			39 00 00 40 00 00 04 FF 5A A5 08
			39 00 00 40 00 00 02 98 02
			39 00 00 40 00 00 04 FF 5A A5 4F
			39 00 00 40 00 00 02 88 78
			39 00 00 40 00 00 04 FF 5A A5 24
			39 00 00 40 00 00 02 86 80
			39 00 00 40 00 00 02 8A 80
			39 00 00 40 00 00 04 FF 5A A5 00
			39 00 00 40 00 00 02 53 28
			39 00 00 40 00 00 02 60 00
			39 00 00 40 00 00 04 FF 5A A5 2D
			39 00 00 40 00 00 03 98 03 00
			39 00 00 40 00 00 02 CD 21
			39 00 00 40 00 00 03 83 03 00
			39 00 00 40 00 00 02 F2 03
			39 00 00 40 00 00 04 FF 5A A5 53
			39 00 00 40 00 00 02 86 3D //Exit 165 DC code
			39 00 00 40 00 00 04 FF 5A A5 08
			39 00 00 40 00 00 02 98 A6
			39 00 00 40 00 00 04 FF 5A A5 00
			39 00 00 40 00 00 02 00 00
			39 00 00 40 00 00 04 FF 5A A5 4F
			39 00 00 40 00 00 02 8B 78
			39 00 00 00 00 00 04 FF 5A A5 00
	        ];
		qcom,mdss-dsi-on-command = [
			39 00 00 40 00 00 04 FF 5A A5 00 //ODC dbv420 and 10nit
			39 00 00 40 00 00 02 4D 01
			39 00 00 40 00 00 04 FF 5A A5 4F
			39 00 00 40 00 00 02 A1 00
			39 00 00 40 00 00 02 A2 01
			39 00 00 40 00 00 02 A3 A4
			39 00 00 40 00 00 02 A4 0A
			39 00 00 40 00 00 02 A5 48
			39 00 00 40 00 00 04 FF 5A A5 71
			39 00 00 40 00 00 07 85 00 80 0A F3 00 00
			39 00 00 40 00 00 07 86 00 66 09 8F 04 00
			39 00 00 40 00 00 07 87 00 60 09 36 14 00
			39 00 00 40 00 00 07 88 00 53 08 84 24 00
			39 00 00 40 00 00 07 89 00 46 07 D2 04 00
			39 00 00 40 00 00 07 8A 00 80 18 B3 00 00
			39 00 00 40 00 00 07 8B 00 66 17 C2 04 00
			39 00 00 40 00 00 07 8C 00 60 17 86 14 00
			39 00 00 40 00 00 07 8D 00 53 17 0E 24 00
			39 00 00 40 00 00 07 8E 00 46 16 95 04 00
			39 00 00 40 00 00 07 8F 00 80 26 00 00 00
			39 00 00 40 00 00 07 90 00 66 25 99 04 00
			39 00 00 40 00 00 07 91 00 60 25 80 14 00
			39 00 00 40 00 00 07 92 00 53 25 4C 24 00
			39 00 00 40 00 00 07 93 00 46 25 19 04 00
			39 00 00 40 00 00 07 94 00 80 04 00 00 00
			39 00 00 40 00 00 07 95 00 66 04 00 04 00
			39 00 00 40 00 00 07 96 00 60 04 00 14 00
			39 00 00 40 00 00 07 97 00 53 04 00 24 00
			39 00 00 40 00 00 07 98 00 46 04 00 04 00
			39 00 00 40 00 00 07 99 0C 19 00 80 00 00
			39 00 00 40 00 00 07 9A 0A 7B 00 66 04 00
			39 00 00 40 00 00 07 9B 0A 13 00 60 14 00
			39 00 00 40 00 00 07 9C 09 43 00 53 24 00
			39 00 00 40 00 00 07 9D 08 74 00 46 04 00
			39 00 00 40 00 00 07 9E 04 00 0A 00 00 00
			39 00 00 40 00 00 07 A3 04 00 16 80 00 00
			39 00 00 40 00 00 07 A4 04 00 16 00 04 00
			39 00 00 40 00 00 07 B2 19 EC 00 80 00 00
			39 00 00 40 00 00 07 B3 18 BD 00 66 04 00
			39 00 00 40 00 00 07 B4 18 71 00 60 14 00
			39 00 00 40 00 00 07 B5 17 DA 00 53 24 00
			39 00 00 40 00 00 07 B6 17 42 00 46 04 00
			39 00 00 40 00 00 07 CB 25 B9 00 80 00 00
			39 00 00 40 00 00 07 CC 25 61 00 66 04 00
			39 00 00 40 00 00 07 CD 25 4B 00 60 14 00
			39 00 00 40 00 00 07 CE 25 1F 00 53 24 00
			39 00 00 40 00 00 07 CF 24 F2 00 46 04 00
			39 00 00 40 00 00 07 E4 04 00 00 80 00 00
			39 00 00 40 00 00 07 E5 04 00 00 66 04 00
			39 00 00 40 00 00 07 E6 04 00 00 60 14 00
			39 00 00 40 00 00 07 E7 04 00 00 53 24 00
			39 00 00 40 00 00 07 E8 04 00 00 46 04 00
			39 00 00 40 00 00 04 FF 5A A5 49
			39 00 00 40 00 00 02 E0 01
			39 00 00 40 00 00 04 FF 5A A5 5B
			39 00 00 40 00 00 04 C8 03 06 01
			39 00 00 40 00 00 04 C9 04 07 01
			39 00 00 40 00 00 04 CA 00 00 00
			39 00 00 40 00 00 04 CB 06 07 03
			39 00 00 40 00 00 04 CC 01 00 00
			39 00 00 40 00 00 04 CD 00 00 00
			39 00 00 40 00 00 04 CE 09 09 07
			39 00 00 40 00 00 04 CF 03 02 02
			39 00 00 40 00 00 04 D0 02 01 01
			39 00 00 40 00 00 04 D1 00 00 00
			39 00 00 40 00 00 04 D2 16 12 13
			39 00 00 40 00 00 04 D3 09 07 07
			39 00 00 40 00 00 04 D4 07 06 06
			39 00 00 40 00 00 04 D5 03 03 02
			39 00 00 40 00 00 04 D6 00 00 00
			39 00 00 40 00 00 04 D7 19 15 16
			39 00 00 40 00 00 04 D8 0B 08 08
			39 00 00 40 00 00 04 D9 09 07 07
			39 00 00 40 00 00 04 DA 04 04 03
			39 00 00 40 00 00 04 DB 00 00 00
			39 00 00 40 00 00 04 DC 00 00 00
			39 00 00 40 00 00 04 DD 24 21 1F
			39 00 00 40 00 00 04 DE 13 10 0D
			39 00 00 40 00 00 04 DF 10 0E 0C
			39 00 00 40 00 00 04 E0 09 09 06
			39 00 00 40 00 00 04 E1 01 02 01
			39 00 00 40 00 00 04 E2 00 00 00
			39 00 00 40 00 00 04 E3 00 00 00
			39 00 00 40 00 00 04 E4 2E 2B 26
			39 00 00 40 00 00 04 E5 1B 17 12
			39 00 00 40 00 00 04 E6 18 15 10
			39 00 00 40 00 00 04 E7 0E 0F 09
			39 00 00 40 00 00 04 E8 04 04 01
			39 00 00 40 00 00 04 E9 00 00 00
			39 00 00 40 00 00 04 EA 00 00 00
			39 00 00 40 00 00 04 EB 00 00 00
			39 00 00 40 00 00 04 FF 5A A5 5C
			39 00 00 40 00 00 04 80 02 02 01
			39 00 00 40 00 00 04 81 02 02 01
			39 00 00 40 00 00 04 82 00 00 00
			39 00 00 40 00 00 04 83 04 04 02
			39 00 00 40 00 00 04 84 00 00 00
			39 00 00 40 00 00 04 85 00 00 00
			39 00 00 40 00 00 04 86 08 07 07
			39 00 00 40 00 00 04 87 02 02 01
			39 00 00 40 00 00 04 88 01 01 01
			39 00 00 40 00 00 04 89 00 00 00
			39 00 00 40 00 00 04 8A 13 11 10
			39 00 00 40 00 00 04 8B 07 07 05
			39 00 00 40 00 00 04 8C 06 06 04
			39 00 00 40 00 00 04 8D 01 02 01
			39 00 00 40 00 00 04 8E 00 00 00
			39 00 00 40 00 00 04 8F 16 14 12
			39 00 00 40 00 00 04 90 09 08 06
			39 00 00 40 00 00 04 91 07 07 04
			39 00 00 40 00 00 04 92 02 02 01
			39 00 00 40 00 00 04 93 00 00 00
			39 00 00 40 00 00 04 94 00 00 00
			39 00 00 40 00 00 04 95 30 2C 18
			39 00 00 40 00 00 04 96 0E 0D 08
			39 00 00 40 00 00 04 97 0B 0B 06
			39 00 00 40 00 00 04 98 05 05 01
			39 00 00 40 00 00 04 99 01 01 00
			39 00 00 40 00 00 04 9A 00 00 00
			39 00 00 40 00 00 04 9B 00 00 00
			39 00 00 40 00 00 04 9C 45 33 1D
			39 00 00 40 00 00 04 9D 12 11 09
			39 00 00 40 00 00 04 9E 0F 0F 07
			39 00 00 40 00 00 04 9F 07 08 01
			39 00 00 40 00 00 04 A0 01 01 00
			39 00 00 40 00 00 04 A1 00 00 00
			39 00 00 40 00 00 04 A2 00 00 00
			39 00 00 40 00 00 04 A3 00 00 00
			39 00 00 40 00 00 04 CE 10 18 10
			39 00 00 40 00 00 04 CF 10 18 10

			39 00 00 40 00 00 04 FF 5A A5 06 //esd check
			39 00 00 40 00 00 02 C6 01
			39 00 00 40 00 00 04 FF 5A A5 08
			39 00 00 40 00 00 02 D2 05
			39 00 00 40 00 00 09 ED FF FF FF FF FF FF 45 FF
			39 00 00 40 00 00 09 EE FF FD FF FD F9 FA BE 76
			39 00 00 40 00 00 04 FF 5A A5 00

			39 00 00 40 00 00 04 FF 5A A5 03 //Power on code
			39 00 00 40 00 00 04 90 01 80 23
			39 00 00 40 00 00 04 FF 5A A5 08
			39 00 00 40 00 00 02 E0 22
			39 00 00 40 00 00 04 FF 5A A5 09
			39 00 00 40 00 00 02 A1 03
			39 00 00 40 00 00 04 FF 5A A5 1E
			39 00 00 40 00 00 02 C1 70
			39 00 00 40 00 00 04 FF 5A A5 05
			39 00 00 40 00 00 02 83 01
			39 00 00 40 00 00 02 84 01
			39 00 00 40 00 00 04 FF 5A A5 1C
			39 00 00 40 00 00 15 E1 10 80 9A 65 59 54 69 95 56 6A 55 99 9A 55 55 25 58 55 66 A2
			39 00 00 40 00 00 04 FF 5A A5 20
			39 00 00 40 00 00 02 D5 10
			39 00 00 40 00 00 02 BC 06
			39 00 00 40 00 00 04 FF 5A A5 02
			39 00 00 40 00 00 03 AB AF 86

			39 00 00 40 00 00 04 FF 5A A5 4B //pcd check code
			39 00 00 40 00 00 02 EE 10
			39 00 00 40 00 00 04 FF 5A A5 03
			39 00 00 40 00 00 02 BD D1
			39 00 00 40 00 00 02 BB 29
			39 00 00 40 00 00 04 FF 5A A5 1C
			39 00 00 40 00 00 02 D3 43

			39 00 00 40 00 00 04 FF 5A A5 08
			39 00 00 40 00 00 02 C8 62
			39 00 00 40 00 00 04 FF 5A A5 21
			39 00 00 40 00 00 02 A4 38
			39 00 00 40 00 00 04 FF 5A A5 23
			39 00 00 40 00 00 02 85 15
			39 00 00 40 00 00 04 FF 5A A5 01
			39 00 00 40 00 00 02 FB 08
			39 00 00 40 00 00 04 FF 5A A5 00
			39 00 00 40 00 00 02 5E 01
			39 00 00 40 00 00 02 60 00
			39 00 00 40 00 00 02 61 08
			39 00 00 40 00 00 01 35
			39 00 00 40 00 00 02 53 20
			39 00 00 40 00 00 03 51 00 00

			39 00 00 40 00 00 04 FF 5A A5 24 //DBV Diming
			39 00 00 40 00 00 02 85 31
			39 00 00 40 00 00 02 89 31
			39 00 00 40 00 00 04 FF 5A A5 2D
			39 00 00 40 00 00 02 CE 55
			39 00 00 40 00 00 04 FF 5A A5 5A //OD LUT
			39 00 00 40 00 00 04 80 00 01 00
			39 00 00 40 00 00 04 81 00 02 01
			39 00 00 40 00 00 04 82 00 00 00
			39 00 00 40 00 00 04 83 03 0B 04
			39 00 00 40 00 00 04 84 02 05 00
			39 00 00 40 00 00 04 85 02 05 00
			39 00 00 40 00 00 04 86 11 24 11
			39 00 00 40 00 00 04 87 0B 0A 03
			39 00 00 40 00 00 04 88 09 08 03
			39 00 00 40 00 00 04 89 05 04 03
			39 00 00 40 00 00 04 8A 1A 1E 21
			39 00 00 40 00 00 04 8B 11 0D 0F
			39 00 00 40 00 00 04 8C 11 0B 0D
			39 00 00 40 00 00 04 8D 0B 07 0B
			39 00 00 40 00 00 04 8E 05 04 08
			39 00 00 40 00 00 04 8F 26 26 26
			39 00 00 40 00 00 04 90 15 0E 13
			39 00 00 40 00 00 04 91 14 0C 12
			39 00 00 40 00 00 04 92 0F 08 0F
			39 00 00 40 00 00 04 93 08 05 0B
			39 00 00 40 00 00 04 94 00 00 00
			39 00 00 40 00 00 04 95 3E 32 32
			39 00 00 40 00 00 04 96 24 14 26
			39 00 00 40 00 00 04 97 21 12 21
			39 00 00 40 00 00 04 98 1D 10 20
			39 00 00 40 00 00 04 99 12 0B 16
			39 00 00 40 00 00 04 9A 09 05 0B
			39 00 00 40 00 00 04 9B 06 03 08
			39 00 00 40 00 00 04 9C 32 35 2D
			39 00 00 40 00 00 04 9D 36 19 2C
			39 00 00 40 00 00 04 9E 32 18 30
			39 00 00 40 00 00 04 9F 2A 16 29
			39 00 00 40 00 00 04 A0 1D 12 21
			39 00 00 40 00 00 04 A1 12 09 15
			39 00 00 40 00 00 04 A2 0F 07 11
			39 00 00 40 00 00 04 FF 5A A5 5C
			39 00 00 40 00 00 04 C8 0C 0A 05

			39 00 00 40 00 00 04 FF 5A A5 24 //switch 30hz
			39 00 00 40 00 00 02 86 80
			39 00 00 40 00 00 02 8A 80
			39 00 00 40 00 00 04 FF 5A A5 00
			39 00 00 40 00 00 02 53 28
			39 00 00 40 00 00 02 60 00
			39 00 00 40 00 00 04 FF 5A A5 2D
			39 00 00 40 00 00 03 98 03 00
			39 00 00 40 00 00 02 CD 21
			39 00 00 40 00 00 03 83 03 00
			39 00 00 40 00 00 02 F2 03

			39 00 00 40 00 00 04 FF 5A A5 07 //10bit 3.75
			39 00 00 40 00 00 02 8A 01
			39 00 00 40 00 00 03 8B 21 E0
			39 00 00 40 00 00 64 81 00 00 00 00 00 12 00 00 ab 30 80 0a dc 04 f0 00 14 02 78 02 78 02 00 02 57 00 20 01 f8 00 08 00 0d 05 7a 04 4f 18 00 10 e0 07 10 20 00 06 0f 0f 33 0e 1c 2a 38 46 54 62 69 70 77 79 7b 7d 7e 02 02 22 00 2a 40 2a be 3a fc 3a fa 3a f8 3b 38 3b 78 3b b6 4b b6 4b f4 4b f4 6c 34 84 74 00 00 00 00 00 00
			39 00 00 00 00 00 04 FF 5A A5 00

			05 00 00 00 78 00 01 11 //Delay 120ms
			39 00 00 40 00 00 04 FF 5A A5 49 //OD Code
			39 00 00 40 00 00 11 81 D2 00 BC 02 C0 03 24 05 08 07 D4 0C D2 14 74 1B
			39 00 00 40 00 00 13 82 D2 00 BC 02 C0 03 24 05 08 07 D4 0C D2 14 74 1B 00 00
			39 00 00 40 00 00 02 83 0B
			39 00 00 40 00 00 04 FF 5A A5 53
			39 00 00 40 00 00 02 86 3D //Exit 165 DC code
			39 00 00 40 00 00 04 FF 5A A5 51
			39 00 00 40 00 00 07 A1 AC AC AC AC 22 22
			39 00 00 40 00 00 07 A2 AC A5 A5 A5 22 22
			39 00 00 40 00 00 07 A3 A5 98 98 98 22 22
			39 00 00 40 00 00 04 FF 5A A5 52
			39 00 00 40 00 00 07 81 E2 94 77 77 00 00
			39 00 00 40 00 00 07 82 77 76 76 76 00 00
			39 00 00 40 00 00 07 83 76 6E 6E 6E 00 00
			39 00 00 00 00 00 04 FF 5A A5 00
			05 00 00 00 14 00 01 29];	/* display on */
		qcom,mdss-dsi-off-command = [
			39 00 00 40 00 00 04 FF 5A A5 00
			05 00 00 00 14 00 01 28		/* display_off */
			05 00 00 00 BE 00 01 10];	/* enter sleep mode */

		qcom,mdss-dsi-on-command-state = "dsi_lp_mode";
		qcom,mdss-dsi-off-command-state = "dsi_lp_mode";
		qcom,mdss-dsi-timing-switch-command-state = "dsi_lp_mode";
		qcom,compression-mode = "dsc";
		/* Why QCOM doesn't use this, even it used 2 encoder
		 * as for that dsi_sw43404_amoled_cmd, for ex */
		/* qcom,mdss-dsc-encoders = <2>; */
		qcom,mdss-dsc-version = <0x12>;
		qcom,mdss-dsc-slice-height = <20>;
		qcom,mdss-dsc-slice-width = <632>;
		qcom,mdss-dsc-slice-per-pkt = <2>;
		qcom,mdss-dsc-bit-per-component = <10>;
		qcom,mdss-dsc-bit-per-pixel = <8>;
		qcom,mdss-dsc-block-prediction-enable;
		qcom,mdss-dsi-pcd-check-enable-command = [
			39 00 00 00 00 00 04 FF 5A A5 03
			];
		qcom,mdss-dsi-pcd-check-enable-command-state = "dsi_hs_mode";
		qcom,mdss-dsi-pcd-check-disable-command = [
			39 00 00 00 00 00 04 FF 5A A5 00
			];
		qcom,mdss-dsi-pcd-check-disable-command-state = "dsi_hs_mode";
		qcom,mdss-dsi-lp1-command = [
			39 00 00 40 00 00 04 FF 5A A5 4F
			39 00 00 40 00 00 02 81 04
			39 00 00 40 00 00 04 FF 5A A5 08
			39 00 00 40 00 00 02 98 02
			39 00 00 40 00 00 04 FF 5A A5 4F
			39 00 00 40 00 00 02 88 78
			39 00 00 40 00 00 04 FF 5A A5 24
			39 00 00 40 00 00 02 86 80
			39 00 00 40 00 00 02 8A 80
			39 00 00 40 00 00 04 FF 5A A5 00
			39 00 00 40 00 00 02 53 28
			39 00 00 40 00 00 02 60 00
			39 00 00 40 00 00 04 FF 5A A5 2D
			39 00 00 40 00 00 03 98 03 00
			39 00 00 40 00 00 02 CD 21
			39 00 00 40 00 00 03 83 03 00
			39 00 00 40 00 00 02 F2 03
			39 00 00 40 00 00 04 FF 5A A5 53
			39 00 00 40 00 00 02 86 3D //Exit 165 DC code
			39 00 00 40 00 00 04 FF 5A A5 08
			39 00 00 40 00 00 02 98 A6
			39 00 00 40 00 00 04 FF 5A A5 00
			39 00 00 40 00 00 02 00 00
			39 00 00 40 00 00 04 FF 5A A5 4F
			39 00 00 40 00 00 02 8B 78
			39 00 00 00 00 00 04 FF 5A A5 00
		];
		qcom,mdss-dsi-lp1-command-state =
			"dsi_lp_mode";
		qcom,mdss-dsi-lp2-command = [
			39 00 00 40 00 00 04 FF 5A A5 4F
			39 00 00 40 00 00 02 81 04
			39 00 00 40 00 00 04 FF 5A A5 08
			39 00 00 40 00 00 02 98 02
			39 00 00 40 00 00 04 FF 5A A5 4F
			39 00 00 40 00 00 02 88 78
			39 00 00 40 00 00 04 FF 5A A5 24
			39 00 00 40 00 00 02 86 00
			39 00 00 40 00 00 02 8A 00
			39 00 00 40 00 00 04 FF 5A A5 00
			39 00 00 40 00 00 02 53 20
			39 00 00 40 00 00 02 60 00
			39 00 00 40 00 00 04 FF 5A A5 2D
			39 00 00 40 00 00 03 98 00 00
			39 00 00 40 00 00 02 CD 01
			39 00 00 40 00 00 03 83 77 00
			39 00 00 40 00 00 02 F2 00
			39 00 00 40 00 00 04 FF 5A A5 53
			39 00 00 40 00 00 02 86 3D //Exit 165 DC code
			39 00 00 40 00 00 04 FF 5A A5 08
			39 00 00 40 00 00 02 98 A6
			39 00 00 40 00 00 04 FF 5A A5 00
			39 00 00 40 00 00 02 00 00
			39 00 00 40 00 00 04 FF 5A A5 4F
			39 00 00 40 00 00 02 8B 78
			39 00 00 00 00 00 04 FF 5A A5 00
		];
		qcom,mdss-dsi-lp2-command-state =
			"dsi_lp_mode";
		qcom,mdss-dsi-nolp-command = [
			39 00 00 40 00 00 04 FF 5A A5 4F
			39 00 00 40 00 00 02 81 04
			39 00 00 40 00 00 04 FF 5A A5 08
			39 00 00 40 00 00 02 98 02
			39 00 00 40 00 00 04 FF 5A A5 4F
			39 00 00 40 00 00 02 88 78
			39 00 00 40 00 00 04 FF 5A A5 24
			39 00 00 40 00 00 02 86 80
			39 00 00 40 00 00 02 8A 80
			39 00 00 40 00 00 04 FF 5A A5 00
			39 00 00 40 00 00 02 53 28
			39 00 00 40 00 00 02 60 00
			39 00 00 40 00 00 04 FF 5A A5 2D
			39 00 00 40 00 00 03 98 03 00
			39 00 00 40 00 00 02 CD 21
			39 00 00 40 00 00 03 83 03 00
			39 00 00 40 00 00 02 F2 03
			39 00 00 40 00 00 04 FF 5A A5 53
			39 00 00 40 00 00 02 86 3D //Exit 165 DC code
			39 00 00 40 00 00 04 FF 5A A5 08
			39 00 00 40 00 00 02 98 A6
			39 00 00 40 00 00 04 FF 5A A5 00
			39 00 00 40 00 00 02 00 00
			39 00 00 40 00 00 04 FF 5A A5 4F
			39 00 00 40 00 00 02 8B 78
			39 00 00 00 00 00 04 FF 5A A5 00
		];
		qcom,mdss-dsi-nolp-command-state =
			"dsi_lp_mode";
	};

	timing@5{
		qcom,mdss-dsi-cmd-mode;
		qcom,mdss-dsi-panel-framerate = <24>;
		qcom,mdss-dsi-panel-width = <1264>;
		qcom,mdss-dsi-panel-height = <2780>;
		qcom,mdss-dsi-h-front-porch = <31>;
		qcom,mdss-dsi-h-back-porch = <32>;
		qcom,mdss-dsi-h-pulse-width = <16>;
		qcom,mdss-dsi-h-sync-skew = <0>;
		qcom,mdss-dsi-h-sync-pulse = <0>;
		qcom,mdss-dsi-v-back-porch = <42>;
		qcom,mdss-dsi-v-front-porch = <58>;
		qcom,mdss-dsi-v-pulse-width = <2>;
		qcom,mdss-dsi-h-left-border = <0>;
		qcom,mdss-dsi-h-right-border = <0>;
		qcom,mdss-dsi-v-top-border = <0>;
		qcom,mdss-dsi-v-bottom-border = <0>;
	        qcom,mdss-dsi-panel-jitter = <0x20 0xa>;
	        qcom,mdss-mdp-transfer-time-us = <7933>;
	        qcom,mdss-dsi-timing-switch-command = [
			39 00 00 40 00 00 04 FF 5A A5 4F
			39 00 00 40 00 00 02 81 04
			39 00 00 40 00 00 04 FF 5A A5 08
			39 00 00 40 00 00 02 98 02
			39 00 00 40 00 00 04 FF 5A A5 4F
			39 00 00 40 00 00 02 88 78
			39 00 00 40 00 00 04 FF 5A A5 24
			39 00 00 40 00 00 02 86 80
			39 00 00 40 00 00 02 8A 80
			39 00 00 40 00 00 04 FF 5A A5 00
			39 00 00 40 00 00 02 53 28
			39 00 00 40 00 00 02 60 00
			39 00 00 40 00 00 04 FF 5A A5 2D
			39 00 00 40 00 00 03 98 04 00
			39 00 00 40 00 00 02 CD 21
			39 00 00 40 00 00 03 83 04 00
			39 00 00 40 00 00 02 F2 04
			39 00 00 40 00 00 04 FF 5A A5 53
			39 00 00 40 00 00 02 86 3D //Exit 165 DC code
			39 00 00 40 00 00 04 FF 5A A5 08
			39 00 00 40 00 00 02 98 A6
			39 00 00 40 00 00 04 FF 5A A5 00
			39 00 00 40 00 00 02 00 00
			39 00 00 40 00 00 04 FF 5A A5 4F
			39 00 00 40 00 00 02 8B 78
			39 00 00 00 2a 00 04 FF 5A A5 00
	        ];
		qcom,mdss-dsi-on-command = [
			39 00 00 40 00 00 04 FF 5A A5 00 //ODC dbv420 and 10nit
			39 00 00 40 00 00 02 4D 01
			39 00 00 40 00 00 04 FF 5A A5 4F
			39 00 00 40 00 00 02 A1 00
			39 00 00 40 00 00 02 A2 01
			39 00 00 40 00 00 02 A3 A4
			39 00 00 40 00 00 02 A4 0A
			39 00 00 40 00 00 02 A5 48
			39 00 00 40 00 00 04 FF 5A A5 71
			39 00 00 40 00 00 07 85 00 80 0A F3 00 00
			39 00 00 40 00 00 07 86 00 66 09 8F 04 00
			39 00 00 40 00 00 07 87 00 60 09 36 14 00
			39 00 00 40 00 00 07 88 00 53 08 84 24 00
			39 00 00 40 00 00 07 89 00 46 07 D2 04 00
			39 00 00 40 00 00 07 8A 00 80 18 B3 00 00
			39 00 00 40 00 00 07 8B 00 66 17 C2 04 00
			39 00 00 40 00 00 07 8C 00 60 17 86 14 00
			39 00 00 40 00 00 07 8D 00 53 17 0E 24 00
			39 00 00 40 00 00 07 8E 00 46 16 95 04 00
			39 00 00 40 00 00 07 8F 00 80 26 00 00 00
			39 00 00 40 00 00 07 90 00 66 25 99 04 00
			39 00 00 40 00 00 07 91 00 60 25 80 14 00
			39 00 00 40 00 00 07 92 00 53 25 4C 24 00
			39 00 00 40 00 00 07 93 00 46 25 19 04 00
			39 00 00 40 00 00 07 94 00 80 04 00 00 00
			39 00 00 40 00 00 07 95 00 66 04 00 04 00
			39 00 00 40 00 00 07 96 00 60 04 00 14 00
			39 00 00 40 00 00 07 97 00 53 04 00 24 00
			39 00 00 40 00 00 07 98 00 46 04 00 04 00
			39 00 00 40 00 00 07 99 0C 19 00 80 00 00
			39 00 00 40 00 00 07 9A 0A 7B 00 66 04 00
			39 00 00 40 00 00 07 9B 0A 13 00 60 14 00
			39 00 00 40 00 00 07 9C 09 43 00 53 24 00
			39 00 00 40 00 00 07 9D 08 74 00 46 04 00
			39 00 00 40 00 00 07 9E 04 00 0A 00 00 00
			39 00 00 40 00 00 07 A3 04 00 16 80 00 00
			39 00 00 40 00 00 07 A4 04 00 16 00 04 00
			39 00 00 40 00 00 07 B2 19 EC 00 80 00 00
			39 00 00 40 00 00 07 B3 18 BD 00 66 04 00
			39 00 00 40 00 00 07 B4 18 71 00 60 14 00
			39 00 00 40 00 00 07 B5 17 DA 00 53 24 00
			39 00 00 40 00 00 07 B6 17 42 00 46 04 00
			39 00 00 40 00 00 07 CB 25 B9 00 80 00 00
			39 00 00 40 00 00 07 CC 25 61 00 66 04 00
			39 00 00 40 00 00 07 CD 25 4B 00 60 14 00
			39 00 00 40 00 00 07 CE 25 1F 00 53 24 00
			39 00 00 40 00 00 07 CF 24 F2 00 46 04 00
			39 00 00 40 00 00 07 E4 04 00 00 80 00 00
			39 00 00 40 00 00 07 E5 04 00 00 66 04 00
			39 00 00 40 00 00 07 E6 04 00 00 60 14 00
			39 00 00 40 00 00 07 E7 04 00 00 53 24 00
			39 00 00 40 00 00 07 E8 04 00 00 46 04 00
			39 00 00 40 00 00 04 FF 5A A5 49
			39 00 00 40 00 00 02 E0 01
			39 00 00 40 00 00 04 FF 5A A5 5B
			39 00 00 40 00 00 04 C8 03 06 01
			39 00 00 40 00 00 04 C9 04 07 01
			39 00 00 40 00 00 04 CA 00 00 00
			39 00 00 40 00 00 04 CB 06 07 03
			39 00 00 40 00 00 04 CC 01 00 00
			39 00 00 40 00 00 04 CD 00 00 00
			39 00 00 40 00 00 04 CE 09 09 07
			39 00 00 40 00 00 04 CF 03 02 02
			39 00 00 40 00 00 04 D0 02 01 01
			39 00 00 40 00 00 04 D1 00 00 00
			39 00 00 40 00 00 04 D2 16 12 13
			39 00 00 40 00 00 04 D3 09 07 07
			39 00 00 40 00 00 04 D4 07 06 06
			39 00 00 40 00 00 04 D5 03 03 02
			39 00 00 40 00 00 04 D6 00 00 00
			39 00 00 40 00 00 04 D7 19 15 16
			39 00 00 40 00 00 04 D8 0B 08 08
			39 00 00 40 00 00 04 D9 09 07 07
			39 00 00 40 00 00 04 DA 04 04 03
			39 00 00 40 00 00 04 DB 00 00 00
			39 00 00 40 00 00 04 DC 00 00 00
			39 00 00 40 00 00 04 DD 24 21 1F
			39 00 00 40 00 00 04 DE 13 10 0D
			39 00 00 40 00 00 04 DF 10 0E 0C
			39 00 00 40 00 00 04 E0 09 09 06
			39 00 00 40 00 00 04 E1 01 02 01
			39 00 00 40 00 00 04 E2 00 00 00
			39 00 00 40 00 00 04 E3 00 00 00
			39 00 00 40 00 00 04 E4 2E 2B 26
			39 00 00 40 00 00 04 E5 1B 17 12
			39 00 00 40 00 00 04 E6 18 15 10
			39 00 00 40 00 00 04 E7 0E 0F 09
			39 00 00 40 00 00 04 E8 04 04 01
			39 00 00 40 00 00 04 E9 00 00 00
			39 00 00 40 00 00 04 EA 00 00 00
			39 00 00 40 00 00 04 EB 00 00 00
			39 00 00 40 00 00 04 FF 5A A5 5C
			39 00 00 40 00 00 04 80 02 02 01
			39 00 00 40 00 00 04 81 02 02 01
			39 00 00 40 00 00 04 82 00 00 00
			39 00 00 40 00 00 04 83 04 04 02
			39 00 00 40 00 00 04 84 00 00 00
			39 00 00 40 00 00 04 85 00 00 00
			39 00 00 40 00 00 04 86 08 07 07
			39 00 00 40 00 00 04 87 02 02 01
			39 00 00 40 00 00 04 88 01 01 01
			39 00 00 40 00 00 04 89 00 00 00
			39 00 00 40 00 00 04 8A 13 11 10
			39 00 00 40 00 00 04 8B 07 07 05
			39 00 00 40 00 00 04 8C 06 06 04
			39 00 00 40 00 00 04 8D 01 02 01
			39 00 00 40 00 00 04 8E 00 00 00
			39 00 00 40 00 00 04 8F 16 14 12
			39 00 00 40 00 00 04 90 09 08 06
			39 00 00 40 00 00 04 91 07 07 04
			39 00 00 40 00 00 04 92 02 02 01
			39 00 00 40 00 00 04 93 00 00 00
			39 00 00 40 00 00 04 94 00 00 00
			39 00 00 40 00 00 04 95 30 2C 18
			39 00 00 40 00 00 04 96 0E 0D 08
			39 00 00 40 00 00 04 97 0B 0B 06
			39 00 00 40 00 00 04 98 05 05 01
			39 00 00 40 00 00 04 99 01 01 00
			39 00 00 40 00 00 04 9A 00 00 00
			39 00 00 40 00 00 04 9B 00 00 00
			39 00 00 40 00 00 04 9C 45 33 1D
			39 00 00 40 00 00 04 9D 12 11 09
			39 00 00 40 00 00 04 9E 0F 0F 07
			39 00 00 40 00 00 04 9F 07 08 01
			39 00 00 40 00 00 04 A0 01 01 00
			39 00 00 40 00 00 04 A1 00 00 00
			39 00 00 40 00 00 04 A2 00 00 00
			39 00 00 40 00 00 04 A3 00 00 00
			39 00 00 40 00 00 04 CE 10 18 10
			39 00 00 40 00 00 04 CF 10 18 10

			39 00 00 40 00 00 04 FF 5A A5 06 //esd check
			39 00 00 40 00 00 02 C6 01
			39 00 00 40 00 00 04 FF 5A A5 08
			39 00 00 40 00 00 02 D2 05
			39 00 00 40 00 00 09 ED FF FF FF FF FF FF 45 FF
			39 00 00 40 00 00 09 EE FF FD FF FD F9 FA BE 76
			39 00 00 40 00 00 04 FF 5A A5 00

			39 00 00 40 00 00 04 FF 5A A5 03 //Power on code
			39 00 00 40 00 00 04 90 01 80 23
			39 00 00 40 00 00 04 FF 5A A5 08
			39 00 00 40 00 00 02 E0 22
			39 00 00 40 00 00 04 FF 5A A5 09
			39 00 00 40 00 00 02 A1 03
			39 00 00 40 00 00 04 FF 5A A5 1E
			39 00 00 40 00 00 02 C1 70
			39 00 00 40 00 00 04 FF 5A A5 05
			39 00 00 40 00 00 02 83 01
			39 00 00 40 00 00 02 84 01
			39 00 00 40 00 00 04 FF 5A A5 1C
			39 00 00 40 00 00 15 E1 10 80 9A 65 59 54 69 95 56 6A 55 99 9A 55 55 25 58 55 66 A2
			39 00 00 40 00 00 04 FF 5A A5 20
			39 00 00 40 00 00 02 D5 10
			39 00 00 40 00 00 02 BC 06
			39 00 00 40 00 00 04 FF 5A A5 02
			39 00 00 40 00 00 03 AB AF 86

			39 00 00 40 00 00 04 FF 5A A5 4B //pcd check code
			39 00 00 40 00 00 02 EE 10
			39 00 00 40 00 00 04 FF 5A A5 03
			39 00 00 40 00 00 02 BD D1
			39 00 00 40 00 00 02 BB 29
			39 00 00 40 00 00 04 FF 5A A5 1C
			39 00 00 40 00 00 02 D3 43

			39 00 00 40 00 00 04 FF 5A A5 08
			39 00 00 40 00 00 02 C8 62
			39 00 00 40 00 00 04 FF 5A A5 21
			39 00 00 40 00 00 02 A4 38
			39 00 00 40 00 00 04 FF 5A A5 23
			39 00 00 40 00 00 02 85 15
			39 00 00 40 00 00 04 FF 5A A5 01
			39 00 00 40 00 00 02 FB 08
			39 00 00 40 00 00 04 FF 5A A5 00
			39 00 00 40 00 00 02 5E 01
			39 00 00 40 00 00 02 60 00
			39 00 00 40 00 00 02 61 08
			39 00 00 40 00 00 01 35
			39 00 00 40 00 00 02 53 20
			39 00 00 40 00 00 03 51 00 00

			39 00 00 40 00 00 04 FF 5A A5 24 //DBV Diming
			39 00 00 40 00 00 02 85 31
			39 00 00 40 00 00 02 89 31
			39 00 00 40 00 00 04 FF 5A A5 2D
			39 00 00 40 00 00 02 CE 55
			39 00 00 40 00 00 04 FF 5A A5 5A //OD LUT
			39 00 00 40 00 00 04 80 00 01 00
			39 00 00 40 00 00 04 81 00 02 01
			39 00 00 40 00 00 04 82 00 00 00
			39 00 00 40 00 00 04 83 03 0B 04
			39 00 00 40 00 00 04 84 02 05 00
			39 00 00 40 00 00 04 85 02 05 00
			39 00 00 40 00 00 04 86 11 24 11
			39 00 00 40 00 00 04 87 0B 0A 03
			39 00 00 40 00 00 04 88 09 08 03
			39 00 00 40 00 00 04 89 05 04 03
			39 00 00 40 00 00 04 8A 1A 1E 21
			39 00 00 40 00 00 04 8B 11 0D 0F
			39 00 00 40 00 00 04 8C 11 0B 0D
			39 00 00 40 00 00 04 8D 0B 07 0B
			39 00 00 40 00 00 04 8E 05 04 08
			39 00 00 40 00 00 04 8F 26 26 26
			39 00 00 40 00 00 04 90 15 0E 13
			39 00 00 40 00 00 04 91 14 0C 12
			39 00 00 40 00 00 04 92 0F 08 0F
			39 00 00 40 00 00 04 93 08 05 0B
			39 00 00 40 00 00 04 94 00 00 00
			39 00 00 40 00 00 04 95 3E 32 32
			39 00 00 40 00 00 04 96 24 14 26
			39 00 00 40 00 00 04 97 21 12 21
			39 00 00 40 00 00 04 98 1D 10 20
			39 00 00 40 00 00 04 99 12 0B 16
			39 00 00 40 00 00 04 9A 09 05 0B
			39 00 00 40 00 00 04 9B 06 03 08
			39 00 00 40 00 00 04 9C 32 35 2D
			39 00 00 40 00 00 04 9D 36 19 2C
			39 00 00 40 00 00 04 9E 32 18 30
			39 00 00 40 00 00 04 9F 2A 16 29
			39 00 00 40 00 00 04 A0 1D 12 21
			39 00 00 40 00 00 04 A1 12 09 15
			39 00 00 40 00 00 04 A2 0F 07 11
			39 00 00 40 00 00 04 FF 5A A5 5C
			39 00 00 40 00 00 04 C8 0C 0A 05

			39 00 00 40 00 00 04 FF 5A A5 24 //switch 24hz
			39 00 00 40 00 00 02 86 80
			39 00 00 40 00 00 02 8A 80
			39 00 00 40 00 00 04 FF 5A A5 00
			39 00 00 40 00 00 02 53 28
			39 00 00 40 00 00 02 60 00
			39 00 00 40 00 00 04 FF 5A A5 2D
			39 00 00 40 00 00 03 98 04 00
			39 00 00 40 00 00 02 CD 21
			39 00 00 40 00 00 03 83 04 00
			39 00 00 40 00 00 02 F2 04

			39 00 00 40 00 00 04 FF 5A A5 07 //10bit 3.75
			39 00 00 40 00 00 02 8A 01
			39 00 00 40 00 00 03 8B 21 E0
			39 00 00 40 00 00 64 81 00 00 00 00 00 12 00 00 ab 30 80 0a dc 04 f0 00 14 02 78 02 78 02 00 02 57 00 20 01 f8 00 08 00 0d 05 7a 04 4f 18 00 10 e0 07 10 20 00 06 0f 0f 33 0e 1c 2a 38 46 54 62 69 70 77 79 7b 7d 7e 02 02 22 00 2a 40 2a be 3a fc 3a fa 3a f8 3b 38 3b 78 3b b6 4b b6 4b f4 4b f4 6c 34 84 74 00 00 00 00 00 00
			39 00 00 00 00 00 04 FF 5A A5 00

			05 00 00 00 78 00 01 11 //Delay 120ms
			39 00 00 40 00 00 04 FF 5A A5 49 //OD Code
			39 00 00 40 00 00 11 81 D2 00 BC 02 C0 03 24 05 08 07 D4 0C D2 14 74 1B
			39 00 00 40 00 00 13 82 D2 00 BC 02 C0 03 24 05 08 07 D4 0C D2 14 74 1B 00 00
			39 00 00 40 00 00 02 83 0B
			39 00 00 40 00 00 04 FF 5A A5 53
			39 00 00 40 00 00 02 86 3D //Exit 165 DC code
			39 00 00 40 00 00 04 FF 5A A5 51
			39 00 00 40 00 00 07 A1 AC AC AC AC 22 22
			39 00 00 40 00 00 07 A2 AC A5 A5 A5 22 22
			39 00 00 40 00 00 07 A3 A5 98 98 98 22 22
			39 00 00 40 00 00 04 FF 5A A5 52
			39 00 00 40 00 00 07 81 E2 94 77 77 00 00
			39 00 00 40 00 00 07 82 77 76 76 76 00 00
			39 00 00 40 00 00 07 83 76 6E 6E 6E 00 00
			39 00 00 00 00 00 04 FF 5A A5 00
			05 00 00 00 14 00 01 29];	/* display on */
		qcom,mdss-dsi-off-command = [
			39 00 00 40 00 00 04 FF 5A A5 00
			05 00 00 00 14 00 01 28		/* display_off */
			05 00 00 00 BE 00 01 10];	/* enter sleep mode */

		qcom,mdss-dsi-on-command-state = "dsi_lp_mode";
		qcom,mdss-dsi-off-command-state = "dsi_lp_mode";
		qcom,mdss-dsi-timing-switch-command-state = "dsi_lp_mode";
		qcom,compression-mode = "dsc";
		/* Why QCOM doesn't use this, even it used 2 encoder
		 * as for that dsi_sw43404_amoled_cmd, for ex */
		/* qcom,mdss-dsc-encoders = <2>; */
		qcom,mdss-dsc-version = <0x12>;
		qcom,mdss-dsc-slice-height = <20>;
		qcom,mdss-dsc-slice-width = <632>;
		qcom,mdss-dsc-slice-per-pkt = <2>;
		qcom,mdss-dsc-bit-per-component = <10>;
		qcom,mdss-dsc-bit-per-pixel = <8>;
		qcom,mdss-dsc-block-prediction-enable;
		qcom,mdss-dsi-pcd-check-enable-command = [
			39 00 00 00 00 00 04 FF 5A A5 03
			];
		qcom,mdss-dsi-pcd-check-enable-command-state = "dsi_hs_mode";
		qcom,mdss-dsi-pcd-check-disable-command = [
			39 00 00 00 00 00 04 FF 5A A5 00
			];
		qcom,mdss-dsi-pcd-check-disable-command-state = "dsi_hs_mode";
		qcom,mdss-dsi-lp1-command = [
			39 00 00 40 00 00 04 FF 5A A5 4F
			39 00 00 40 00 00 02 81 04
			39 00 00 40 00 00 04 FF 5A A5 08
			39 00 00 40 00 00 02 98 02
			39 00 00 40 00 00 04 FF 5A A5 4F
			39 00 00 40 00 00 02 88 78
			39 00 00 40 00 00 04 FF 5A A5 24
			39 00 00 40 00 00 02 86 80
			39 00 00 40 00 00 02 8A 80
			39 00 00 40 00 00 04 FF 5A A5 00
			39 00 00 40 00 00 02 53 28
			39 00 00 40 00 00 02 60 00
			39 00 00 40 00 00 04 FF 5A A5 2D
			39 00 00 40 00 00 03 98 04 00
			39 00 00 40 00 00 02 CD 21
			39 00 00 40 00 00 03 83 04 00
			39 00 00 40 00 00 02 F2 04
			39 00 00 40 00 00 04 FF 5A A5 53
			39 00 00 40 00 00 02 86 3D //Exit 165 DC code
			39 00 00 40 00 00 04 FF 5A A5 08
			39 00 00 40 00 00 02 98 A6
			39 00 00 40 00 00 04 FF 5A A5 00
			39 00 00 40 00 00 02 00 00
			39 00 00 40 00 00 04 FF 5A A5 4F
			39 00 00 40 00 00 02 8B 78
			39 00 00 00 00 00 04 FF 5A A5 00
		];
		qcom,mdss-dsi-lp1-command-state =
			"dsi_lp_mode";
		qcom,mdss-dsi-lp2-command = [
			39 00 00 40 00 00 04 FF 5A A5 4F
			39 00 00 40 00 00 02 81 04
			39 00 00 40 00 00 04 FF 5A A5 08
			39 00 00 40 00 00 02 98 02
			39 00 00 40 00 00 04 FF 5A A5 4F
			39 00 00 40 00 00 02 88 78
			39 00 00 40 00 00 04 FF 5A A5 24
			39 00 00 40 00 00 02 86 00
			39 00 00 40 00 00 02 8A 00
			39 00 00 40 00 00 04 FF 5A A5 00
			39 00 00 40 00 00 02 53 20
			39 00 00 40 00 00 02 60 00
			39 00 00 40 00 00 04 FF 5A A5 2D
			39 00 00 40 00 00 03 98 00 00
			39 00 00 40 00 00 02 CD 01
			39 00 00 40 00 00 03 83 77 00
			39 00 00 40 00 00 02 F2 00
			39 00 00 40 00 00 04 FF 5A A5 53
			39 00 00 40 00 00 02 86 3D //Exit 165 DC code
			39 00 00 40 00 00 04 FF 5A A5 08
			39 00 00 40 00 00 02 98 A6
			39 00 00 40 00 00 04 FF 5A A5 00
			39 00 00 40 00 00 02 00 00
			39 00 00 40 00 00 04 FF 5A A5 4F
			39 00 00 40 00 00 02 8B 78
			39 00 00 00 00 00 04 FF 5A A5 00
		];
		qcom,mdss-dsi-lp2-command-state =
			"dsi_lp_mode";
		qcom,mdss-dsi-nolp-command = [
			39 00 00 40 00 00 04 FF 5A A5 4F
			39 00 00 40 00 00 02 81 04
			39 00 00 40 00 00 04 FF 5A A5 08
			39 00 00 40 00 00 02 98 02
			39 00 00 40 00 00 04 FF 5A A5 4F
			39 00 00 40 00 00 02 88 78
			39 00 00 40 00 00 04 FF 5A A5 24
			39 00 00 40 00 00 02 86 80
			39 00 00 40 00 00 02 8A 80
			39 00 00 40 00 00 04 FF 5A A5 00
			39 00 00 40 00 00 02 53 28
			39 00 00 40 00 00 02 60 00
			39 00 00 40 00 00 04 FF 5A A5 2D
			39 00 00 40 00 00 03 98 04 00
			39 00 00 40 00 00 02 CD 21
			39 00 00 40 00 00 03 83 04 00
			39 00 00 40 00 00 02 F2 04
			39 00 00 40 00 00 04 FF 5A A5 53
			39 00 00 40 00 00 02 86 3D //Exit 165 DC code
			39 00 00 40 00 00 04 FF 5A A5 08
			39 00 00 40 00 00 02 98 A6
			39 00 00 40 00 00 04 FF 5A A5 00
			39 00 00 40 00 00 02 00 00
			39 00 00 40 00 00 04 FF 5A A5 4F
			39 00 00 40 00 00 02 8B 78
			39 00 00 00 00 00 04 FF 5A A5 00
		];
		qcom,mdss-dsi-nolp-command-state =
			"dsi_lp_mode";
	};

	timing@6{
		qcom,mdss-dsi-cmd-mode;
		qcom,mdss-dsi-panel-framerate = <120>;  /* Actually 10 hz*/
		qcom,mdss-dsi-panel-width = <1264>;
		qcom,mdss-dsi-panel-height = <2780>;
		qcom,mdss-dsi-h-front-porch = <35>;
		qcom,mdss-dsi-h-back-porch = <32>;
		qcom,mdss-dsi-h-pulse-width = <16>;
		qcom,mdss-dsi-h-sync-skew = <0>;
		qcom,mdss-dsi-h-sync-pulse = <0>;
		qcom,mdss-dsi-v-back-porch = <42>;
		qcom,mdss-dsi-v-front-porch = <58>;
		qcom,mdss-dsi-v-pulse-width = <2>;
		qcom,mdss-dsi-h-left-border = <0>;
		qcom,mdss-dsi-h-right-border = <0>;
		qcom,mdss-dsi-v-top-border = <0>;
		qcom,mdss-dsi-v-bottom-border = <0>;
	        qcom,mdss-dsi-panel-jitter = <0x20 0xa>;
	        qcom,mdss-mdp-transfer-time-us = <7933>;
	        qcom,mdss-dsi-timing-switch-command = [
			39 00 00 40 00 00 04 FF 5A A5 4F
			39 00 00 40 00 00 02 81 04
			39 00 00 40 00 00 04 FF 5A A5 08
			39 00 00 40 00 00 02 98 02
			39 00 00 40 00 00 04 FF 5A A5 4F
			39 00 00 40 00 00 02 88 78
			39 00 00 40 00 00 04 FF 5A A5 24
			39 00 00 40 00 00 02 86 00
			39 00 00 40 00 00 02 8A 00
			39 00 00 40 00 00 04 FF 5A A5 00
			39 00 00 40 00 00 02 53 20
			39 00 00 40 00 00 02 60 00
			39 00 00 40 00 00 04 FF 5A A5 2D
			39 00 00 40 00 00 03 98 00 00
			39 00 00 40 00 00 02 CD 01
			39 00 00 40 00 00 03 83 0B 00
			39 00 00 40 00 00 02 F2 00
			39 00 00 40 00 00 04 FF 5A A5 53
			39 00 00 40 00 00 02 86 3D //Exit 165 DC code
			39 00 00 40 00 00 04 FF 5A A5 08
			39 00 00 40 00 00 02 98 A6
			39 00 00 40 00 00 04 FF 5A A5 00
			39 00 00 40 00 00 02 00 00
			39 00 00 40 00 00 04 FF 5A A5 4F
			39 00 00 40 00 00 02 8B 78
			39 00 00 00 00 00 04 FF 5A A5 00
	        ];
		qcom,mdss-dsi-on-command = [
			39 00 00 40 00 00 04 FF 5A A5 00 //ODC dbv420 and 10nit
			39 00 00 40 00 00 02 4D 01
			39 00 00 40 00 00 04 FF 5A A5 4F
			39 00 00 40 00 00 02 A1 00
			39 00 00 40 00 00 02 A2 01
			39 00 00 40 00 00 02 A3 A4
			39 00 00 40 00 00 02 A4 0A
			39 00 00 40 00 00 02 A5 48
			39 00 00 40 00 00 04 FF 5A A5 71
			39 00 00 40 00 00 07 85 00 80 0A F3 00 00
			39 00 00 40 00 00 07 86 00 66 09 8F 04 00
			39 00 00 40 00 00 07 87 00 60 09 36 14 00
			39 00 00 40 00 00 07 88 00 53 08 84 24 00
			39 00 00 40 00 00 07 89 00 46 07 D2 04 00
			39 00 00 40 00 00 07 8A 00 80 18 B3 00 00
			39 00 00 40 00 00 07 8B 00 66 17 C2 04 00
			39 00 00 40 00 00 07 8C 00 60 17 86 14 00
			39 00 00 40 00 00 07 8D 00 53 17 0E 24 00
			39 00 00 40 00 00 07 8E 00 46 16 95 04 00
			39 00 00 40 00 00 07 8F 00 80 26 00 00 00
			39 00 00 40 00 00 07 90 00 66 25 99 04 00
			39 00 00 40 00 00 07 91 00 60 25 80 14 00
			39 00 00 40 00 00 07 92 00 53 25 4C 24 00
			39 00 00 40 00 00 07 93 00 46 25 19 04 00
			39 00 00 40 00 00 07 94 00 80 04 00 00 00
			39 00 00 40 00 00 07 95 00 66 04 00 04 00
			39 00 00 40 00 00 07 96 00 60 04 00 14 00
			39 00 00 40 00 00 07 97 00 53 04 00 24 00
			39 00 00 40 00 00 07 98 00 46 04 00 04 00
			39 00 00 40 00 00 07 99 0C 19 00 80 00 00
			39 00 00 40 00 00 07 9A 0A 7B 00 66 04 00
			39 00 00 40 00 00 07 9B 0A 13 00 60 14 00
			39 00 00 40 00 00 07 9C 09 43 00 53 24 00
			39 00 00 40 00 00 07 9D 08 74 00 46 04 00
			39 00 00 40 00 00 07 9E 04 00 0A 00 00 00
			39 00 00 40 00 00 07 A3 04 00 16 80 00 00
			39 00 00 40 00 00 07 A4 04 00 16 00 04 00
			39 00 00 40 00 00 07 B2 19 EC 00 80 00 00
			39 00 00 40 00 00 07 B3 18 BD 00 66 04 00
			39 00 00 40 00 00 07 B4 18 71 00 60 14 00
			39 00 00 40 00 00 07 B5 17 DA 00 53 24 00
			39 00 00 40 00 00 07 B6 17 42 00 46 04 00
			39 00 00 40 00 00 07 CB 25 B9 00 80 00 00
			39 00 00 40 00 00 07 CC 25 61 00 66 04 00
			39 00 00 40 00 00 07 CD 25 4B 00 60 14 00
			39 00 00 40 00 00 07 CE 25 1F 00 53 24 00
			39 00 00 40 00 00 07 CF 24 F2 00 46 04 00
			39 00 00 40 00 00 07 E4 04 00 00 80 00 00
			39 00 00 40 00 00 07 E5 04 00 00 66 04 00
			39 00 00 40 00 00 07 E6 04 00 00 60 14 00
			39 00 00 40 00 00 07 E7 04 00 00 53 24 00
			39 00 00 40 00 00 07 E8 04 00 00 46 04 00
			39 00 00 40 00 00 04 FF 5A A5 49
			39 00 00 40 00 00 02 E0 01
			39 00 00 40 00 00 04 FF 5A A5 5B
			39 00 00 40 00 00 04 C8 03 06 01
			39 00 00 40 00 00 04 C9 04 07 01
			39 00 00 40 00 00 04 CA 00 00 00
			39 00 00 40 00 00 04 CB 06 07 03
			39 00 00 40 00 00 04 CC 01 00 00
			39 00 00 40 00 00 04 CD 00 00 00
			39 00 00 40 00 00 04 CE 09 09 07
			39 00 00 40 00 00 04 CF 03 02 02
			39 00 00 40 00 00 04 D0 02 01 01
			39 00 00 40 00 00 04 D1 00 00 00
			39 00 00 40 00 00 04 D2 16 12 13
			39 00 00 40 00 00 04 D3 09 07 07
			39 00 00 40 00 00 04 D4 07 06 06
			39 00 00 40 00 00 04 D5 03 03 02
			39 00 00 40 00 00 04 D6 00 00 00
			39 00 00 40 00 00 04 D7 19 15 16
			39 00 00 40 00 00 04 D8 0B 08 08
			39 00 00 40 00 00 04 D9 09 07 07
			39 00 00 40 00 00 04 DA 04 04 03
			39 00 00 40 00 00 04 DB 00 00 00
			39 00 00 40 00 00 04 DC 00 00 00
			39 00 00 40 00 00 04 DD 24 21 1F
			39 00 00 40 00 00 04 DE 13 10 0D
			39 00 00 40 00 00 04 DF 10 0E 0C
			39 00 00 40 00 00 04 E0 09 09 06
			39 00 00 40 00 00 04 E1 01 02 01
			39 00 00 40 00 00 04 E2 00 00 00
			39 00 00 40 00 00 04 E3 00 00 00
			39 00 00 40 00 00 04 E4 2E 2B 26
			39 00 00 40 00 00 04 E5 1B 17 12
			39 00 00 40 00 00 04 E6 18 15 10
			39 00 00 40 00 00 04 E7 0E 0F 09
			39 00 00 40 00 00 04 E8 04 04 01
			39 00 00 40 00 00 04 E9 00 00 00
			39 00 00 40 00 00 04 EA 00 00 00
			39 00 00 40 00 00 04 EB 00 00 00
			39 00 00 40 00 00 04 FF 5A A5 5C
			39 00 00 40 00 00 04 80 02 02 01
			39 00 00 40 00 00 04 81 02 02 01
			39 00 00 40 00 00 04 82 00 00 00
			39 00 00 40 00 00 04 83 04 04 02
			39 00 00 40 00 00 04 84 00 00 00
			39 00 00 40 00 00 04 85 00 00 00
			39 00 00 40 00 00 04 86 08 07 07
			39 00 00 40 00 00 04 87 02 02 01
			39 00 00 40 00 00 04 88 01 01 01
			39 00 00 40 00 00 04 89 00 00 00
			39 00 00 40 00 00 04 8A 13 11 10
			39 00 00 40 00 00 04 8B 07 07 05
			39 00 00 40 00 00 04 8C 06 06 04
			39 00 00 40 00 00 04 8D 01 02 01
			39 00 00 40 00 00 04 8E 00 00 00
			39 00 00 40 00 00 04 8F 16 14 12
			39 00 00 40 00 00 04 90 09 08 06
			39 00 00 40 00 00 04 91 07 07 04
			39 00 00 40 00 00 04 92 02 02 01
			39 00 00 40 00 00 04 93 00 00 00
			39 00 00 40 00 00 04 94 00 00 00
			39 00 00 40 00 00 04 95 30 2C 18
			39 00 00 40 00 00 04 96 0E 0D 08
			39 00 00 40 00 00 04 97 0B 0B 06
			39 00 00 40 00 00 04 98 05 05 01
			39 00 00 40 00 00 04 99 01 01 00
			39 00 00 40 00 00 04 9A 00 00 00
			39 00 00 40 00 00 04 9B 00 00 00
			39 00 00 40 00 00 04 9C 45 33 1D
			39 00 00 40 00 00 04 9D 12 11 09
			39 00 00 40 00 00 04 9E 0F 0F 07
			39 00 00 40 00 00 04 9F 07 08 01
			39 00 00 40 00 00 04 A0 01 01 00
			39 00 00 40 00 00 04 A1 00 00 00
			39 00 00 40 00 00 04 A2 00 00 00
			39 00 00 40 00 00 04 A3 00 00 00
			39 00 00 40 00 00 04 CE 10 18 10
			39 00 00 40 00 00 04 CF 10 18 10

			39 00 00 40 00 00 04 FF 5A A5 06 //esd check
			39 00 00 40 00 00 02 C6 01
			39 00 00 40 00 00 04 FF 5A A5 08
			39 00 00 40 00 00 02 D2 05
			39 00 00 40 00 00 09 ED FF FF FF FF FF FF 45 FF
			39 00 00 40 00 00 09 EE FF FD FF FD F9 FA BE 76
			39 00 00 40 00 00 04 FF 5A A5 00

			39 00 00 40 00 00 04 FF 5A A5 03 //Power on code
			39 00 00 40 00 00 04 90 01 80 23
			39 00 00 40 00 00 04 FF 5A A5 08
			39 00 00 40 00 00 02 E0 22
			39 00 00 40 00 00 04 FF 5A A5 09
			39 00 00 40 00 00 02 A1 03
			39 00 00 40 00 00 04 FF 5A A5 1E
			39 00 00 40 00 00 02 C1 70
			39 00 00 40 00 00 04 FF 5A A5 05
			39 00 00 40 00 00 02 83 01
			39 00 00 40 00 00 02 84 01
			39 00 00 40 00 00 04 FF 5A A5 1C
			39 00 00 40 00 00 15 E1 10 80 9A 65 59 54 69 95 56 6A 55 99 9A 55 55 25 58 55 66 A2
			39 00 00 40 00 00 04 FF 5A A5 20
			39 00 00 40 00 00 02 D5 10
			39 00 00 40 00 00 02 BC 06
			39 00 00 40 00 00 04 FF 5A A5 02
			39 00 00 40 00 00 03 AB AF 86

			39 00 00 40 00 00 04 FF 5A A5 4B //pcd check code
			39 00 00 40 00 00 02 EE 10
			39 00 00 40 00 00 04 FF 5A A5 03
			39 00 00 40 00 00 02 BD D1
			39 00 00 40 00 00 02 BB 29
			39 00 00 40 00 00 04 FF 5A A5 1C
			39 00 00 40 00 00 02 D3 43

			39 00 00 40 00 00 04 FF 5A A5 08
			39 00 00 40 00 00 02 C8 62
			39 00 00 40 00 00 04 FF 5A A5 21
			39 00 00 40 00 00 02 A4 38
			39 00 00 40 00 00 04 FF 5A A5 23
			39 00 00 40 00 00 02 85 15
			39 00 00 40 00 00 04 FF 5A A5 01
			39 00 00 40 00 00 02 FB 08
			39 00 00 40 00 00 04 FF 5A A5 00
			39 00 00 40 00 00 02 5E 01
			39 00 00 40 00 00 02 60 00
			39 00 00 40 00 00 02 61 08
			39 00 00 40 00 00 01 35
			39 00 00 40 00 00 02 53 20
			39 00 00 40 00 00 03 51 00 00

			39 00 00 40 00 00 04 FF 5A A5 24 //DBV Diming
			39 00 00 40 00 00 02 85 31
			39 00 00 40 00 00 02 89 31
			39 00 00 40 00 00 04 FF 5A A5 2D
			39 00 00 40 00 00 02 CE 55
			39 00 00 40 00 00 04 FF 5A A5 5A //OD LUT
			39 00 00 40 00 00 04 80 00 01 00
			39 00 00 40 00 00 04 81 00 02 01
			39 00 00 40 00 00 04 82 00 00 00
			39 00 00 40 00 00 04 83 03 0B 04
			39 00 00 40 00 00 04 84 02 05 00
			39 00 00 40 00 00 04 85 02 05 00
			39 00 00 40 00 00 04 86 11 24 11
			39 00 00 40 00 00 04 87 0B 0A 03
			39 00 00 40 00 00 04 88 09 08 03
			39 00 00 40 00 00 04 89 05 04 03
			39 00 00 40 00 00 04 8A 1A 1E 21
			39 00 00 40 00 00 04 8B 11 0D 0F
			39 00 00 40 00 00 04 8C 11 0B 0D
			39 00 00 40 00 00 04 8D 0B 07 0B
			39 00 00 40 00 00 04 8E 05 04 08
			39 00 00 40 00 00 04 8F 26 26 26
			39 00 00 40 00 00 04 90 15 0E 13
			39 00 00 40 00 00 04 91 14 0C 12
			39 00 00 40 00 00 04 92 0F 08 0F
			39 00 00 40 00 00 04 93 08 05 0B
			39 00 00 40 00 00 04 94 00 00 00
			39 00 00 40 00 00 04 95 3E 32 32
			39 00 00 40 00 00 04 96 24 14 26
			39 00 00 40 00 00 04 97 21 12 21
			39 00 00 40 00 00 04 98 1D 10 20
			39 00 00 40 00 00 04 99 12 0B 16
			39 00 00 40 00 00 04 9A 09 05 0B
			39 00 00 40 00 00 04 9B 06 03 08
			39 00 00 40 00 00 04 9C 32 35 2D
			39 00 00 40 00 00 04 9D 36 19 2C
			39 00 00 40 00 00 04 9E 32 18 30
			39 00 00 40 00 00 04 9F 2A 16 29
			39 00 00 40 00 00 04 A0 1D 12 21
			39 00 00 40 00 00 04 A1 12 09 15
			39 00 00 40 00 00 04 A2 0F 07 11
			39 00 00 40 00 00 04 FF 5A A5 5C
			39 00 00 40 00 00 04 C8 0C 0A 05

			39 00 00 40 00 00 04 FF 5A A5 24 //switch 10hz
			39 00 00 40 00 00 02 86 00
			39 00 00 40 00 00 02 8A 00
			39 00 00 40 00 00 04 FF 5A A5 00
			39 00 00 40 00 00 02 53 20
			39 00 00 40 00 00 02 60 00
			39 00 00 40 00 00 04 FF 5A A5 2D
			39 00 00 40 00 00 03 98 00 00
			39 00 00 40 00 00 02 CD 01
			39 00 00 40 00 00 03 83 0B 00
			39 00 00 40 00 00 02 F2 00

			39 00 00 40 00 00 04 FF 5A A5 07 //10bit 3.75
			39 00 00 40 00 00 02 8A 01
			39 00 00 40 00 00 03 8B 21 E0
			39 00 00 40 00 00 64 81 00 00 00 00 00 12 00 00 ab 30 80 0a dc 04 f0 00 14 02 78 02 78 02 00 02 57 00 20 01 f8 00 08 00 0d 05 7a 04 4f 18 00 10 e0 07 10 20 00 06 0f 0f 33 0e 1c 2a 38 46 54 62 69 70 77 79 7b 7d 7e 02 02 22 00 2a 40 2a be 3a fc 3a fa 3a f8 3b 38 3b 78 3b b6 4b b6 4b f4 4b f4 6c 34 84 74 00 00 00 00 00 00
			39 00 00 00 00 00 04 FF 5A A5 00

			05 00 00 00 78 00 01 11 //Delay 120ms
			39 00 00 40 00 00 04 FF 5A A5 49 //OD Code
			39 00 00 40 00 00 11 81 D2 00 BC 02 C0 03 24 05 08 07 D4 0C D2 14 74 1B
			39 00 00 40 00 00 13 82 D2 00 BC 02 C0 03 24 05 08 07 D4 0C D2 14 74 1B 00 00
			39 00 00 40 00 00 02 83 0B
			39 00 00 40 00 00 04 FF 5A A5 53
			39 00 00 40 00 00 02 86 3D //Exit 165 DC code
			39 00 00 40 00 00 04 FF 5A A5 51
			39 00 00 40 00 00 07 A1 AC AC AC AC 22 22
			39 00 00 40 00 00 07 A2 AC A5 A5 A5 22 22
			39 00 00 40 00 00 07 A3 A5 98 98 98 22 22
			39 00 00 40 00 00 04 FF 5A A5 52
			39 00 00 40 00 00 07 81 E2 94 77 77 00 00
			39 00 00 40 00 00 07 82 77 76 76 76 00 00
			39 00 00 40 00 00 07 83 76 6E 6E 6E 00 00
			39 00 00 00 00 00 04 FF 5A A5 00
			05 00 00 00 14 00 01 29];	/* display on */
		qcom,mdss-dsi-off-command = [
			39 00 00 40 00 00 04 FF 5A A5 00
			05 00 00 00 14 00 01 28		/* display_off */
			05 00 00 00 BE 00 01 10];	/* enter sleep mode */
		qcom,mdss-dsi-on-command-state = "dsi_lp_mode";
		qcom,mdss-dsi-off-command-state = "dsi_lp_mode";
		qcom,mdss-dsi-timing-switch-command-state = "dsi_lp_mode";
		qcom,compression-mode = "dsc";
		/* Why QCOM doesn't use this, even it used 2 encoder
		 * as for that dsi_sw43404_amoled_cmd, for ex */
		/* qcom,mdss-dsc-encoders = <2>; */
		qcom,mdss-dsc-version = <0x12>;
		qcom,mdss-dsc-slice-height = <20>;
		qcom,mdss-dsc-slice-width = <632>;
		qcom,mdss-dsc-slice-per-pkt = <2>;
		qcom,mdss-dsc-bit-per-component = <10>;
		qcom,mdss-dsc-bit-per-pixel = <8>;
		qcom,mdss-dsc-block-prediction-enable;
		qcom,mdss-dsi-pcd-check-enable-command = [
			39 00 00 00 00 00 04 FF 5A A5 03
			];
		qcom,mdss-dsi-pcd-check-enable-command-state = "dsi_hs_mode";
		qcom,mdss-dsi-pcd-check-disable-command = [
			39 00 00 00 00 00 04 FF 5A A5 00
			];
		qcom,mdss-dsi-pcd-check-disable-command-state = "dsi_hs_mode";
	};

	timing@7{
		qcom,mdss-dsi-cmd-mode;
		qcom,mdss-dsi-panel-framerate = <120>;  /* Actually 1 hz*/
		qcom,mdss-dsi-panel-width = <1264>;
		qcom,mdss-dsi-panel-height = <2780>;
		qcom,mdss-dsi-h-front-porch = <27>;
		qcom,mdss-dsi-h-back-porch = <32>;
		qcom,mdss-dsi-h-pulse-width = <16>;
		qcom,mdss-dsi-h-sync-skew = <0>;
		qcom,mdss-dsi-h-sync-pulse = <0>;
		qcom,mdss-dsi-v-back-porch = <42>;
		qcom,mdss-dsi-v-front-porch = <58>;
		qcom,mdss-dsi-v-pulse-width = <2>;
		qcom,mdss-dsi-h-left-border = <0>;
		qcom,mdss-dsi-h-right-border = <0>;
		qcom,mdss-dsi-v-top-border = <0>;
		qcom,mdss-dsi-v-bottom-border = <0>;
	        qcom,mdss-dsi-panel-jitter = <0x20 0xa>;
	        qcom,mdss-mdp-transfer-time-us = <7933>;
	        qcom,mdss-dsi-timing-switch-command = [
			39 00 00 40 00 00 04 FF 5A A5 4F
			39 00 00 40 00 00 02 81 04
			39 00 00 40 00 00 04 FF 5A A5 08
			39 00 00 40 00 00 02 98 02
			39 00 00 40 00 00 04 FF 5A A5 4F
			39 00 00 40 00 00 02 88 78
			39 00 00 40 00 00 04 FF 5A A5 24
			39 00 00 40 00 00 02 86 00
			39 00 00 40 00 00 02 8A 00
			39 00 00 40 00 00 04 FF 5A A5 00
			39 00 00 40 00 00 02 53 20
			39 00 00 40 00 00 02 60 00
			39 00 00 40 00 00 04 FF 5A A5 2D
			39 00 00 40 00 00 03 98 00 00
			39 00 00 40 00 00 02 CD 01
			39 00 00 40 00 00 03 83 77 00
			39 00 00 40 00 00 02 F2 00
			39 00 00 40 00 00 04 FF 5A A5 53
			39 00 00 40 00 00 02 86 3D //Exit 165 DC code
			39 00 00 40 00 00 04 FF 5A A5 08
			39 00 00 40 00 00 02 98 A6
			39 00 00 40 00 00 04 FF 5A A5 00
			39 00 00 40 00 00 02 00 00
			39 00 00 40 00 00 04 FF 5A A5 4F
			39 00 00 40 00 00 02 8B 78
			39 00 00 00 00 00 04 FF 5A A5 00
	        ];
		qcom,mdss-dsi-on-command = [
			39 00 00 40 00 00 04 FF 5A A5 00 //ODC dbv420 and 10nit
			39 00 00 40 00 00 02 4D 01
			39 00 00 40 00 00 04 FF 5A A5 4F
			39 00 00 40 00 00 02 A1 00
			39 00 00 40 00 00 02 A2 01
			39 00 00 40 00 00 02 A3 A4
			39 00 00 40 00 00 02 A4 0A
			39 00 00 40 00 00 02 A5 48
			39 00 00 40 00 00 04 FF 5A A5 71
			39 00 00 40 00 00 07 85 00 80 0A F3 00 00
			39 00 00 40 00 00 07 86 00 66 09 8F 04 00
			39 00 00 40 00 00 07 87 00 60 09 36 14 00
			39 00 00 40 00 00 07 88 00 53 08 84 24 00
			39 00 00 40 00 00 07 89 00 46 07 D2 04 00
			39 00 00 40 00 00 07 8A 00 80 18 B3 00 00
			39 00 00 40 00 00 07 8B 00 66 17 C2 04 00
			39 00 00 40 00 00 07 8C 00 60 17 86 14 00
			39 00 00 40 00 00 07 8D 00 53 17 0E 24 00
			39 00 00 40 00 00 07 8E 00 46 16 95 04 00
			39 00 00 40 00 00 07 8F 00 80 26 00 00 00
			39 00 00 40 00 00 07 90 00 66 25 99 04 00
			39 00 00 40 00 00 07 91 00 60 25 80 14 00
			39 00 00 40 00 00 07 92 00 53 25 4C 24 00
			39 00 00 40 00 00 07 93 00 46 25 19 04 00
			39 00 00 40 00 00 07 94 00 80 04 00 00 00
			39 00 00 40 00 00 07 95 00 66 04 00 04 00
			39 00 00 40 00 00 07 96 00 60 04 00 14 00
			39 00 00 40 00 00 07 97 00 53 04 00 24 00
			39 00 00 40 00 00 07 98 00 46 04 00 04 00
			39 00 00 40 00 00 07 99 0C 19 00 80 00 00
			39 00 00 40 00 00 07 9A 0A 7B 00 66 04 00
			39 00 00 40 00 00 07 9B 0A 13 00 60 14 00
			39 00 00 40 00 00 07 9C 09 43 00 53 24 00
			39 00 00 40 00 00 07 9D 08 74 00 46 04 00
			39 00 00 40 00 00 07 9E 04 00 0A 00 00 00
			39 00 00 40 00 00 07 A3 04 00 16 80 00 00
			39 00 00 40 00 00 07 A4 04 00 16 00 04 00
			39 00 00 40 00 00 07 B2 19 EC 00 80 00 00
			39 00 00 40 00 00 07 B3 18 BD 00 66 04 00
			39 00 00 40 00 00 07 B4 18 71 00 60 14 00
			39 00 00 40 00 00 07 B5 17 DA 00 53 24 00
			39 00 00 40 00 00 07 B6 17 42 00 46 04 00
			39 00 00 40 00 00 07 CB 25 B9 00 80 00 00
			39 00 00 40 00 00 07 CC 25 61 00 66 04 00
			39 00 00 40 00 00 07 CD 25 4B 00 60 14 00
			39 00 00 40 00 00 07 CE 25 1F 00 53 24 00
			39 00 00 40 00 00 07 CF 24 F2 00 46 04 00
			39 00 00 40 00 00 07 E4 04 00 00 80 00 00
			39 00 00 40 00 00 07 E5 04 00 00 66 04 00
			39 00 00 40 00 00 07 E6 04 00 00 60 14 00
			39 00 00 40 00 00 07 E7 04 00 00 53 24 00
			39 00 00 40 00 00 07 E8 04 00 00 46 04 00
			39 00 00 40 00 00 04 FF 5A A5 49
			39 00 00 40 00 00 02 E0 01
			39 00 00 40 00 00 04 FF 5A A5 5B
			39 00 00 40 00 00 04 C8 03 06 01
			39 00 00 40 00 00 04 C9 04 07 01
			39 00 00 40 00 00 04 CA 00 00 00
			39 00 00 40 00 00 04 CB 06 07 03
			39 00 00 40 00 00 04 CC 01 00 00
			39 00 00 40 00 00 04 CD 00 00 00
			39 00 00 40 00 00 04 CE 09 09 07
			39 00 00 40 00 00 04 CF 03 02 02
			39 00 00 40 00 00 04 D0 02 01 01
			39 00 00 40 00 00 04 D1 00 00 00
			39 00 00 40 00 00 04 D2 16 12 13
			39 00 00 40 00 00 04 D3 09 07 07
			39 00 00 40 00 00 04 D4 07 06 06
			39 00 00 40 00 00 04 D5 03 03 02
			39 00 00 40 00 00 04 D6 00 00 00
			39 00 00 40 00 00 04 D7 19 15 16
			39 00 00 40 00 00 04 D8 0B 08 08
			39 00 00 40 00 00 04 D9 09 07 07
			39 00 00 40 00 00 04 DA 04 04 03
			39 00 00 40 00 00 04 DB 00 00 00
			39 00 00 40 00 00 04 DC 00 00 00
			39 00 00 40 00 00 04 DD 24 21 1F
			39 00 00 40 00 00 04 DE 13 10 0D
			39 00 00 40 00 00 04 DF 10 0E 0C
			39 00 00 40 00 00 04 E0 09 09 06
			39 00 00 40 00 00 04 E1 01 02 01
			39 00 00 40 00 00 04 E2 00 00 00
			39 00 00 40 00 00 04 E3 00 00 00
			39 00 00 40 00 00 04 E4 2E 2B 26
			39 00 00 40 00 00 04 E5 1B 17 12
			39 00 00 40 00 00 04 E6 18 15 10
			39 00 00 40 00 00 04 E7 0E 0F 09
			39 00 00 40 00 00 04 E8 04 04 01
			39 00 00 40 00 00 04 E9 00 00 00
			39 00 00 40 00 00 04 EA 00 00 00
			39 00 00 40 00 00 04 EB 00 00 00
			39 00 00 40 00 00 04 FF 5A A5 5C
			39 00 00 40 00 00 04 80 02 02 01
			39 00 00 40 00 00 04 81 02 02 01
			39 00 00 40 00 00 04 82 00 00 00
			39 00 00 40 00 00 04 83 04 04 02
			39 00 00 40 00 00 04 84 00 00 00
			39 00 00 40 00 00 04 85 00 00 00
			39 00 00 40 00 00 04 86 08 07 07
			39 00 00 40 00 00 04 87 02 02 01
			39 00 00 40 00 00 04 88 01 01 01
			39 00 00 40 00 00 04 89 00 00 00
			39 00 00 40 00 00 04 8A 13 11 10
			39 00 00 40 00 00 04 8B 07 07 05
			39 00 00 40 00 00 04 8C 06 06 04
			39 00 00 40 00 00 04 8D 01 02 01
			39 00 00 40 00 00 04 8E 00 00 00
			39 00 00 40 00 00 04 8F 16 14 12
			39 00 00 40 00 00 04 90 09 08 06
			39 00 00 40 00 00 04 91 07 07 04
			39 00 00 40 00 00 04 92 02 02 01
			39 00 00 40 00 00 04 93 00 00 00
			39 00 00 40 00 00 04 94 00 00 00
			39 00 00 40 00 00 04 95 30 2C 18
			39 00 00 40 00 00 04 96 0E 0D 08
			39 00 00 40 00 00 04 97 0B 0B 06
			39 00 00 40 00 00 04 98 05 05 01
			39 00 00 40 00 00 04 99 01 01 00
			39 00 00 40 00 00 04 9A 00 00 00
			39 00 00 40 00 00 04 9B 00 00 00
			39 00 00 40 00 00 04 9C 45 33 1D
			39 00 00 40 00 00 04 9D 12 11 09
			39 00 00 40 00 00 04 9E 0F 0F 07
			39 00 00 40 00 00 04 9F 07 08 01
			39 00 00 40 00 00 04 A0 01 01 00
			39 00 00 40 00 00 04 A1 00 00 00
			39 00 00 40 00 00 04 A2 00 00 00
			39 00 00 40 00 00 04 A3 00 00 00
			39 00 00 40 00 00 04 CE 10 18 10
			39 00 00 40 00 00 04 CF 10 18 10

			39 00 00 40 00 00 04 FF 5A A5 06 //esd check
			39 00 00 40 00 00 02 C6 01
			39 00 00 40 00 00 04 FF 5A A5 08
			39 00 00 40 00 00 02 D2 05
			39 00 00 40 00 00 09 ED FF FF FF FF FF FF 45 FF
			39 00 00 40 00 00 09 EE FF FD FF FD F9 FA BE 76
			39 00 00 40 00 00 04 FF 5A A5 00

			39 00 00 40 00 00 04 FF 5A A5 03 //Power on code
			39 00 00 40 00 00 04 90 01 80 23
			39 00 00 40 00 00 04 FF 5A A5 08
			39 00 00 40 00 00 02 E0 22
			39 00 00 40 00 00 04 FF 5A A5 09
			39 00 00 40 00 00 02 A1 03
			39 00 00 40 00 00 04 FF 5A A5 1E
			39 00 00 40 00 00 02 C1 70
			39 00 00 40 00 00 04 FF 5A A5 05
			39 00 00 40 00 00 02 83 01
			39 00 00 40 00 00 02 84 01
			39 00 00 40 00 00 04 FF 5A A5 1C
			39 00 00 40 00 00 15 E1 10 80 9A 65 59 54 69 95 56 6A 55 99 9A 55 55 25 58 55 66 A2
			39 00 00 40 00 00 04 FF 5A A5 20
			39 00 00 40 00 00 02 D5 10
			39 00 00 40 00 00 02 BC 06
			39 00 00 40 00 00 04 FF 5A A5 02
			39 00 00 40 00 00 03 AB AF 86

			39 00 00 40 00 00 04 FF 5A A5 4B //pcd check code
			39 00 00 40 00 00 02 EE 10
			39 00 00 40 00 00 04 FF 5A A5 03
			39 00 00 40 00 00 02 BD D1
			39 00 00 40 00 00 02 BB 29
			39 00 00 40 00 00 04 FF 5A A5 1C
			39 00 00 40 00 00 02 D3 43

			39 00 00 40 00 00 04 FF 5A A5 08
			39 00 00 40 00 00 02 C8 62
			39 00 00 40 00 00 04 FF 5A A5 21
			39 00 00 40 00 00 02 A4 38
			39 00 00 40 00 00 04 FF 5A A5 23
			39 00 00 40 00 00 02 85 15
			39 00 00 40 00 00 04 FF 5A A5 01
			39 00 00 40 00 00 02 FB 08
			39 00 00 40 00 00 04 FF 5A A5 00
			39 00 00 40 00 00 02 5E 01
			39 00 00 40 00 00 02 60 00
			39 00 00 40 00 00 02 61 08
			39 00 00 40 00 00 01 35
			39 00 00 40 00 00 02 53 20
			39 00 00 40 00 00 03 51 00 00

			39 00 00 40 00 00 04 FF 5A A5 24 //DBV Diming
			39 00 00 40 00 00 02 85 31
			39 00 00 40 00 00 02 89 31
			39 00 00 40 00 00 04 FF 5A A5 2D
			39 00 00 40 00 00 02 CE 55
			39 00 00 40 00 00 04 FF 5A A5 5A //OD LUT
			39 00 00 40 00 00 04 80 00 01 00
			39 00 00 40 00 00 04 81 00 02 01
			39 00 00 40 00 00 04 82 00 00 00
			39 00 00 40 00 00 04 83 03 0B 04
			39 00 00 40 00 00 04 84 02 05 00
			39 00 00 40 00 00 04 85 02 05 00
			39 00 00 40 00 00 04 86 11 24 11
			39 00 00 40 00 00 04 87 0B 0A 03
			39 00 00 40 00 00 04 88 09 08 03
			39 00 00 40 00 00 04 89 05 04 03
			39 00 00 40 00 00 04 8A 1A 1E 21
			39 00 00 40 00 00 04 8B 11 0D 0F
			39 00 00 40 00 00 04 8C 11 0B 0D
			39 00 00 40 00 00 04 8D 0B 07 0B
			39 00 00 40 00 00 04 8E 05 04 08
			39 00 00 40 00 00 04 8F 26 26 26
			39 00 00 40 00 00 04 90 15 0E 13
			39 00 00 40 00 00 04 91 14 0C 12
			39 00 00 40 00 00 04 92 0F 08 0F
			39 00 00 40 00 00 04 93 08 05 0B
			39 00 00 40 00 00 04 94 00 00 00
			39 00 00 40 00 00 04 95 3E 32 32
			39 00 00 40 00 00 04 96 24 14 26
			39 00 00 40 00 00 04 97 21 12 21
			39 00 00 40 00 00 04 98 1D 10 20
			39 00 00 40 00 00 04 99 12 0B 16
			39 00 00 40 00 00 04 9A 09 05 0B
			39 00 00 40 00 00 04 9B 06 03 08
			39 00 00 40 00 00 04 9C 32 35 2D
			39 00 00 40 00 00 04 9D 36 19 2C
			39 00 00 40 00 00 04 9E 32 18 30
			39 00 00 40 00 00 04 9F 2A 16 29
			39 00 00 40 00 00 04 A0 1D 12 21
			39 00 00 40 00 00 04 A1 12 09 15
			39 00 00 40 00 00 04 A2 0F 07 11
			39 00 00 40 00 00 04 FF 5A A5 5C
			39 00 00 40 00 00 04 C8 0C 0A 05

			39 00 00 40 00 00 04 FF 5A A5 24 //switch 1hz
			39 00 00 40 00 00 02 86 00
			39 00 00 40 00 00 02 8A 00
			39 00 00 40 00 00 04 FF 5A A5 00
			39 00 00 40 00 00 02 53 20
			39 00 00 40 00 00 02 60 00
			39 00 00 40 00 00 04 FF 5A A5 2D
			39 00 00 40 00 00 03 98 00 00
			39 00 00 40 00 00 02 CD 01
			39 00 00 40 00 00 03 83 77 00
			39 00 00 40 00 00 02 F2 00

			39 00 00 40 00 00 04 FF 5A A5 07 //10bit 3.75
			39 00 00 40 00 00 02 8A 01
			39 00 00 40 00 00 03 8B 21 E0
			39 00 00 40 00 00 64 81 00 00 00 00 00 12 00 00 ab 30 80 0a dc 04 f0 00 14 02 78 02 78 02 00 02 57 00 20 01 f8 00 08 00 0d 05 7a 04 4f 18 00 10 e0 07 10 20 00 06 0f 0f 33 0e 1c 2a 38 46 54 62 69 70 77 79 7b 7d 7e 02 02 22 00 2a 40 2a be 3a fc 3a fa 3a f8 3b 38 3b 78 3b b6 4b b6 4b f4 4b f4 6c 34 84 74 00 00 00 00 00 00
			39 00 00 00 00 00 04 FF 5A A5 00

			05 00 00 00 78 00 01 11 //Delay 120ms
			39 00 00 40 00 00 04 FF 5A A5 49 //OD Code
			39 00 00 40 00 00 11 81 D2 00 BC 02 C0 03 24 05 08 07 D4 0C D2 14 74 1B
			39 00 00 40 00 00 13 82 D2 00 BC 02 C0 03 24 05 08 07 D4 0C D2 14 74 1B 00 00
			39 00 00 40 00 00 02 83 0B
			39 00 00 40 00 00 04 FF 5A A5 53
			39 00 00 40 00 00 02 86 3D //Exit 165 DC code
			39 00 00 40 00 00 04 FF 5A A5 51
			39 00 00 40 00 00 07 A1 AC AC AC AC 22 22
			39 00 00 40 00 00 07 A2 AC A5 A5 A5 22 22
			39 00 00 40 00 00 07 A3 A5 98 98 98 22 22
			39 00 00 40 00 00 04 FF 5A A5 52
			39 00 00 40 00 00 07 81 E2 94 77 77 00 00
			39 00 00 40 00 00 07 82 77 76 76 76 00 00
			39 00 00 40 00 00 07 83 76 6E 6E 6E 00 00
			39 00 00 00 00 00 04 FF 5A A5 00
			05 00 00 00 14 00 01 29];	/* display on */
		qcom,mdss-dsi-off-command = [
			39 00 00 40 00 00 04 FF 5A A5 00
			05 00 00 00 14 00 01 28		/* display_off */
			05 00 00 00 BE 00 01 10];	/* enter sleep mode */

		qcom,mdss-dsi-on-command-state = "dsi_lp_mode";
		qcom,mdss-dsi-off-command-state = "dsi_lp_mode";
		qcom,mdss-dsi-timing-switch-command-state = "dsi_lp_mode";
		qcom,compression-mode = "dsc";
		/* Why QCOM doesn't use this, even it used 2 encoder
		 * as for that dsi_sw43404_amoled_cmd, for ex */
		/* qcom,mdss-dsc-encoders = <2>; */
		qcom,mdss-dsc-version = <0x12>;
		qcom,mdss-dsc-slice-height = <20>;
		qcom,mdss-dsc-slice-width = <632>;
		qcom,mdss-dsc-slice-per-pkt = <2>;
		qcom,mdss-dsc-bit-per-component = <10>;
		qcom,mdss-dsc-bit-per-pixel = <8>;
		qcom,mdss-dsc-block-prediction-enable;
		qcom,mdss-dsi-pcd-check-enable-command = [
			39 00 00 00 00 00 04 FF 5A A5 03
			];
		qcom,mdss-dsi-pcd-check-enable-command-state = "dsi_hs_mode";
		qcom,mdss-dsi-pcd-check-disable-command = [
			39 00 00 00 00 00 04 FF 5A A5 00
			];
		qcom,mdss-dsi-pcd-check-disable-command-state = "dsi_hs_mode";
	};

	timing@8{
		qcom,mdss-dsi-cmd-mode;
		qcom,mdss-dsi-panel-framerate = <120>;
		qcom,mdss-dsi-panel-width = <1264>;
		qcom,mdss-dsi-panel-height = <2780>;
		qcom,mdss-dsi-h-front-porch = <30>;
		qcom,mdss-dsi-h-back-porch = <32>;
		qcom,mdss-dsi-h-pulse-width = <16>;
		qcom,mdss-dsi-h-sync-skew = <0>;
		qcom,mdss-dsi-h-sync-pulse = <0>;
		qcom,mdss-dsi-v-back-porch = <42>;
		qcom,mdss-dsi-v-front-porch = <58>;
		qcom,mdss-dsi-v-pulse-width = <2>;
		qcom,mdss-dsi-h-left-border = <0>;
		qcom,mdss-dsi-h-right-border = <0>;
		qcom,mdss-dsi-v-top-border = <0>;
		qcom,mdss-dsi-v-bottom-border = <0>;
	        qcom,mdss-dsi-panel-jitter = <0x20 0xa>;
	        qcom,mdss-dsi-timing-switch-command = [
			39 00 00 40 00 00 04 FF 5A A5 00
			39 00 00 40 00 00 02 53 20
			39 00 00 40 00 00 02 60 00
			39 00 00 40 00 00 04 FF 5A A5 24
			39 00 00 40 00 00 02 86 00
			39 00 00 40 00 00 02 8A 00
			39 00 00 40 00 00 04 FF 5A A5 2D
			39 00 00 40 00 00 03 98 00 00
			39 00 00 40 00 00 02 CD 01
			39 00 00 40 00 00 03 83 00 00
			39 00 00 40 00 00 02 F2 00 // 120Hz Frame Skip mode Exit
			39 00 00 40 00 00 04 FF 5A A5 53
			39 00 00 40 00 00 02 86 3D //Exit 165 DC code
			39 00 00 00 00 00 04 FF 5A A5 00
	        ];
		qcom,mdss-dsi-on-command = [
			39 00 00 40 00 00 04 FF 5A A5 00 //ODC dbv420 and 10nit
			39 00 00 40 00 00 02 4D 01
			39 00 00 40 00 00 04 FF 5A A5 4F
			39 00 00 40 00 00 02 A1 00
			39 00 00 40 00 00 02 A2 01
			39 00 00 40 00 00 02 A3 A4
			39 00 00 40 00 00 02 A4 0A
			39 00 00 40 00 00 02 A5 48
			39 00 00 40 00 00 04 FF 5A A5 71
			39 00 00 40 00 00 07 85 00 80 0A F3 00 00
			39 00 00 40 00 00 07 86 00 66 09 8F 04 00
			39 00 00 40 00 00 07 87 00 60 09 36 14 00
			39 00 00 40 00 00 07 88 00 53 08 84 24 00
			39 00 00 40 00 00 07 89 00 46 07 D2 04 00
			39 00 00 40 00 00 07 8A 00 80 18 B3 00 00
			39 00 00 40 00 00 07 8B 00 66 17 C2 04 00
			39 00 00 40 00 00 07 8C 00 60 17 86 14 00
			39 00 00 40 00 00 07 8D 00 53 17 0E 24 00
			39 00 00 40 00 00 07 8E 00 46 16 95 04 00
			39 00 00 40 00 00 07 8F 00 80 26 00 00 00
			39 00 00 40 00 00 07 90 00 66 25 99 04 00
			39 00 00 40 00 00 07 91 00 60 25 80 14 00
			39 00 00 40 00 00 07 92 00 53 25 4C 24 00
			39 00 00 40 00 00 07 93 00 46 25 19 04 00
			39 00 00 40 00 00 07 94 00 80 04 00 00 00
			39 00 00 40 00 00 07 95 00 66 04 00 04 00
			39 00 00 40 00 00 07 96 00 60 04 00 14 00
			39 00 00 40 00 00 07 97 00 53 04 00 24 00
			39 00 00 40 00 00 07 98 00 46 04 00 04 00
			39 00 00 40 00 00 07 99 0C 19 00 80 00 00
			39 00 00 40 00 00 07 9A 0A 7B 00 66 04 00
			39 00 00 40 00 00 07 9B 0A 13 00 60 14 00
			39 00 00 40 00 00 07 9C 09 43 00 53 24 00
			39 00 00 40 00 00 07 9D 08 74 00 46 04 00
			39 00 00 40 00 00 07 9E 04 00 0A 00 00 00
			39 00 00 40 00 00 07 A3 04 00 16 80 00 00
			39 00 00 40 00 00 07 A4 04 00 16 00 04 00
			39 00 00 40 00 00 07 B2 19 EC 00 80 00 00
			39 00 00 40 00 00 07 B3 18 BD 00 66 04 00
			39 00 00 40 00 00 07 B4 18 71 00 60 14 00
			39 00 00 40 00 00 07 B5 17 DA 00 53 24 00
			39 00 00 40 00 00 07 B6 17 42 00 46 04 00
			39 00 00 40 00 00 07 CB 25 B9 00 80 00 00
			39 00 00 40 00 00 07 CC 25 61 00 66 04 00
			39 00 00 40 00 00 07 CD 25 4B 00 60 14 00
			39 00 00 40 00 00 07 CE 25 1F 00 53 24 00
			39 00 00 40 00 00 07 CF 24 F2 00 46 04 00
			39 00 00 40 00 00 07 E4 04 00 00 80 00 00
			39 00 00 40 00 00 07 E5 04 00 00 66 04 00
			39 00 00 40 00 00 07 E6 04 00 00 60 14 00
			39 00 00 40 00 00 07 E7 04 00 00 53 24 00
			39 00 00 40 00 00 07 E8 04 00 00 46 04 00
			39 00 00 40 00 00 04 FF 5A A5 49
			39 00 00 40 00 00 02 E0 01
			39 00 00 40 00 00 04 FF 5A A5 5B
			39 00 00 40 00 00 04 C8 03 06 01
			39 00 00 40 00 00 04 C9 04 07 01
			39 00 00 40 00 00 04 CA 00 00 00
			39 00 00 40 00 00 04 CB 06 07 03
			39 00 00 40 00 00 04 CC 01 00 00
			39 00 00 40 00 00 04 CD 00 00 00
			39 00 00 40 00 00 04 CE 09 09 07
			39 00 00 40 00 00 04 CF 03 02 02
			39 00 00 40 00 00 04 D0 02 01 01
			39 00 00 40 00 00 04 D1 00 00 00
			39 00 00 40 00 00 04 D2 16 12 13
			39 00 00 40 00 00 04 D3 09 07 07
			39 00 00 40 00 00 04 D4 07 06 06
			39 00 00 40 00 00 04 D5 03 03 02
			39 00 00 40 00 00 04 D6 00 00 00
			39 00 00 40 00 00 04 D7 19 15 16
			39 00 00 40 00 00 04 D8 0B 08 08
			39 00 00 40 00 00 04 D9 09 07 07
			39 00 00 40 00 00 04 DA 04 04 03
			39 00 00 40 00 00 04 DB 00 00 00
			39 00 00 40 00 00 04 DC 00 00 00
			39 00 00 40 00 00 04 DD 24 21 1F
			39 00 00 40 00 00 04 DE 13 10 0D
			39 00 00 40 00 00 04 DF 10 0E 0C
			39 00 00 40 00 00 04 E0 09 09 06
			39 00 00 40 00 00 04 E1 01 02 01
			39 00 00 40 00 00 04 E2 00 00 00
			39 00 00 40 00 00 04 E3 00 00 00
			39 00 00 40 00 00 04 E4 2E 2B 26
			39 00 00 40 00 00 04 E5 1B 17 12
			39 00 00 40 00 00 04 E6 18 15 10
			39 00 00 40 00 00 04 E7 0E 0F 09
			39 00 00 40 00 00 04 E8 04 04 01
			39 00 00 40 00 00 04 E9 00 00 00
			39 00 00 40 00 00 04 EA 00 00 00
			39 00 00 40 00 00 04 EB 00 00 00
			39 00 00 40 00 00 04 FF 5A A5 5C
			39 00 00 40 00 00 04 80 02 02 01
			39 00 00 40 00 00 04 81 02 02 01
			39 00 00 40 00 00 04 82 00 00 00
			39 00 00 40 00 00 04 83 04 04 02
			39 00 00 40 00 00 04 84 00 00 00
			39 00 00 40 00 00 04 85 00 00 00
			39 00 00 40 00 00 04 86 08 07 07
			39 00 00 40 00 00 04 87 02 02 01
			39 00 00 40 00 00 04 88 01 01 01
			39 00 00 40 00 00 04 89 00 00 00
			39 00 00 40 00 00 04 8A 13 11 10
			39 00 00 40 00 00 04 8B 07 07 05
			39 00 00 40 00 00 04 8C 06 06 04
			39 00 00 40 00 00 04 8D 01 02 01
			39 00 00 40 00 00 04 8E 00 00 00
			39 00 00 40 00 00 04 8F 16 14 12
			39 00 00 40 00 00 04 90 09 08 06
			39 00 00 40 00 00 04 91 07 07 04
			39 00 00 40 00 00 04 92 02 02 01
			39 00 00 40 00 00 04 93 00 00 00
			39 00 00 40 00 00 04 94 00 00 00
			39 00 00 40 00 00 04 95 30 2C 18
			39 00 00 40 00 00 04 96 0E 0D 08
			39 00 00 40 00 00 04 97 0B 0B 06
			39 00 00 40 00 00 04 98 05 05 01
			39 00 00 40 00 00 04 99 01 01 00
			39 00 00 40 00 00 04 9A 00 00 00
			39 00 00 40 00 00 04 9B 00 00 00
			39 00 00 40 00 00 04 9C 45 33 1D
			39 00 00 40 00 00 04 9D 12 11 09
			39 00 00 40 00 00 04 9E 0F 0F 07
			39 00 00 40 00 00 04 9F 07 08 01
			39 00 00 40 00 00 04 A0 01 01 00
			39 00 00 40 00 00 04 A1 00 00 00
			39 00 00 40 00 00 04 A2 00 00 00
			39 00 00 40 00 00 04 A3 00 00 00
			39 00 00 40 00 00 04 CE 10 18 10
			39 00 00 40 00 00 04 CF 10 18 10

			39 00 00 40 00 00 04 FF 5A A5 06 //esd check
			39 00 00 40 00 00 02 C6 01
			39 00 00 40 00 00 04 FF 5A A5 08
			39 00 00 40 00 00 02 D2 05
			39 00 00 40 00 00 09 ED FF FF FF FF FF FF 45 FF
			39 00 00 40 00 00 09 EE FF FD FF FD F9 FA BE 76
			39 00 00 40 00 00 04 FF 5A A5 00

			39 00 00 40 00 00 04 FF 5A A5 03 //Power on code
			39 00 00 40 00 00 04 90 01 80 23
			39 00 00 40 00 00 04 FF 5A A5 08
			39 00 00 40 00 00 02 E0 22
			39 00 00 40 00 00 04 FF 5A A5 09
			39 00 00 40 00 00 02 A1 03
			39 00 00 40 00 00 04 FF 5A A5 1E
			39 00 00 40 00 00 02 C1 70
			39 00 00 40 00 00 04 FF 5A A5 05
			39 00 00 40 00 00 02 83 01
			39 00 00 40 00 00 02 84 01
			39 00 00 40 00 00 04 FF 5A A5 1C
			39 00 00 40 00 00 15 E1 10 80 9A 65 59 54 69 95 56 6A 55 99 9A 55 55 25 58 55 66 A2
			39 00 00 40 00 00 04 FF 5A A5 20
			39 00 00 40 00 00 02 D5 10
			39 00 00 40 00 00 02 BC 06
			39 00 00 40 00 00 04 FF 5A A5 02
			39 00 00 40 00 00 03 AB AF 86

			39 00 00 40 00 00 04 FF 5A A5 4B //pcd check code
			39 00 00 40 00 00 02 EE 10
			39 00 00 40 00 00 04 FF 5A A5 03
			39 00 00 40 00 00 02 BD D1
			39 00 00 40 00 00 02 BB 29
			39 00 00 40 00 00 04 FF 5A A5 1C
			39 00 00 40 00 00 02 D3 43

			39 00 00 40 00 00 04 FF 5A A5 08
			39 00 00 40 00 00 02 C8 62
			39 00 00 40 00 00 04 FF 5A A5 21
			39 00 00 40 00 00 02 A4 38
			39 00 00 40 00 00 04 FF 5A A5 23
			39 00 00 40 00 00 02 85 15
			39 00 00 40 00 00 04 FF 5A A5 01
			39 00 00 40 00 00 02 FB 08
			39 00 00 40 00 00 04 FF 5A A5 00
			39 00 00 40 00 00 02 5E 01
			39 00 00 40 00 00 02 60 00
			39 00 00 40 00 00 02 61 08
			39 00 00 40 00 00 01 35
			39 00 00 40 00 00 02 53 20
			39 00 00 40 00 00 03 51 00 00

			39 00 00 40 00 00 04 FF 5A A5 24 //DBV Diming
			39 00 00 40 00 00 02 85 31
			39 00 00 40 00 00 02 89 31
			39 00 00 40 00 00 04 FF 5A A5 2D
			39 00 00 40 00 00 02 CE 55
			39 00 00 40 00 00 04 FF 5A A5 5A //OD LUT
			39 00 00 40 00 00 04 80 00 01 00
			39 00 00 40 00 00 04 81 00 02 01
			39 00 00 40 00 00 04 82 00 00 00
			39 00 00 40 00 00 04 83 03 0B 04
			39 00 00 40 00 00 04 84 02 05 00
			39 00 00 40 00 00 04 85 02 05 00
			39 00 00 40 00 00 04 86 11 24 11
			39 00 00 40 00 00 04 87 0B 0A 03
			39 00 00 40 00 00 04 88 09 08 03
			39 00 00 40 00 00 04 89 05 04 03
			39 00 00 40 00 00 04 8A 1A 1E 21
			39 00 00 40 00 00 04 8B 11 0D 0F
			39 00 00 40 00 00 04 8C 11 0B 0D
			39 00 00 40 00 00 04 8D 0B 07 0B
			39 00 00 40 00 00 04 8E 05 04 08
			39 00 00 40 00 00 04 8F 26 26 26
			39 00 00 40 00 00 04 90 15 0E 13
			39 00 00 40 00 00 04 91 14 0C 12
			39 00 00 40 00 00 04 92 0F 08 0F
			39 00 00 40 00 00 04 93 08 05 0B
			39 00 00 40 00 00 04 94 00 00 00
			39 00 00 40 00 00 04 95 3E 32 32
			39 00 00 40 00 00 04 96 24 14 26
			39 00 00 40 00 00 04 97 21 12 21
			39 00 00 40 00 00 04 98 1D 10 20
			39 00 00 40 00 00 04 99 12 0B 16
			39 00 00 40 00 00 04 9A 09 05 0B
			39 00 00 40 00 00 04 9B 06 03 08
			39 00 00 40 00 00 04 9C 32 35 2D
			39 00 00 40 00 00 04 9D 36 19 2C
			39 00 00 40 00 00 04 9E 32 18 30
			39 00 00 40 00 00 04 9F 2A 16 29
			39 00 00 40 00 00 04 A0 1D 12 21
			39 00 00 40 00 00 04 A1 12 09 15
			39 00 00 40 00 00 04 A2 0F 07 11
			39 00 00 40 00 00 04 FF 5A A5 5C
			39 00 00 40 00 00 04 C8 0C 0A 05

			39 00 00 40 00 00 04 FF 5A A5 00 //switch 120hz
			39 00 00 40 00 00 02 53 20
			39 00 00 40 00 00 02 60 00
			39 00 00 40 00 00 04 FF 5A A5 24
			39 00 00 40 00 00 02 86 00
			39 00 00 40 00 00 02 8A 00
			39 00 00 40 00 00 04 FF 5A A5 2D
			39 00 00 40 00 00 03 98 00 00
			39 00 00 40 00 00 02 CD 01
			39 00 00 40 00 00 03 83 00 00
			39 00 00 40 00 00 02 F2 00 // 120Hz Frame Skip mode Exit
			39 00 00 40 00 00 04 FF 5A A5 53
			39 00 00 40 00 00 02 86 3D //Exit 165 DC code
			39 00 00 40 00 00 04 FF 5A A5 00

			39 00 00 40 00 00 04 FF 5A A5 07 //10bit 3.75
			39 00 00 40 00 00 02 8A 01
			39 00 00 40 00 00 03 8B 21 E0
			39 00 00 40 00 00 64 81 00 00 00 00 00 12 00 00 ab 30 80 0a dc 04 f0 00 14 02 78 02 78 02 00 02 57 00 20 01 f8 00 08 00 0d 05 7a 04 4f 18 00 10 e0 07 10 20 00 06 0f 0f 33 0e 1c 2a 38 46 54 62 69 70 77 79 7b 7d 7e 02 02 22 00 2a 40 2a be 3a fc 3a fa 3a f8 3b 38 3b 78 3b b6 4b b6 4b f4 4b f4 6c 34 84 74 00 00 00 00 00 00
			39 00 00 40 00 00 04 FF 5A A5 00

			39 00 00 40 00 00 04 FF 5A A5 2D //120hz VRR enable
			39 00 00 40 00 00 03 83 77 00
			39 00 00 40 00 00 02 97 03
			39 00 00 40 00 00 02 B1 03
			39 00 00 40 00 00 03 98 03 00
			39 00 00 40 00 00 03 99 05 00
			39 00 00 40 00 00 03 9A 0B 00
			39 00 00 40 00 00 03 9B 17 00
			39 00 00 40 00 00 03 A0 00 00
			39 00 00 40 00 00 03 A1 01 02
			39 00 00 00 00 00 04 FF 5A A5 00

			05 00 00 00 78 00 01 11 //Delay 120ms
			39 00 00 40 00 00 04 FF 5A A5 49 //OD Code
			39 00 00 40 00 00 11 81 D2 00 BC 02 C0 03 24 05 08 07 D4 0C D2 14 74 1B
			39 00 00 40 00 00 13 82 D2 00 BC 02 C0 03 24 05 08 07 D4 0C D2 14 74 1B 00 00
			39 00 00 40 00 00 02 83 0B
			39 00 00 40 00 00 04 FF 5A A5 53
			39 00 00 40 00 00 02 86 3D //Exit 165 DC code
			39 00 00 40 00 00 04 FF 5A A5 51
			39 00 00 40 00 00 07 A1 AC AC AC AC 22 22
			39 00 00 40 00 00 07 A2 AC A5 A5 A5 22 22
			39 00 00 40 00 00 07 A3 A5 98 98 98 22 22
			39 00 00 40 00 00 04 FF 5A A5 52
			39 00 00 40 00 00 07 81 E2 94 77 77 00 00
			39 00 00 40 00 00 07 82 77 76 76 76 00 00
			39 00 00 40 00 00 07 83 76 6E 6E 6E 00 00
			39 00 00 00 00 00 04 FF 5A A5 00
			05 00 00 00 14 00 01 29];	/* display on */
		qcom,mdss-dsi-off-command = [
			39 00 00 40 00 00 04 FF 5A A5 00
			05 00 00 00 14 00 01 28		/* display_off */
			05 00 00 00 BE 00 01 10];	/* enter sleep mode */

		qcom,mdss-dsi-on-command-state = "dsi_lp_mode";
		qcom,mdss-dsi-off-command-state = "dsi_lp_mode";
		qcom,mdss-dsi-timing-switch-command-state = "dsi_lp_mode";
		qcom,compression-mode = "dsc";
		// Why QCOM doesn't use this, even it used 2 encoder
		// as for that dsi_sw43404_amoled_cmd, for ex
		// qcom,mdss-dsc-encoders = <2>;
		qcom,mdss-dsc-version = <0x12>;
		qcom,mdss-dsc-slice-height = <20>;
		qcom,mdss-dsc-slice-width = <632>;
		qcom,mdss-dsc-slice-per-pkt = <2>;
		qcom,mdss-dsc-bit-per-component = <10>;
		qcom,mdss-dsc-bit-per-pixel = <8>;
		qcom,mdss-dsc-block-prediction-enable;

		qcom,mdss-dsi-qsync-on-commands = [
			//single TE enable
			39 00 00 40 00 00 04 FF 5A A5 2D
			39 00 00 40 00 00 03 83 77 00
			39 00 00 40 00 00 04 FF 5A A5 02
			39 00 00 40 00 00 03 B0 00 80
			39 00 00 40 00 00 04 FF 5A A5 20
			39 00 00 40 00 00 02 BC 07
			39 00 00 00 00 00 04 FF 5A A5 00
		];
		qcom,mdss-dsi-qsync-on-commands-state = "dsi_hs_mode";
		qcom,mdss-dsi-qsync-off-commands = [
			//single TE disable
			39 00 00 40 00 00 04 FF 5A A5 2D
			39 00 00 40 00 00 03 83 00 00
			39 00 00 40 00 00 04 FF 5A A5 02
			39 00 00 40 00 00 03 B0 00 00
			39 00 00 40 00 00 04 FF 5A A5 20
			39 00 00 40 00 00 02 BC 06
			39 00 00 00 00 00 04 FF 5A A5 00
		];
		qcom,mdss-dsi-qsync-off-commands-state = "dsi_hs_mode";
		qcom,mdss-dsi-pcd-check-enable-command = [
			39 00 00 00 00 00 04 FF 5A A5 03
			];
		qcom,mdss-dsi-pcd-check-enable-command-state = "dsi_hs_mode";
		qcom,mdss-dsi-pcd-check-disable-command = [
			39 00 00 00 00 00 04 FF 5A A5 00
			];
		qcom,mdss-dsi-pcd-check-disable-command-state = "dsi_hs_mode";
	};
};

};

};
